VERSION ""

NS_ :

BS_:

BU_: TESTECU BIANSUXIANG SCR EBSECU DisPlay EngineECU

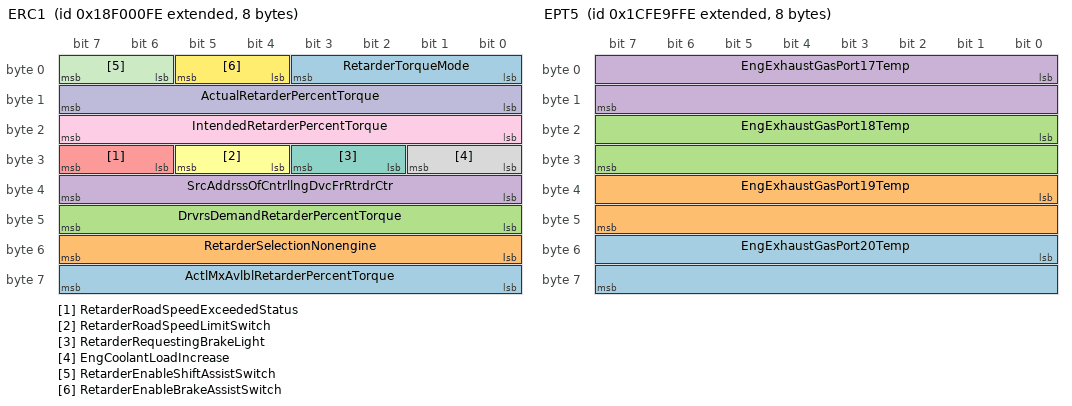
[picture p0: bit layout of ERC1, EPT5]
BO_ 2565865726 ERC1: 8 Vector__XXX
 SG_ ActlMxAvlblRetarderPercentTorque : 56|8@1+ (1,-125) [-125|125] "%" Vector__XXX
 SG_ RetarderSelectionNonengine : 48|8@1+ (0.4,0) [0|100] "%" Vector__XXX
 SG_ DrvrsDemandRetarderPercentTorque : 40|8@1+ (1,-125) [-125|125] "%" Vector__XXX
 SG_ SrcAddrssOfCntrllngDvcFrRtrdrCtr : 32|8@1+ (1,0) [0|255] "" Vector__XXX
 SG_ RetarderRoadSpeedExceededStatus : 30|2@1+ (1,0) [0|3] "" Vector__XXX
 SG_ RetarderRoadSpeedLimitSwitch : 28|2@1+ (1,0) [0|3] "" Vector__XXX
 SG_ RetarderRequestingBrakeLight : 26|2@1+ (1,0) [0|3] "" Vector__XXX
 SG_ EngCoolantLoadIncrease : 24|2@1+ (1,0) [0|3] "" Vector__XXX
 SG_ IntendedRetarderPercentTorque : 16|8@1+ (1,-125) [-125|125] "%" Vector__XXX
 SG_ ActualRetarderPercentTorque : 8|8@1+ (1,-125) [-125|125] "%" Vector__XXX
 SG_ RetarderEnableShiftAssistSwitch : 6|2@1+ (1,0) [0|3] "" Vector__XXX
 SG_ RetarderEnableBrakeAssistSwitch : 4|2@1+ (1,0) [0|3] "" Vector__XXX
 SG_ RetarderTorqueMode : 0|4@1+ (1,0) [0|15] "" Vector__XXX

BO_ 2633932798 EPT5: 8 Vector__XXX
 SG_ EngExhaustGasPort20Temp : 48|16@1+ (0.03125,-273) [-273|1734.96875] "deg C" Vector__XXX
 SG_ EngExhaustGasPort19Temp : 32|16@1+ (0.03125,-273) [-273|1734.96875] "deg C" Vector__XXX
 SG_ EngExhaustGasPort18Temp : 16|16@1+ (0.03125,-273) [-273|1734.96875] "deg C" Vector__XXX
 SG_ EngExhaustGasPort17Temp : 0|16@1+ (0.03125,-273) [-273|1734.96875] "deg C" Vector__XXX

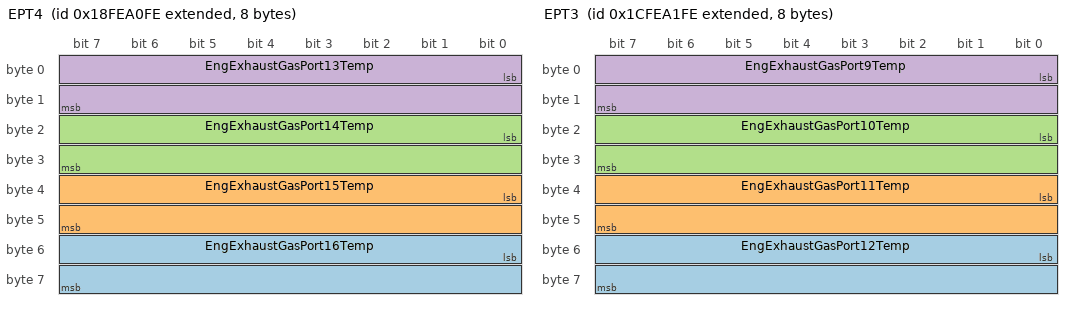
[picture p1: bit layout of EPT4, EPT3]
BO_ 2566824190 EPT4: 8 Vector__XXX
 SG_ EngExhaustGasPort16Temp : 48|16@1+ (0.03125,-273) [-273|1734.96875] "deg C" Vector__XXX
 SG_ EngExhaustGasPort15Temp : 32|16@1+ (0.03125,-273) [-273|1734.96875] "deg C" Vector__XXX
 SG_ EngExhaustGasPort14Temp : 16|16@1+ (0.03125,-273) [-273|1734.96875] "deg C" Vector__XXX
 SG_ EngExhaustGasPort13Temp : 0|16@1+ (0.03125,-273) [-273|1734.96875] "deg C" Vector__XXX

BO_ 2633933310 EPT3: 8 Vector__XXX
 SG_ EngExhaustGasPort12Temp : 48|16@1+ (0.03125,-273) [-273|1734.96875] "deg C" Vector__XXX
 SG_ EngExhaustGasPort11Temp : 32|16@1+ (0.03125,-273) [-273|1734.96875] "deg C" Vector__XXX
 SG_ EngExhaustGasPort10Temp : 16|16@1+ (0.03125,-273) [-273|1734.96875] "deg C" Vector__XXX
 SG_ EngExhaustGasPort9Temp : 0|16@1+ (0.03125,-273) [-273|1734.96875] "deg C" Vector__XXX

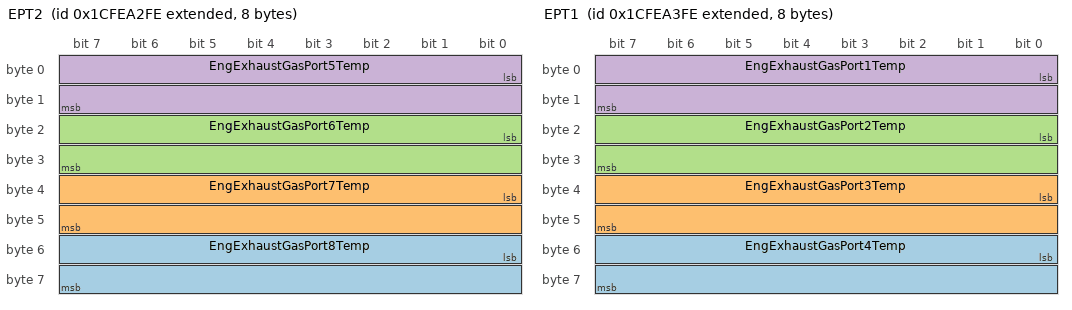
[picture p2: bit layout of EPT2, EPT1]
BO_ 2633933566 EPT2: 8 Vector__XXX
 SG_ EngExhaustGasPort8Temp : 48|16@1+ (0.03125,-273) [-273|1734.96875] "deg C" Vector__XXX
 SG_ EngExhaustGasPort7Temp : 32|16@1+ (0.03125,-273) [-273|1734.96875] "deg C" Vector__XXX
 SG_ EngExhaustGasPort6Temp : 16|16@1+ (0.03125,-273) [-273|1734.96875] "deg C" Vector__XXX
 SG_ EngExhaustGasPort5Temp : 0|16@1+ (0.03125,-273) [-273|1734.96875] "deg C" Vector__XXX

BO_ 2633933822 EPT1: 8 Vector__XXX
 SG_ EngExhaustGasPort4Temp : 48|16@1+ (0.03125,-273) [-273|1734.96875] "deg C" Vector__XXX
 SG_ EngExhaustGasPort3Temp : 32|16@1+ (0.03125,-273) [-273|1734.96875] "deg C" Vector__XXX
 SG_ EngExhaustGasPort2Temp : 16|16@1+ (0.03125,-273) [-273|1734.96875] "deg C" Vector__XXX
 SG_ EngExhaustGasPort1Temp : 0|16@1+ (0.03125,-273) [-273|1734.96875] "deg C" Vector__XXX

BO_ 2566776062 EPD: 8 Vector__XXX
 SG_ PayloadPercentage : 0|8@1+ (1,0) [0|250] "%" Vector__XXX

BO_ 2566771454 EP: 8 Vector__XXX
 SG_ DataMemoryUsage : 16|8@1+ (0.4,0) [0|100] "%" Vector__XXX
 SG_ KeepAliveBatteryConsumption : 0|16@1+ (1,0) [0|64255] "mAhr" Vector__XXX

BO_ 2566775806 EOAC: 8 Vector__XXX
 SG_ TravelVelocityCtrlPos : 0|8@1+ (1,-125) [-125|125] "%" Vector__XXX

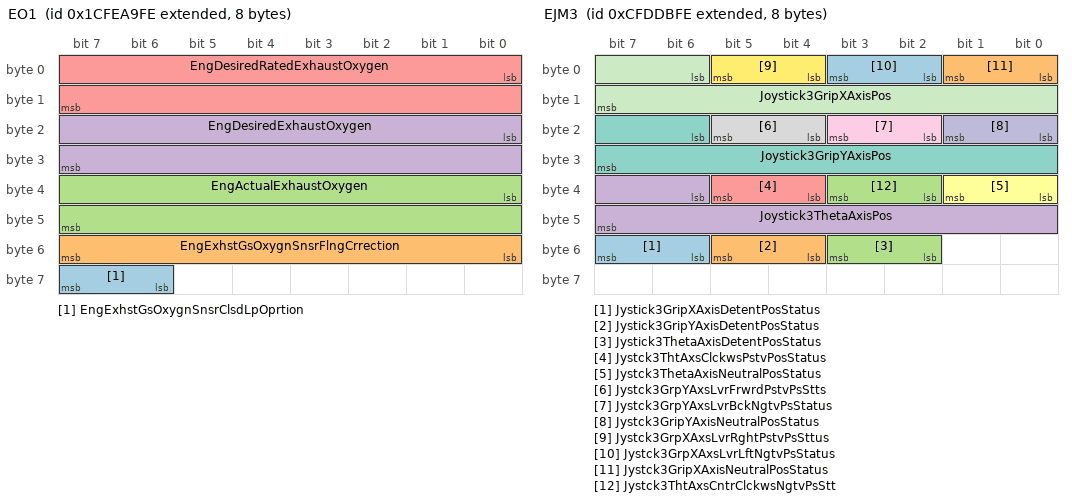
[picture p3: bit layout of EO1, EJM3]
BO_ 2633935358 EO1: 8 Vector__XXX
 SG_ EngExhstGsOxygnSnsrClsdLpOprtion : 62|2@1+ (1,0) [0|3] "" Vector__XXX
 SG_ EngExhstGsOxygnSnsrFlngCrrection : 48|8@1+ (1,-125) [-125|125] "%" Vector__XXX
 SG_ EngActualExhaustOxygen : 32|16@1+ (0.0025,0) [0|160.6375] "%" Vector__XXX
 SG_ EngDesiredExhaustOxygen : 16|16@1+ (0.0025,0) [0|160.6375] "%" Vector__XXX
 SG_ EngDesiredRatedExhaustOxygen : 0|16@1+ (0.0025,0) [0|160.6375] "%" Vector__XXX

BO_ 2365447166 EJM3: 8 Vector__XXX
 SG_ Jystick3GripXAxisDetentPosStatus : 54|2@1+ (1,0) [0|3] "" Vector__XXX
 SG_ Jystick3GripYAxisDetentPosStatus : 52|2@1+ (1,0) [0|3] "" Vector__XXX
 SG_ Jystick3ThetaAxisDetentPosStatus : 50|2@1+ (1,0) [0|3] "" Vector__XXX
 SG_ Joystick3ThetaAxisPos : 38|10@1+ (0.1,0) [0|102] "%" Vector__XXX
 SG_ Jystck3ThtAxsClckwsPstvPosStatus : 36|2@1+ (1,0) [0|3] "" Vector__XXX
 SG_ Jystck3ThetaAxisNeutralPosStatus : 32|2@1+ (1,0) [0|3] "" Vector__XXX
 SG_ Joystick3GripYAxisPos : 22|10@1+ (0.1,0) [0|102] "%" Vector__XXX
 SG_ Jystck3GrpYAxsLvrFrwrdPstvPsStts : 20|2@1+ (1,0) [0|3] "" Vector__XXX
 SG_ Jystck3GrpYAxsLvrBckNgtvPsStatus : 18|2@1+ (1,0) [0|3] "" Vector__XXX
 SG_ Jystck3GripYAxisNeutralPosStatus : 16|2@1+ (1,0) [0|3] "" Vector__XXX
 SG_ Joystick3GripXAxisPos : 6|10@1+ (0.1,0) [0|102] "%" Vector__XXX
 SG_ Jystck3GrpXAxsLvrRghtPstvPsSttus : 4|2@1+ (1,0) [0|3] "" Vector__XXX
 SG_ Jystck3GrpXAxsLvrLftNgtvPsStatus : 2|2@1+ (1,0) [0|3] "" Vector__XXX
 SG_ Jystck3GripXAxisNeutralPosStatus : 0|2@1+ (1,0) [0|3] "" Vector__XXX
 SG_ Jystck3ThtAxsCntrClckwsNgtvPsStt : 34|2@1+ (1,0) [0|3] "" Vector__XXX

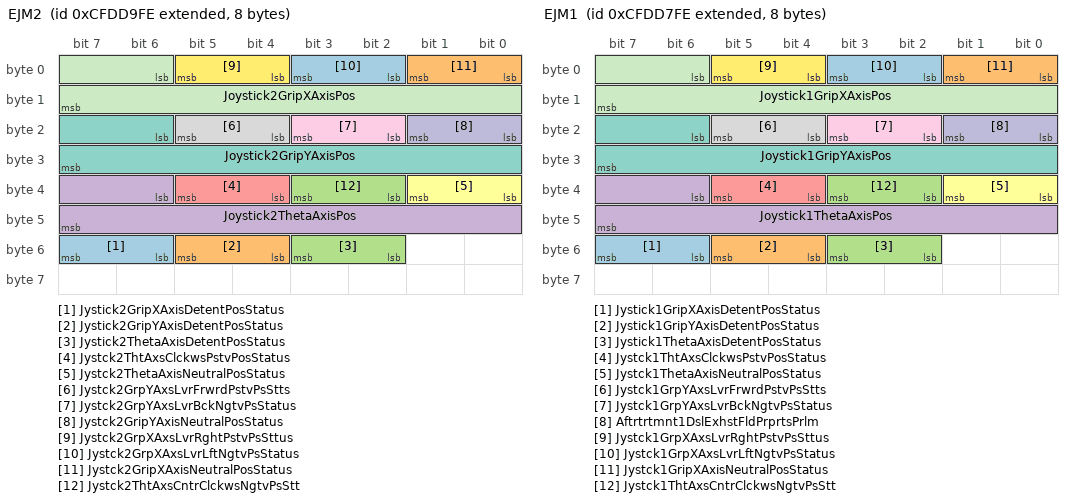
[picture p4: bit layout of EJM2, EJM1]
BO_ 2365446654 EJM2: 8 Vector__XXX
 SG_ Jystick2GripXAxisDetentPosStatus : 54|2@1+ (1,0) [0|3] "" Vector__XXX
 SG_ Jystick2GripYAxisDetentPosStatus : 52|2@1+ (1,0) [0|3] "" Vector__XXX
 SG_ Jystick2ThetaAxisDetentPosStatus : 50|2@1+ (1,0) [0|3] "" Vector__XXX
 SG_ Joystick2ThetaAxisPos : 38|10@1+ (0.1,0) [0|102] "%" Vector__XXX
 SG_ Jystck2ThtAxsClckwsPstvPosStatus : 36|2@1+ (1,0) [0|3] "" Vector__XXX
 SG_ Jystck2ThetaAxisNeutralPosStatus : 32|2@1+ (1,0) [0|3] "" Vector__XXX
 SG_ Joystick2GripYAxisPos : 22|10@1+ (0.1,0) [0|102] "%" Vector__XXX
 SG_ Jystck2GrpYAxsLvrFrwrdPstvPsStts : 20|2@1+ (1,0) [0|3] "" Vector__XXX
 SG_ Jystck2GrpYAxsLvrBckNgtvPsStatus : 18|2@1+ (1,0) [0|3] "" Vector__XXX
 SG_ Jystck2GripYAxisNeutralPosStatus : 16|2@1+ (1,0) [0|3] "" Vector__XXX
 SG_ Joystick2GripXAxisPos : 6|10@1+ (0.1,0) [0|102] "%" Vector__XXX
 SG_ Jystck2GrpXAxsLvrRghtPstvPsSttus : 4|2@1+ (1,0) [0|3] "" Vector__XXX
 SG_ Jystck2GrpXAxsLvrLftNgtvPsStatus : 2|2@1+ (1,0) [0|3] "" Vector__XXX
 SG_ Jystck2GripXAxisNeutralPosStatus : 0|2@1+ (1,0) [0|3] "" Vector__XXX
 SG_ Jystck2ThtAxsCntrClckwsNgtvPsStt : 34|2@1+ (1,0) [0|3] "" Vector__XXX

BO_ 2365446142 EJM1: 8 Vector__XXX
 SG_ Jystick1GripXAxisDetentPosStatus : 54|2@1+ (1,0) [0|3] "" Vector__XXX
 SG_ Jystick1GripYAxisDetentPosStatus : 52|2@1+ (1,0) [0|3] "" Vector__XXX
 SG_ Jystick1ThetaAxisDetentPosStatus : 50|2@1+ (1,0) [0|3] "" Vector__XXX
 SG_ Joystick1ThetaAxisPos : 38|10@1+ (0.1,0) [0|102] "%" Vector__XXX
 SG_ Jystck1ThtAxsClckwsPstvPosStatus : 36|2@1+ (1,0) [0|3] "" Vector__XXX
 SG_ Jystck1ThetaAxisNeutralPosStatus : 32|2@1+ (1,0) [0|3] "" Vector__XXX
 SG_ Joystick1GripYAxisPos : 22|10@1+ (0.1,0) [0|102] "%" Vector__XXX
 SG_ Jystck1GrpYAxsLvrFrwrdPstvPsStts : 20|2@1+ (1,0) [0|3] "" Vector__XXX
 SG_ Jystck1GrpYAxsLvrBckNgtvPsStatus : 18|2@1+ (1,0) [0|3] "" Vector__XXX
 SG_ Aftrtrtmnt1DslExhstFldPrprtsPrlm : 16|2@1+ (1,0) [0|3] "" Vector__XXX
 SG_ Joystick1GripXAxisPos : 6|10@1+ (0.1,0) [0|102] "%" Vector__XXX
 SG_ Jystck1GrpXAxsLvrRghtPstvPsSttus : 4|2@1+ (1,0) [0|3] "" Vector__XXX
 SG_ Jystck1GrpXAxsLvrLftNgtvPsStatus : 2|2@1+ (1,0) [0|3] "" Vector__XXX
 SG_ Jystck1GripXAxisNeutralPosStatus : 0|2@1+ (1,0) [0|3] "" Vector__XXX
 SG_ Jystck1ThtAxsCntrClckwsNgtvPsStt : 34|2@1+ (1,0) [0|3] "" Vector__XXX

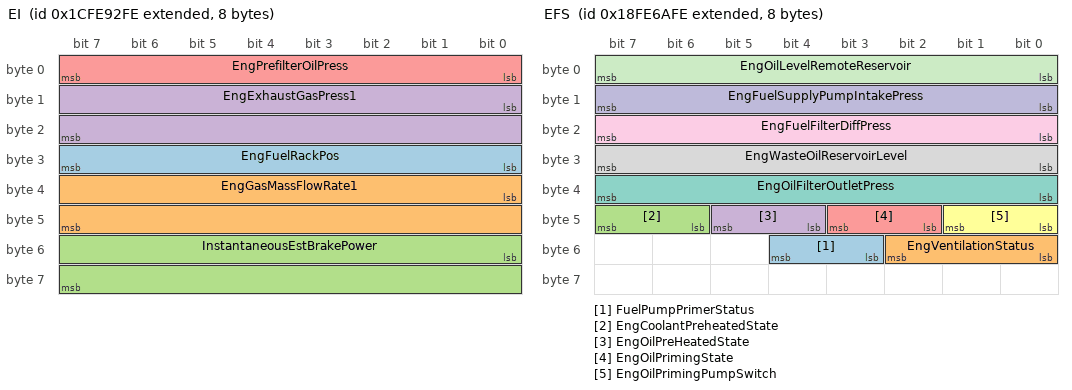
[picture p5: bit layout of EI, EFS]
BO_ 2633929470 EI: 8 Vector__XXX
 SG_ EngFuelRackPos : 24|8@1+ (0.4,0) [0|100] "%" Vector__XXX
 SG_ EngGasMassFlowRate1 : 32|16@1+ (0.05,0) [0|3212.75] "kg/h" Vector__XXX
 SG_ InstantaneousEstBrakePower : 48|16@1+ (0.5,0) [0|32127.5] "kW" Vector__XXX
 SG_ EngExhaustGasPress1 : 8|16@1+ (0.0078125,-250) [-250|251.99] "kPa" Vector__XXX
 SG_ EngPrefilterOilPress : 0|8@1+ (4,0) [0|1000] "kPa" Vector__XXX

BO_ 2633937406 EH: 8 Vector__XXX
 SG_ TotalECURunTime : 32|32@1+ (0.05,0) [0|210554060.75] "hr" Vector__XXX
 SG_ TotalECUDistance : 0|32@1+ (0.125,0) [0|526385151.9] "km" Vector__XXX

BO_ 2364541694 EGF1: 8 Vector__XXX
 SG_ EngExhstGsRcrcltion2MassFlowRate : 32|16@1+ (0.05,0) [0|3212.75] "kg/h" Vector__XXX
 SG_ EngIntakeAirMassFlowRate : 16|16@1+ (0.05,0) [0|3212.75] "kg/h" Vector__XXX
 SG_ EngExhstGsRcrcltion1MassFlowRate : 0|16@1+ (0.05,0) [0|3212.75] "kg/h" Vector__XXX

BO_ 2566810366 EFS: 8 Vector__XXX
 SG_ FuelPumpPrimerStatus : 51|2@1+ (1,0) [0|3] "" Vector__XXX
 SG_ EngVentilationStatus : 48|3@1+ (1,0) [0|7] "" Vector__XXX
 SG_ EngCoolantPreheatedState : 46|2@1+ (1,0) [0|3] "" Vector__XXX
 SG_ EngOilPreHeatedState : 44|2@1+ (1,0) [0|3] "" Vector__XXX
 SG_ EngOilPrimingState : 42|2@1+ (1,0) [0|3] "" Vector__XXX
 SG_ EngOilPrimingPumpSwitch : 40|2@1+ (1,0) [0|3] "" Vector__XXX
 SG_ EngOilFilterOutletPress : 32|8@1+ (4,0) [0|1000] "kPa" Vector__XXX
 SG_ EngWasteOilReservoirLevel : 24|8@1+ (0.4,0) [0|100] "%" Vector__XXX
 SG_ EngFuelFilterDiffPress : 16|8@1+ (2,0) [0|500] "kPa" Vector__XXX
 SG_ EngFuelSupplyPumpIntakePress : 8|8@1+ (2,0) [0|500] "kPa" Vector__XXX
 SG_ EngOilLevelRemoteReservoir : 0|8@1+ (0.4,0) [0|100] "%" Vector__XXX

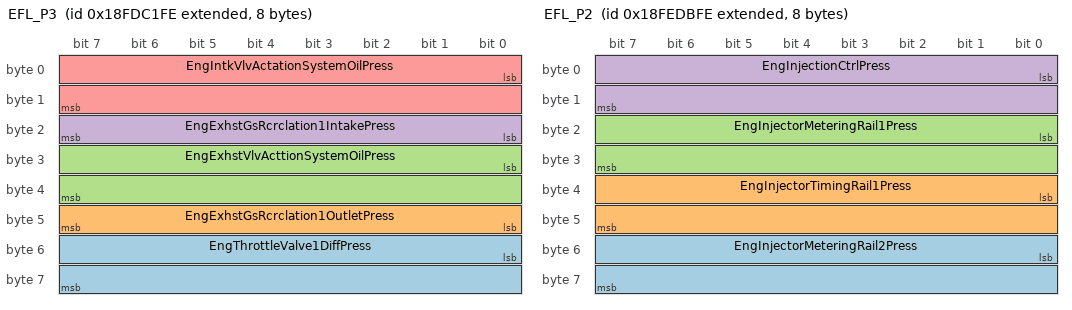
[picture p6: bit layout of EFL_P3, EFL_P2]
BO_ 2566767102 EFL_P3: 8 Vector__XXX
 SG_ EngThrottleValve1DiffPress : 48|16@1+ (0.1,0) [0|6425.5] "kPa" Vector__XXX
 SG_ EngExhstGsRcrclation1OutletPress : 40|8@1+ (2,0) [0|500] "kPa" Vector__XXX
 SG_ EngExhstVlvActtionSystemOilPress : 24|16@1+ (0.00390625,0) [0|250.996] "Mpa" Vector__XXX
 SG_ EngExhstGsRcrclation1IntakePress : 16|8@1+ (2,0) [0|500] "kPa" Vector__XXX
 SG_ EngIntkVlvActationSystemOilPress : 0|16@1+ (0.00390625,0) [0|250.996] "Mpa" Vector__XXX

BO_ 2566839294 EFL_P2: 8 Vector__XXX
 SG_ EngInjectorMeteringRail2Press : 48|16@1+ (0.00390625,0) [0|250.996] "Mpa" Vector__XXX
 SG_ EngInjectorTimingRail1Press : 32|16@1+ (0.00390625,0) [0|250.996] "Mpa" Vector__XXX
 SG_ EngInjectorMeteringRail1Press : 16|16@1+ (0.00390625,0) [0|250.996] "Mpa" Vector__XXX
 SG_ EngInjectionCtrlPress : 0|16@1+ (0.00390625,0) [0|250.996] "Mpa" Vector__XXX

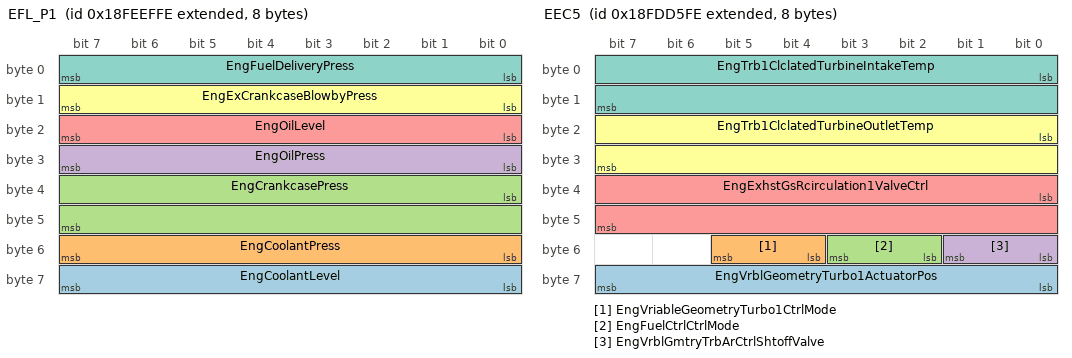
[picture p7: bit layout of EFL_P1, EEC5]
BO_ 2566844414 EFL_P1: 8 Vector__XXX
 SG_ EngCoolantLevel : 56|8@1+ (0.4,0) [0|100] "%" Vector__XXX
 SG_ EngCoolantPress : 48|8@1+ (2,0) [0|500] "kPa" Vector__XXX
 SG_ EngCrankcasePress : 32|16@1+ (0.0078125,-250) [-250|251.99] "kPa" Vector__XXX
 SG_ EngOilPress : 24|8@1+ (4,0) [0|1000] "kPa" Vector__XXX
 SG_ EngOilLevel : 16|8@1+ (0.4,0) [0|100] "%" Vector__XXX
 SG_ EngExCrankcaseBlowbyPress : 8|8@1+ (0.05,0) [0|12.5] "kPa" Vector__XXX
 SG_ EngFuelDeliveryPress : 0|8@1+ (4,0) [0|1000] "kPa" Vector__XXX

BO_ 2633929726 EES: 8 Vector__XXX
 SG_ SafetyWireStatus : 16|2@1+ (1,0) [0|3] "" Vector__XXX
 SG_ ElectricalLoad : 0|16@1+ (0.5,0) [0|32127.5] "kW" Vector__XXX

BO_ 2566772222 EEC5: 8 Vector__XXX
 SG_ EngVrblGeometryTurbo1ActuatorPos : 56|8@1+ (0.4,0) [0|100] "%" Vector__XXX
 SG_ EngVriableGeometryTurbo1CtrlMode : 52|2@1+ (1,0) [0|3] "" Vector__XXX
 SG_ EngFuelCtrlCtrlMode : 50|2@1+ (1,0) [0|3] "" Vector__XXX
 SG_ EngVrblGmtryTrbArCtrlShtoffValve : 48|2@1+ (1,0) [0|3] "" Vector__XXX
 SG_ EngExhstGsRcirculation1ValveCtrl : 32|16@1+ (0.0025,0) [0|160.6375] "%" Vector__XXX
 SG_ EngTrb1ClclatedTurbineOutletTemp : 16|16@1+ (0.03125,-273) [-273|1734.96875] "deg C" Vector__XXX
 SG_ EngTrb1ClclatedTurbineIntakeTemp : 0|16@1+ (0.03125,-273) [-273|1734.96875] "deg C" Vector__XXX

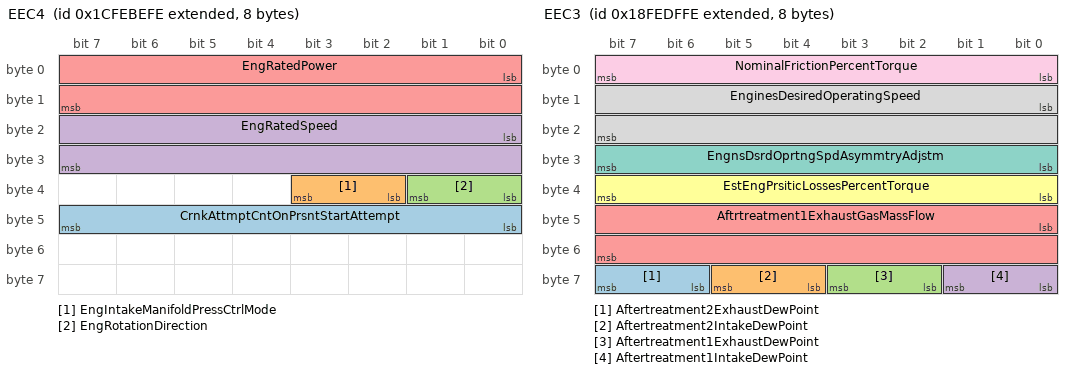
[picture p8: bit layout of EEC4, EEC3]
BO_ 2633940734 EEC4: 8 Vector__XXX
 SG_ CrnkAttmptCntOnPrsntStartAttempt : 40|8@1+ (1,0) [0|250] "" Vector__XXX
 SG_ EngIntakeManifoldPressCtrlMode : 34|2@1+ (1,0) [0|3] "" Vector__XXX
 SG_ EngRotationDirection : 32|2@1+ (1,0) [0|3] "" Vector__XXX
 SG_ EngRatedSpeed : 16|16@1+ (0.125,0) [0|8031.875] "rpm" Vector__XXX
 SG_ EngRatedPower : 0|16@1+ (0.5,0) [0|32127.5] "kW" Vector__XXX

BO_ 2566840318 EEC3: 8 Vector__XXX
 SG_ Aftertreatment2ExhaustDewPoint : 62|2@1+ (1,0) [0|3] "" Vector__XXX
 SG_ Aftertreatment2IntakeDewPoint : 60|2@1+ (1,0) [0|3] "" Vector__XXX
 SG_ Aftertreatment1ExhaustDewPoint : 58|2@1+ (1,0) [0|3] "" Vector__XXX
 SG_ Aftertreatment1IntakeDewPoint : 56|2@1+ (1,0) [0|3] "" Vector__XXX
 SG_ Aftrtreatment1ExhaustGasMassFlow : 40|16@1+ (0.2,0) [0|12851] "kg/h per bit" Vector__XXX
 SG_ EstEngPrsiticLossesPercentTorque : 32|8@1+ (1,-125) [-125|125] "%" Vector__XXX
 SG_ EngnsDsrdOprtngSpdAsymmtryAdjstm : 24|8@1+ (1,0) [0|250] "" Vector__XXX
 SG_ EnginesDesiredOperatingSpeed : 8|16@1+ (0.125,0) [0|8031.875] "rpm" Vector__XXX
 SG_ NominalFrictionPercentTorque : 0|8@1+ (1,-125) [-125|125] "%" Vector__XXX

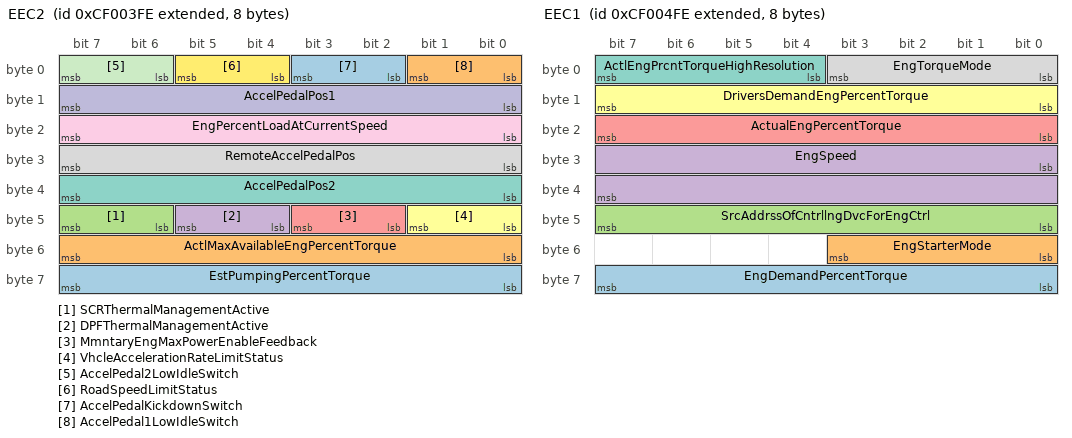
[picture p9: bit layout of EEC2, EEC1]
BO_ 2364539902 EEC2: 8 Vector__XXX
 SG_ EstPumpingPercentTorque : 56|8@1+ (1,-125) [-125|125] "%" Vector__XXX
 SG_ ActlMaxAvailableEngPercentTorque : 48|8@1+ (0.4,0) [0|100] "%" Vector__XXX
 SG_ SCRThermalManagementActive : 46|2@1+ (1,0) [0|3] "" Vector__XXX
 SG_ DPFThermalManagementActive : 44|2@1+ (1,0) [0|3] "" Vector__XXX
 SG_ MmntaryEngMaxPowerEnableFeedback : 42|2@1+ (1,0) [0|3] "" Vector__XXX
 SG_ VhcleAccelerationRateLimitStatus : 40|2@1+ (1,0) [0|3] "" Vector__XXX
 SG_ AccelPedalPos2 : 32|8@1+ (0.4,0) [0|100] "%" Vector__XXX
 SG_ RemoteAccelPedalPos : 24|8@1+ (0.4,0) [0|100] "%" Vector__XXX
 SG_ EngPercentLoadAtCurrentSpeed : 16|8@1+ (1,0) [0|250] "%" Vector__XXX
 SG_ AccelPedalPos1 : 8|8@1+ (0.4,0) [0|100] "%" Vector__XXX
 SG_ AccelPedal2LowIdleSwitch : 6|2@1+ (1,0) [0|3] "" Vector__XXX
 SG_ RoadSpeedLimitStatus : 4|2@1+ (1,0) [0|3] "" Vector__XXX
 SG_ AccelPedalKickdownSwitch : 2|2@1+ (1,0) [0|3] "" Vector__XXX
 SG_ AccelPedal1LowIdleSwitch : 0|2@1+ (1,0) [0|3] "" Vector__XXX

BO_ 2364540158 EEC1: 8 Vector__XXX
 SG_ EngDemandPercentTorque : 56|8@1+ (1,-125) [-125|125] "%" Vector__XXX
 SG_ EngStarterMode : 48|4@1+ (1,0) [0|15] "" Vector__XXX
 SG_ SrcAddrssOfCntrllngDvcForEngCtrl : 40|8@1+ (1,0) [0|255] "" Vector__XXX
 SG_ EngSpeed : 24|16@1+ (0.125,0) [0|8031.875] "rpm" Vector__XXX
 SG_ ActualEngPercentTorque : 16|8@1+ (1,-125) [-125|125] "%" Vector__XXX
 SG_ DriversDemandEngPercentTorque : 8|8@1+ (1,-125) [-125|125] "%" Vector__XXX
 SG_ ActlEngPrcntTorqueHighResolution : 4|4@1+ (0.125,0) [0|0.875] "%" Vector__XXX
 SG_ EngTorqueMode : 0|4@1+ (1,0) [0|15] "" Vector__XXX

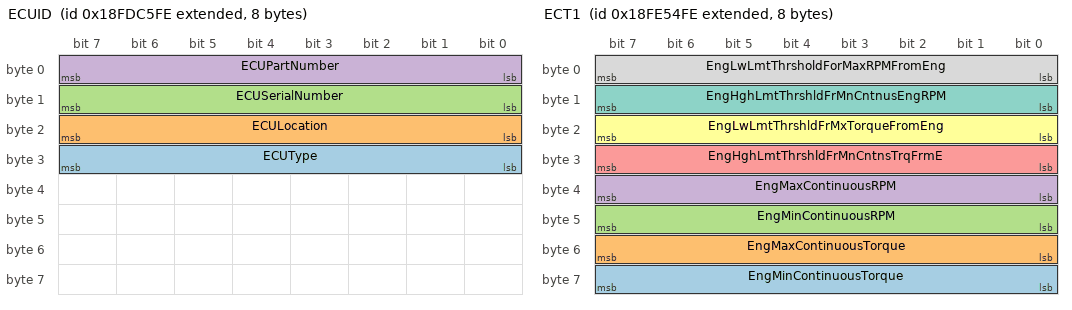
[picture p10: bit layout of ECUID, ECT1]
BO_ 2566768126 ECUID: 8 Vector__XXX
 SG_ ECUType : 24|8@1+ (1,0) [0|255] "per byte" Vector__XXX
 SG_ ECULocation : 16|8@1+ (1,0) [0|255] "per byte" Vector__XXX
 SG_ ECUSerialNumber : 8|8@1+ (1,0) [0|255] "per byte" Vector__XXX
 SG_ ECUPartNumber : 0|8@1+ (1,0) [0|255] "per byte" Vector__XXX

BO_ 2566804734 ECT1: 8 Vector__XXX
 SG_ EngMinContinuousTorque : 56|8@1+ (1,-125) [-125|125] "%" Vector__XXX
 SG_ EngMaxContinuousTorque : 48|8@1+ (1,-125) [-125|125] "%" Vector__XXX
 SG_ EngMinContinuousRPM : 40|8@1+ (32,0) [0|8000] "rpm" Vector__XXX
 SG_ EngMaxContinuousRPM : 32|8@1+ (32,0) [0|8000] "rpm" Vector__XXX
 SG_ EngHghLmtThrshldFrMnCntnsTrqFrmE : 24|8@1+ (1,-125) [-125|125] "%" Vector__XXX
 SG_ EngLwLmtThrshldFrMxTorqueFromEng : 16|8@1+ (1,-125) [-125|125] "%" Vector__XXX
 SG_ EngHghLmtThrshldFrMnCntnusEngRPM : 8|8@1+ (32,0) [0|8000] "rpm" Vector__XXX
 SG_ EngLwLmtThrsholdForMaxRPMFromEng : 0|8@1+ (32,0) [0|8000] "rpm" Vector__XXX

BO_ 2566841342 EC1: 39 Vector__XXX
 SG_ SupportTSC1CtrlPurposeGroup4 : 304|8@1+ (1,0) [0|255] "" Vector__XXX
 SG_ SupportTSC1CtrlPurposeGroup3 : 296|8@1+ (1,0) [0|255] "" Vector__XXX
 SG_ SupportTSC1CtrlPurposeGroup2 : 288|8@1+ (1,0) [0|255] "" Vector__XXX
 SG_ SupportTSC1CtrlPurposeGroup1 : 280|8@1+ (1,0) [0|255] "" Vector__XXX
 SG_ SupportVariableRateTSC1Message : 272|8@1+ (1,0) [0|255] "" Vector__XXX
 SG_ EngDefaultTorqueLimit : 256|16@1+ (1,0) [0|64255] "Nm" Vector__XXX
 SG_ EngMomentOfInertia : 240|16@1+ (0.004,0) [0|257.02] "kg-m^2" Vector__XXX
 SG_ EngExRngRqstdSpdCtrlRngUpprLimit : 224|16@1+ (0.125,0) [0|8031.875] "rpm" Vector__XXX
 SG_ EngRqstdTrqueCtrlRangeUpperLimit : 216|8@1+ (1,-125) [-125|125] "%" Vector__XXX
 SG_ EngRqstdTrqueCtrlRangeLowerLimit : 208|8@1+ (1,-125) [-125|125] "%" Vector__XXX
 SG_ EngRqstdSpeedCtrlRangeUpperLimit : 200|8@1+ (10,0) [0|2500] "rpm" Vector__XXX
 SG_ EngRqstdSpeedCtrlRangeLowerLimit : 192|8@1+ (10,0) [0|2500] "rpm" Vector__XXX
 SG_ EngMaxMomentaryOverrideTimeLimit : 184|8@1+ (0.1,0) [0|25] "s" Vector__XXX
 SG_ EngMxMmentaryOverrideSpeedPoint7 : 168|16@1+ (0.125,0) [0|8031.875] "rpm" Vector__XXX
 SG_ EngReferenceTorque : 152|16@1+ (1,0) [0|64255] "Nm" Vector__XXX
 SG_ EngGain : 136|16@1+ (0.00078125,0) [0|50.2] "%/rpm" Vector__XXX
 SG_ EngSpeedAtHighIdlePoint6 : 120|16@1+ (0.125,0) [0|8031.875] "rpm" Vector__XXX
 SG_ EngPercentTorqueAtPoint5 : 112|8@1+ (1,-125) [-125|125] "%" Vector__XXX
 SG_ EngSpeedAtPoint5 : 96|16@1+ (0.125,0) [0|8031.875] "rpm" Vector__XXX
 SG_ EngPercentTorqueAtPoint4 : 88|8@1+ (1,-125) [-125|125] "%" Vector__XXX
 SG_ EngSpeedAtPoint4 : 72|16@1+ (0.125,0) [0|8031.875] "rpm" Vector__XXX
 SG_ EngPercentTorqueAtPoint3 : 64|8@1+ (1,-125) [-125|125] "%" Vector__XXX
 SG_ EngSpeedAtPoint3 : 48|16@1+ (0.125,0) [0|8031.875] "rpm" Vector__XXX
 SG_ EngPercentTorqueAtPoint2 : 40|8@1+ (1,-125) [-125|125] "%" Vector__XXX
 SG_ EngSpeedAtPoint2 : 24|16@1+ (0.125,0) [0|8031.875] "rpm" Vector__XXX
 SG_ EngPercentTorqueAtIdlePoint1 : 16|8@1+ (1,-125) [-125|125] "%" Vector__XXX
 SG_ EngSpeedAtIdlePoint1 : 0|16@1+ (0.125,0) [0|8031.875] "rpm" Vector__XXX

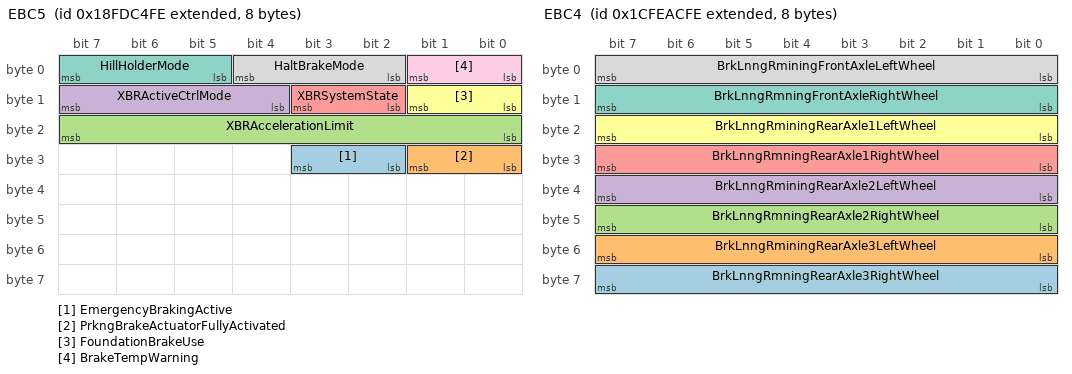
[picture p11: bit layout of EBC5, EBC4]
BO_ 2566767870 EBC5: 8 Vector__XXX
 SG_ EmergencyBrakingActive : 26|2@1+ (1,0) [0|3] "" Vector__XXX
 SG_ PrkngBrakeActuatorFullyActivated : 24|2@1+ (1,0) [0|3] "" Vector__XXX
 SG_ XBRAccelerationLimit : 16|8@1+ (0.1,-12.5) [-12.5|12.5] "m/s²" Vector__XXX
 SG_ XBRActiveCtrlMode : 12|4@1+ (1,0) [0|15] "" Vector__XXX
 SG_ XBRSystemState : 10|2@1+ (1,0) [0|3] "" Vector__XXX
 SG_ FoundationBrakeUse : 8|2@1+ (1,0) [0|3] "" Vector__XXX
 SG_ HillHolderMode : 5|3@1+ (1,0) [0|7] "" Vector__XXX
 SG_ HaltBrakeMode : 2|3@1+ (1,0) [0|7] "" Vector__XXX
 SG_ BrakeTempWarning : 0|2@1+ (1,0) [0|3] "" Vector__XXX

BO_ 2633936126 EBC4: 8 Vector__XXX
 SG_ BrkLnngRmningRearAxle3RightWheel : 56|8@1+ (0.4,0) [0|100] "%" Vector__XXX
 SG_ BrkLnngRminingRearAxle3LeftWheel : 48|8@1+ (0.4,0) [0|100] "%" Vector__XXX
 SG_ BrkLnngRmningRearAxle2RightWheel : 40|8@1+ (0.4,0) [0|100] "%" Vector__XXX
 SG_ BrkLnngRminingRearAxle2LeftWheel : 32|8@1+ (0.4,0) [0|100] "%" Vector__XXX
 SG_ BrkLnngRmningRearAxle1RightWheel : 24|8@1+ (0.4,0) [0|100] "%" Vector__XXX
 SG_ BrkLnngRminingRearAxle1LeftWheel : 16|8@1+ (0.4,0) [0|100] "%" Vector__XXX
 SG_ BrkLnngRmningFrontAxleRightWheel : 8|8@1+ (0.4,0) [0|100] "%" Vector__XXX
 SG_ BrkLnngRminingFrontAxleLeftWheel : 0|8@1+ (0.4,0) [0|100] "%" Vector__XXX

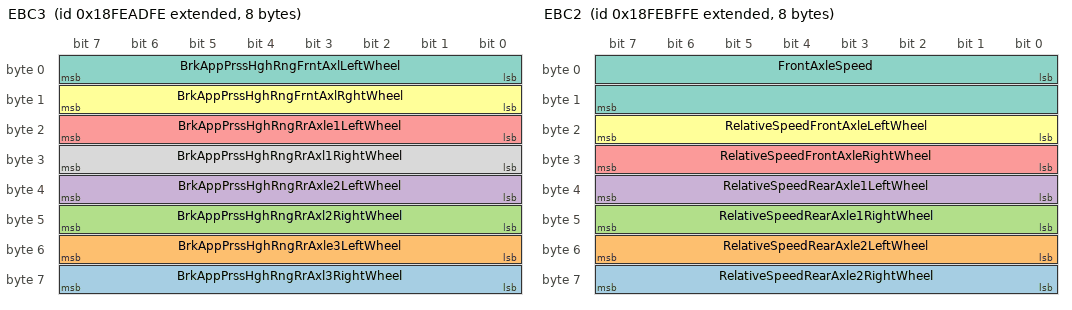
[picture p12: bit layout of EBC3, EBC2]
BO_ 2566827518 EBC3: 8 Vector__XXX
 SG_ BrkAppPrssHghRngRrAxl3RightWheel : 56|8@1+ (5,0) [0|1250] "kPa" Vector__XXX
 SG_ BrkAppPrssHghRngRrAxle3LeftWheel : 48|8@1+ (5,0) [0|1250] "kPa" Vector__XXX
 SG_ BrkAppPrssHghRngRrAxl2RightWheel : 40|8@1+ (5,0) [0|1250] "kPa" Vector__XXX
 SG_ BrkAppPrssHghRngRrAxle2LeftWheel : 32|8@1+ (5,0) [0|1250] "kPa" Vector__XXX
 SG_ BrkAppPrssHghRngRrAxle1LeftWheel : 16|8@1+ (5,0) [0|1250] "kPa" Vector__XXX
 SG_ BrkAppPrssHghRngFrntAxlRghtWheel : 8|8@1+ (5,0) [0|1250] "kPa" Vector__XXX
 SG_ BrkAppPrssHghRngFrntAxlLeftWheel : 0|8@1+ (5,0) [0|1250] "kPa" Vector__XXX
 SG_ BrkAppPrssHghRngRrAxl1RightWheel : 24|8@1+ (5,0) [0|1250] "kPa" Vector__XXX

BO_ 2566832126 EBC2: 8 Vector__XXX
 SG_ RelativeSpeedRearAxle2RightWheel : 56|8@1+ (0.0625,-7.8125) [-7.8125|7.8125] "km/h" Vector__XXX
 SG_ RelativeSpeedRearAxle2LeftWheel : 48|8@1+ (0.0625,-7.8125) [-7.8125|7.8125] "km/h" Vector__XXX
 SG_ RelativeSpeedRearAxle1RightWheel : 40|8@1+ (0.0625,-7.8125) [-7.8125|7.8125] "km/h" Vector__XXX
 SG_ RelativeSpeedRearAxle1LeftWheel : 32|8@1+ (0.0625,-7.8125) [-7.8125|7.8125] "km/h" Vector__XXX
 SG_ RelativeSpeedFrontAxleRightWheel : 24|8@1+ (0.0625,-7.8125) [-7.8125|7.8125] "km/h" Vector__XXX
 SG_ RelativeSpeedFrontAxleLeftWheel : 16|8@1+ (0.0625,-7.8125) [-7.8125|7.8125] "km/h" Vector__XXX
 SG_ FrontAxleSpeed : 0|16@1+ (0.00390625,0) [0|250.996] "km/h" Vector__XXX

BO_ 2565865982 EBC1: 8 Vector__XXX
 SG_ TrctrMntdTrailerABSWarningSignal : 62|2@1+ (1,0) [0|3] "" Vector__XXX
 SG_ TrailerABSStatus : 60|2@1+ (1,0) [0|3] "" Vector__XXX
 SG_ HaltBrakeSwitch : 58|2@1+ (1,0) [0|3] "" Vector__XXX
 SG_ SrcAddrssOfCntrllngDvcFrBrkeCtrl : 48|8@1+ (1,0) [0|255] "" Vector__XXX
 SG_ ATC_ASRInformationSignal : 46|2@1+ (1,0) [0|3] "" Vector__XXX
 SG_ ABS_EBSAmberWarningSignal : 44|2@1+ (1,0) [0|3] "" Vector__XXX
 SG_ EBSRedWarningSignal : 42|2@1+ (1,0) [0|3] "" Vector__XXX
 SG_ ABSFullyOperational : 40|2@1+ (1,0) [0|3] "" Vector__XXX
 SG_ EngRetarderSelection : 32|8@1+ (0.4,0) [0|100] "%" Vector__XXX
 SG_ RemoteAccelEnableSwitch : 30|2@1+ (1,0) [0|3] "" Vector__XXX
 SG_ EngAuxShutdownSwitch : 28|2@1+ (1,0) [0|3] "" Vector__XXX
 SG_ EngDerateSwitch : 26|2@1+ (1,0) [0|3] "" Vector__XXX
 SG_ AccelInterlockSwitch : 24|2@1+ (1,0) [0|3] "" Vector__XXX
 SG_ TractionCtrlOverrideSwitch : 22|2@1+ (1,0) [0|3] "" Vector__XXX
 SG_ ASRHillHolderSwitch : 20|2@1+ (1,0) [0|3] "" Vector__XXX
 SG_ ASROffroadSwitch : 18|2@1+ (1,0) [0|3] "" Vector__XXX
 SG_ ABSOffroadSwitch : 16|2@1+ (1,0) [0|3] "" Vector__XXX
 SG_ BrakePedalPos : 8|8@1+ (0.4,0) [0|100] "%" Vector__XXX
 SG_ EBSBrakeSwitch : 6|2@1+ (1,0) [0|3] "" Vector__XXX
 SG_ AntiLockBrakingActive : 4|2@1+ (1,0) [0|3] "" Vector__XXX
 SG_ ASRBrakeCtrlActive : 2|2@1+ (1,0) [0|3] "" Vector__XXX
 SG_ ASREngCtrlActive : 0|2@1+ (1,0) [0|3] "" Vector__XXX

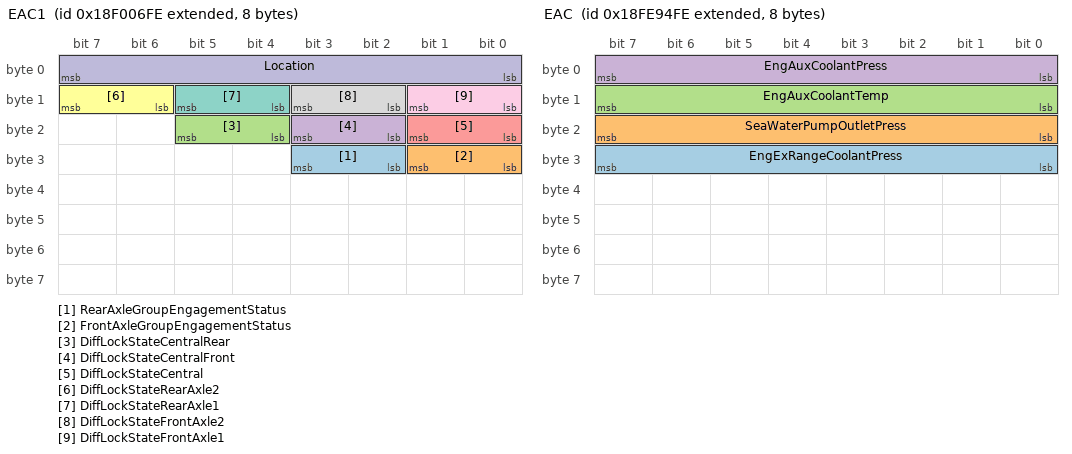
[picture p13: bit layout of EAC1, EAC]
BO_ 2565867262 EAC1: 8 Vector__XXX
 SG_ RearAxleGroupEngagementStatus : 26|2@1+ (1,0) [0|3] "" Vector__XXX
 SG_ FrontAxleGroupEngagementStatus : 24|2@1+ (1,0) [0|3] "" Vector__XXX
 SG_ DiffLockStateCentralRear : 20|2@1+ (1,0) [0|3] "" Vector__XXX
 SG_ DiffLockStateCentralFront : 18|2@1+ (1,0) [0|3] "" Vector__XXX
 SG_ DiffLockStateCentral : 16|2@1+ (1,0) [0|3] "" Vector__XXX
 SG_ DiffLockStateRearAxle2 : 14|2@1+ (1,0) [0|3] "" Vector__XXX
 SG_ DiffLockStateRearAxle1 : 12|2@1+ (1,0) [0|3] "" Vector__XXX
 SG_ DiffLockStateFrontAxle2 : 10|2@1+ (1,0) [0|3] "" Vector__XXX
 SG_ DiffLockStateFrontAxle1 : 8|2@1+ (1,0) [0|3] "" Vector__XXX
 SG_ Location : 0|8@1+ (1,0) [0|255] "" Vector__XXX

BO_ 2566821118 EAC: 8 Vector__XXX
 SG_ EngExRangeCoolantPress : 24|8@1+ (4,0) [0|1000] "kPa" Vector__XXX
 SG_ SeaWaterPumpOutletPress : 16|8@1+ (2,0) [0|500] "kPa" Vector__XXX
 SG_ EngAuxCoolantTemp : 8|8@1+ (1,-40) [-40|210] "deg C" Vector__XXX
 SG_ EngAuxCoolantPress : 0|8@1+ (4,0) [0|1000] "kPa" Vector__XXX

BO_ 2566810622 DI: 8 Vector__XXX
 SG_ Driver2Identification : 8|8@1+ (1,0) [0|255] "per byte" Vector__XXX
 SG_ Driver1Identification : 0|8@1+ (1,0) [0|255] "per byte" Vector__XXX

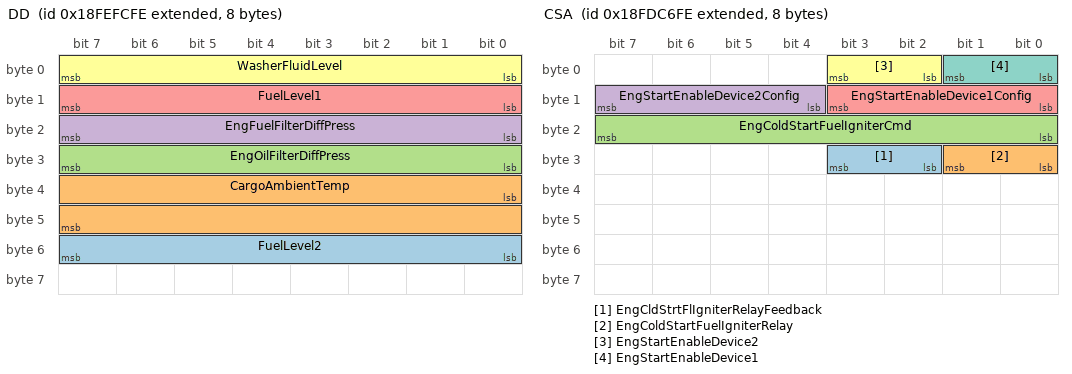
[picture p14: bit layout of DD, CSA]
BO_ 2566847742 DD: 8 Vector__XXX
 SG_ FuelLevel2 : 48|8@1+ (0.4,0) [0|100] "%" Vector__XXX
 SG_ CargoAmbientTemp : 32|16@1+ (0.03125,-273) [-273|1734.96875] "deg C" Vector__XXX
 SG_ EngOilFilterDiffPress : 24|8@1+ (0.5,0) [0|125] "kPa" Vector__XXX
 SG_ EngFuelFilterDiffPress : 16|8@1+ (2,0) [0|500] "kPa" Vector__XXX
 SG_ FuelLevel1 : 8|8@1+ (0.4,0) [0|100] "%" Vector__XXX
 SG_ WasherFluidLevel : 0|8@1+ (0.4,0) [0|100] "%" Vector__XXX

BO_ 2566768382 CSA: 8 Vector__XXX
 SG_ EngCldStrtFlIgniterRelayFeedback : 26|2@1+ (1,0) [0|3] "" Vector__XXX
 SG_ EngColdStartFuelIgniterRelay : 24|2@1+ (1,0) [0|3] "" Vector__XXX
 SG_ EngColdStartFuelIgniterCmd : 16|8@1+ (0.4,0) [0|100] "%" Vector__XXX
 SG_ EngStartEnableDevice2Config : 12|4@1+ (1,0) [0|15] "" Vector__XXX
 SG_ EngStartEnableDevice1Config : 8|4@1+ (1,0) [0|15] "" Vector__XXX
 SG_ EngStartEnableDevice2 : 2|2@1+ (1,0) [0|3] "" Vector__XXX
 SG_ EngStartEnableDevice1 : 0|2@1+ (1,0) [0|3] "" Vector__XXX

BO_ 2566811902 CVW: 8 Vector__XXX
 SG_ PoweredVehicleWeight : 0|16@1+ (10,0) [0|642550] "kg" Vector__XXX
 SG_ GrossCombinationVehicleWeight : 16|16@1+ (10,0) [0|642550] "kg" Vector__XXX

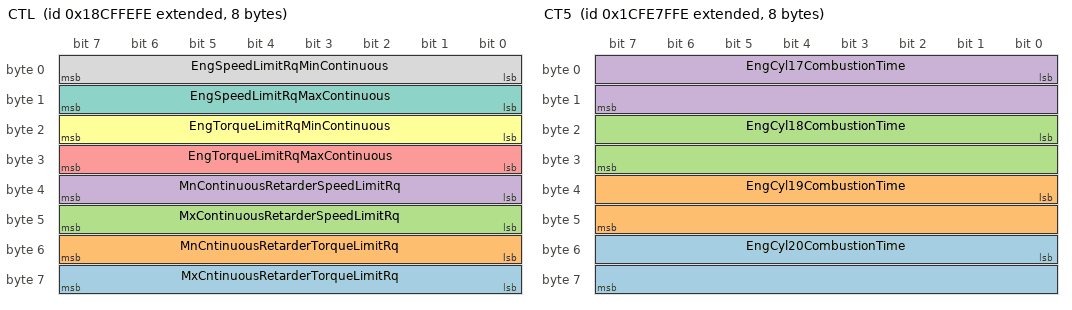
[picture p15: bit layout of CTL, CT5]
BO_ 2563768062 CTL: 8 Vector__XXX
 SG_ MxCntinuousRetarderTorqueLimitRq : 56|8@1+ (1,-125) [-125|125] "%" Vector__XXX
 SG_ MnCntinuousRetarderTorqueLimitRq : 48|8@1+ (1,-125) [-125|125] "%" Vector__XXX
 SG_ MxContinuousRetarderSpeedLimitRq : 40|8@1+ (32,0) [0|8000] "rpm" Vector__XXX
 SG_ MnContinuousRetarderSpeedLimitRq : 32|8@1+ (32,0) [0|8000] "rpm" Vector__XXX
 SG_ EngTorqueLimitRqMaxContinuous : 24|8@1+ (1,-125) [-125|125] "%" Vector__XXX
 SG_ EngTorqueLimitRqMinContinuous : 16|8@1+ (1,-125) [-125|125] "%" Vector__XXX
 SG_ EngSpeedLimitRqMaxContinuous : 8|8@1+ (32,0) [0|8000] "rpm" Vector__XXX
 SG_ EngSpeedLimitRqMinContinuous : 0|8@1+ (32,0) [0|8000] "rpm" Vector__XXX

BO_ 2633924862 CT6: 8 Vector__XXX
 SG_ EngAverageCombustionTime : 16|16@1+ (0.01,0) [0|642.55] "ms" Vector__XXX
 SG_ EngDesiredCombustionTime : 0|16@1+ (0.01,0) [0|642.55] "ms" Vector__XXX

BO_ 2633924606 CT5: 8 Vector__XXX
 SG_ EngCyl20CombustionTime : 48|16@1+ (0.01,0) [0|642.55] "ms" Vector__XXX
 SG_ EngCyl19CombustionTime : 32|16@1+ (0.01,0) [0|642.55] "ms" Vector__XXX
 SG_ EngCyl18CombustionTime : 16|16@1+ (0.01,0) [0|642.55] "ms" Vector__XXX
 SG_ EngCyl17CombustionTime : 0|16@1+ (0.01,0) [0|642.55] "ms" Vector__XXX

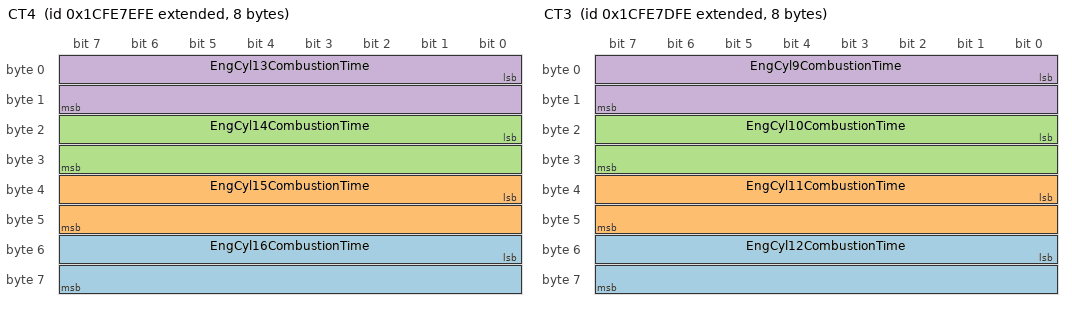
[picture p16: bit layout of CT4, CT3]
BO_ 2633924350 CT4: 8 Vector__XXX
 SG_ EngCyl16CombustionTime : 48|16@1+ (0.01,0) [0|642.55] "ms" Vector__XXX
 SG_ EngCyl15CombustionTime : 32|16@1+ (0.01,0) [0|642.55] "ms" Vector__XXX
 SG_ EngCyl14CombustionTime : 16|16@1+ (0.01,0) [0|642.55] "ms" Vector__XXX
 SG_ EngCyl13CombustionTime : 0|16@1+ (0.01,0) [0|642.55] "ms" Vector__XXX

BO_ 2633924094 CT3: 8 Vector__XXX
 SG_ EngCyl12CombustionTime : 48|16@1+ (0.01,0) [0|642.55] "ms" Vector__XXX
 SG_ EngCyl11CombustionTime : 32|16@1+ (0.01,0) [0|642.55] "ms" Vector__XXX
 SG_ EngCyl10CombustionTime : 16|16@1+ (0.01,0) [0|642.55] "ms" Vector__XXX
 SG_ EngCyl9CombustionTime : 0|16@1+ (0.01,0) [0|642.55] "ms" Vector__XXX

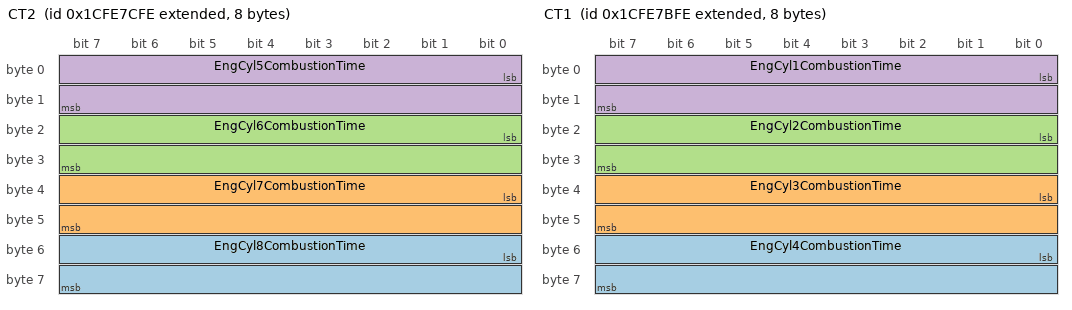
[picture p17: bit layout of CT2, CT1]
BO_ 2633923838 CT2: 8 Vector__XXX
 SG_ EngCyl8CombustionTime : 48|16@1+ (0.01,0) [0|642.55] "ms" Vector__XXX
 SG_ EngCyl7CombustionTime : 32|16@1+ (0.01,0) [0|642.55] "ms" Vector__XXX
 SG_ EngCyl6CombustionTime : 16|16@1+ (0.01,0) [0|642.55] "ms" Vector__XXX
 SG_ EngCyl5CombustionTime : 0|16@1+ (0.01,0) [0|642.55] "ms" Vector__XXX

BO_ 2633923582 CT1: 8 Vector__XXX
 SG_ EngCyl4CombustionTime : 48|16@1+ (0.01,0) [0|642.55] "ms" Vector__XXX
 SG_ EngCyl3CombustionTime : 32|16@1+ (0.01,0) [0|642.55] "ms" Vector__XXX
 SG_ EngCyl2CombustionTime : 16|16@1+ (0.01,0) [0|642.55] "ms" Vector__XXX
 SG_ EngCyl1CombustionTime : 0|16@1+ (0.01,0) [0|642.55] "ms" Vector__XXX

BO_ 2633878014 CMI: 8 Vector__XXX
 SG_ TotalCountOfConfigChangesMade : 0|16@1+ (1,0) [0|64255] "" Vector__XXX

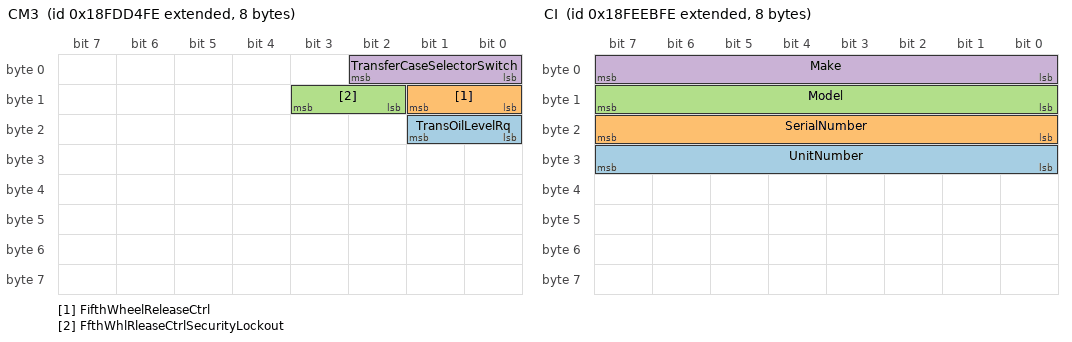
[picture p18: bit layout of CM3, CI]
BO_ 2566771966 CM3: 8 Vector__XXX
 SG_ TransOilLevelRq : 16|2@1+ (1,0) [0|3] "" Vector__XXX
 SG_ FifthWheelReleaseCtrl : 8|2@1+ (1,0) [0|3] "" Vector__XXX
 SG_ FfthWhlRleaseCtrlSecurityLockout : 10|2@1+ (1,0) [0|3] "" Vector__XXX
 SG_ TransferCaseSelectorSwitch : 0|3@1+ (1,0) [0|7] "" Vector__XXX

BO_ 2564882174 CM1: 8 Vector__XXX
 SG_ SelectedMaxVehicleSpeedLimit : 56|8@1+ (1,0) [0|250] "" Vector__XXX
 SG_ RqCabZoneHeating : 54|2@1+ (1,0) [0|3] "" Vector__XXX
 SG_ RqEngZoneHeating : 52|2@1+ (1,0) [0|3] "" Vector__XXX
 SG_ AuxHeaterModeRq : 48|4@1+ (1,0) [0|15] "" Vector__XXX
 SG_ EngAutomaticStartEnableSwitch : 46|2@1+ (1,0) [0|3] "" Vector__XXX
 SG_ AtomaticGearShiftingEnableSwitch : 44|2@1+ (1,0) [0|3] "" Vector__XXX
 SG_ DslPrtcltFltrRgnrtionForceSwitch : 42|2@1+ (1,0) [0|3] "" Vector__XXX
 SG_ DslPrtcltFltrRgnrtnInhibitSwitch : 40|2@1+ (1,0) [0|3] "" Vector__XXX
 SG_ VhclLmtngSpdGovernorEnableSwitch : 38|2@1+ (1,0) [0|3] "" Vector__XXX
 SG_ VhclLmtngSpdGvrnrIncrementSwitch : 36|2@1+ (1,0) [0|3] "" Vector__XXX
 SG_ VhclLmtngSpdGvrnrDecrementSwitch : 34|2@1+ (1,0) [0|3] "" Vector__XXX
 SG_ ParkBrakeCmd : 32|2@1+ (1,0) [0|3] "" Vector__XXX
 SG_ SeatBeltSwitch : 30|2@1+ (1,0) [0|3] "" Vector__XXX
 SG_ OperatorSeatDirectionSwitch : 28|2@1+ (1,0) [0|3] "" Vector__XXX
 SG_ BatteryMainSwitchHoldRq : 26|2@1+ (1,0) [0|3] "" Vector__XXX
 SG_ AuxHeaterCoolantPumpRq : 24|2@1+ (1,0) [0|3] "" Vector__XXX
 SG_ CabInteriorTempCmd : 8|16@1+ (0.03125,-273) [-273|1734.96875] "deg C" Vector__XXX
 SG_ RequestedPercentFanSpeed : 0|8@1+ (0.4,0) [0|100] "%" Vector__XXX

BO_ 2563833598 CL: 8 Vector__XXX
 SG_ SwtchBcklghtIllmntnBrghtnssPrcnt : 8|8@1+ (0.4,0) [0|100] "%" Vector__XXX
 SG_ IlluminationBrightnessPercent : 0|8@1+ (0.4,0) [0|100] "%" Vector__XXX

BO_ 2566843390 CI: 8 Vector__XXX
 SG_ UnitNumber : 24|8@1+ (1,0) [0|255] "per byte" Vector__XXX
 SG_ SerialNumber : 16|8@1+ (1,0) [0|255] "per byte" Vector__XXX
 SG_ Model : 8|8@1+ (1,0) [0|255] "per byte" Vector__XXX
 SG_ Make : 0|8@1+ (1,0) [0|255] "per byte" Vector__XXX

BO_ 2566844926 CCVS1: 8 Vector__XXX
 SG_ EngShutdownOverrideSwitch : 62|2@1+ (1,0) [0|3] "" Vector__XXX
 SG_ EngTestModeSwitch : 60|2@1+ (1,0) [0|3] "" Vector__XXX
 SG_ EngIdleDecrementSwitch : 58|2@1+ (1,0) [0|3] "" Vector__XXX
 SG_ EngIdleIncrementSwitch : 56|2@1+ (1,0) [0|3] "" Vector__XXX
 SG_ CruiseCtrlStates : 53|3@1+ (1,0) [0|7] "" Vector__XXX
 SG_ PTOGovernorState : 48|5@1+ (1,0) [0|31] "" Vector__XXX
 SG_ CruiseCtrlSetSpeed : 40|8@1+ (1,0) [0|250] "km/h" Vector__XXX
 SG_ CruiseCtrlAccelerateSwitch : 38|2@1+ (1,0) [0|3] "" Vector__XXX
 SG_ CruiseCtrlResumeSwitch : 36|2@1+ (1,0) [0|3] "" Vector__XXX
 SG_ CruiseCtrlCoastSwitch : 34|2@1+ (1,0) [0|3] "" Vector__XXX
 SG_ CruiseCtrlSetSwitch : 32|2@1+ (1,0) [0|3] "" Vector__XXX
 SG_ ClutchSwitch : 30|2@1+ (1,0) [0|3] "" Vector__XXX
 SG_ BrakeSwitch : 28|2@1+ (1,0) [0|3] "" Vector__XXX
 SG_ CruiseCtrlEnableSwitch : 26|2@1+ (1,0) [0|3] "" Vector__XXX
 SG_ CruiseCtrlActive : 24|2@1+ (1,0) [0|3] "" Vector__XXX
 SG_ WheelBasedVehicleSpeed : 8|16@1+ (0.00390625,0) [0|250.996] "km/h" Vector__XXX
 SG_ ParkBrakeReleaseInhibitRq : 6|2@1+ (1,0) [0|3] "" Vector__XXX
 SG_ CruiseCtrlPauseSwitch : 4|2@1+ (1,0) [0|3] "" Vector__XXX
 SG_ ParkingBrakeSwitch : 2|2@1+ (1,0) [0|3] "" Vector__XXX
 SG_ TwoSpeedAxleSwitch : 0|2@1+ (1,0) [0|3] "" Vector__XXX

BO_ 2566843902 CCSS: 8 Vector__XXX
 SG_ CruiseCtrlLowSetLimitSpeed : 16|8@1+ (1,0) [0|250] "km/h" Vector__XXX
 SG_ CruiseCtrlHighSetLimitSpeed : 8|8@1+ (1,0) [0|250] "km/h" Vector__XXX
 SG_ MaxVehicleSpeedLimit : 0|8@1+ (1,0) [0|250] "km/h" Vector__XXX

BO_ 2566809598 CCC: 8 Vector__XXX
 SG_ AuxHeaterMaxOutputPower : 0|16@1+ (2,0) [0|128510] "W" Vector__XXX

BO_ 2633940222 CBI: 16 Vector__XXX
 SG_ TripServiceBrakeApplications : 96|32@1+ (1,0) [0|4227858431] "appl" Vector__XXX
 SG_ TripServiceBrakeDistance : 64|32@1+ (0.125,0) [0|526385151.9] "km" Vector__XXX
 SG_ TripCompressionBrakeDistance : 32|32@1+ (0.125,0) [0|526385151.9] "km" Vector__XXX
 SG_ TotalCompressionBrakeDistance : 0|32@1+ (0.125,0) [0|526385151.9] "km" Vector__XXX

BO_ 2566775294 CACI: 8 Vector__XXX
 SG_ CbA_CRfrgrntCmpressorOutletPress : 0|8@1+ (16,0) [0|4000] "kPa" Vector__XXX

BO_ 2566803710 BT1: 8 Vector__XXX
 SG_ Battery2Temp : 8|8@1+ (1,-40) [-40|210] "deg C" Vector__XXX
 SG_ Battery1Temp : 0|8@1+ (1,-40) [-40|210] "deg C" Vector__XXX

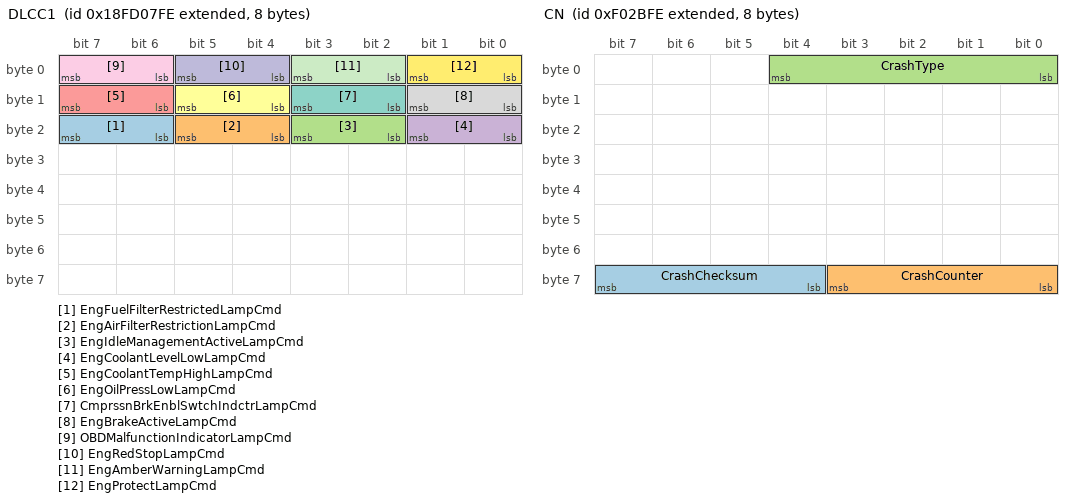
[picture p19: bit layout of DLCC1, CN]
BO_ 2566719486 DLCC1: 8 Vector__XXX
 SG_ EngFuelFilterRestrictedLampCmd : 22|2@1+ (1,0) [0|3] "" Vector__XXX
 SG_ EngAirFilterRestrictionLampCmd : 20|2@1+ (1,0) [0|3] "" Vector__XXX
 SG_ EngIdleManagementActiveLampCmd : 18|2@1+ (1,0) [0|3] "" Vector__XXX
 SG_ EngCoolantLevelLowLampCmd : 16|2@1+ (1,0) [0|3] "" Vector__XXX
 SG_ EngCoolantTempHighLampCmd : 14|2@1+ (1,0) [0|3] "" Vector__XXX
 SG_ EngOilPressLowLampCmd : 12|2@1+ (1,0) [0|3] "" Vector__XXX
 SG_ CmprssnBrkEnblSwtchIndctrLampCmd : 10|2@1+ (1,0) [0|3] "" Vector__XXX
 SG_ EngBrakeActiveLampCmd : 8|2@1+ (1,0) [0|3] "" Vector__XXX
 SG_ OBDMalfunctionIndicatorLampCmd : 6|2@1+ (1,0) [0|3] "" Vector__XXX
 SG_ EngRedStopLampCmd : 4|2@1+ (1,0) [0|3] "" Vector__XXX
 SG_ EngAmberWarningLampCmd : 2|2@1+ (1,0) [0|3] "" Vector__XXX
 SG_ EngProtectLampCmd : 0|2@1+ (1,0) [0|3] "" Vector__XXX

BO_ 2633832702 CSI: 8 Vector__XXX
 SG_ RolloverSensorType : 64|4@1+ (1,0) [0|15] "" Vector__XXX
 SG_ RearCollisionSensor4Type : 60|4@1+ (1,0) [0|15] "" Vector__XXX
 SG_ RearCollisionSensor3Type : 56|4@1+ (1,0) [0|15] "" Vector__XXX
 SG_ RearCollisionSensor2Type : 52|4@1+ (1,0) [0|15] "" Vector__XXX
 SG_ RearCollisionSensor1Type : 48|4@1+ (1,0) [0|15] "" Vector__XXX
 SG_ SideCollisionSensorRearRightType : 44|4@1+ (1,0) [0|15] "" Vector__XXX
 SG_ SdCllisionSensorMidRearRightType : 40|4@1+ (1,0) [0|15] "" Vector__XXX
 SG_ SdCllsionSensorMidFrontRightType : 36|4@1+ (1,0) [0|15] "" Vector__XXX
 SG_ SdeCollisionSensorFrontRightType : 32|4@1+ (1,0) [0|15] "" Vector__XXX
 SG_ SideCollisionSensorRearLeftType : 28|4@1+ (1,0) [0|15] "" Vector__XXX
 SG_ SdCollisionSensorMidRearLeftType : 24|4@1+ (1,0) [0|15] "" Vector__XXX
 SG_ SdCllisionSensorMidFrontLeftType : 20|4@1+ (1,0) [0|15] "" Vector__XXX
 SG_ SideCollisionSensorFrontLeftType : 16|4@1+ (1,0) [0|15] "" Vector__XXX
 SG_ FrontalCollisionSensor4Type : 12|4@1+ (1,0) [0|15] "" Vector__XXX
 SG_ FrontalCollisionSensor3Type : 8|4@1+ (1,0) [0|15] "" Vector__XXX
 SG_ FrontalCollisionSensor2Type : 4|4@1+ (1,0) [0|15] "" Vector__XXX
 SG_ FrontalCollisionSensor1Type : 0|4@1+ (1,0) [0|15] "" Vector__XXX

BO_ 2163223550 CN: 8 Vector__XXX
 SG_ CrashChecksum : 60|4@1+ (1,0) [0|15] "" Vector__XXX
 SG_ CrashCounter : 56|4@1+ (1,0) [0|15] "" Vector__XXX
 SG_ CrashType : 0|5@1+ (5,0) [0|0] "" Vector__XXX

BO_ 2566714878 CAC2P: 8 Vector__XXX
 SG_ EngChrgArClr2PrecoolerEfficiency : 32|8@1+ (0.4,0) [0|100] "%" Vector__XXX
 SG_ EngChrgArClr2PrecoolerOutletTemp : 16|16@1+ (0.03125,-273) [-273|1734.96875] "deg C" Vector__XXX
 SG_ EngChrgArClr2PrecoolerIntakeTemp : 0|16@1+ (0.03125,-273) [-273|1734.96875] "deg C" Vector__XXX

BO_ 2566714622 CAC2: 8 Vector__XXX
 SG_ EngChargeAirCooler2Efficiency : 48|8@1+ (0.4,0) [0|100] "%" Vector__XXX
 SG_ EngChrgeAirCooler2AmbientAirTemp : 32|16@1+ (0.03125,-273) [-273|1734.96875] "deg C" Vector__XXX
 SG_ EngChargeAirCooler2OutletTemp : 16|16@1+ (0.03125,-273) [-273|1734.96875] "deg C" Vector__XXX
 SG_ EngChargeAirCooler2IntakeTemp : 0|16@1+ (0.03125,-273) [-273|1734.96875] "deg C" Vector__XXX

BO_ 2566715390 CAC1P: 8 Vector__XXX
 SG_ EngChrgArClr1PrecoolerEfficiency : 32|8@1+ (0.4,0) [0|100] "%" Vector__XXX
 SG_ EngChrgArClr1PrecoolerOutletTemp : 16|16@1+ (0.03125,-273) [-273|1734.96875] "deg C" Vector__XXX
 SG_ EngChrgArClr1PrecoolerIntakeTemp : 0|16@1+ (0.03125,-273) [-273|1734.96875] "deg C" Vector__XXX

BO_ 2566715134 CAC1: 8 Vector__XXX
 SG_ EngChargeAirCooler1Efficiency : 32|8@1+ (0.4,0) [0|100] "%" Vector__XXX
 SG_ EngChrgeAirCooler1AmbientAirTemp : 16|16@1+ (0.03125,-273) [-273|1734.96875] "deg C" Vector__XXX
 SG_ EngChargeAirCooler1IntakeTemp : 0|16@1+ (0.03125,-273) [-273|1734.96875] "deg C" Vector__XXX

CM_ BO_ 2565865726 "NOTE- This message will be transmitted by several types of retarding devices such as engine compression release ...";
CM_ SG_ 2565865726 ActlMxAvlblRetarderPercentTorque "This is the maximum amount of torque that the retarder can immediately deliver.   It is the same as the maximum torque ...";
CM_ SG_ 2565865726 RetarderSelectionNonengine "The “Retarder Selection, non-engine” is the position of the driver’s selector for retarders that are not part of the engine ...";
CM_ SG_ 2565865726 DrvrsDemandRetarderPercentTorque "The Drivers demand retarder – percent torque is the maximum torque selected by the driver when one or more modes ...";
CM_ SG_ 2565865726 SrcAddrssOfCntrllngDvcFrRtrdrCtr "The source address of the SAE J1939 device currently controlling the retarder.  It is used to expand the torque mode ...";
CM_ SG_ 2565865726 RetarderRoadSpeedExceededStatus "Retarder Road Speed Exceeded Status: 00   Road speed is below threshold ...";
CM_ SG_ 2565865726 RetarderRoadSpeedLimitSwitch "Retarder road speed limit switch states: 00   Road speed limiting by retarder is disabled ...";
CM_ SG_ 2565865726 RetarderRequestingBrakeLight "Indicates that whether the retarder is requesting that the brake lights are illuminated.";
CM_ SG_ 2565865726 EngCoolantLoadIncrease "Status of an event, external to the engine, that may increase the nominal temperature of the engine coolant liquid.";
CM_ SG_ 2565865726 IntendedRetarderPercentTorque "Braking torque of retarder that the retarder is currently trying to achieve.  This value takes into account all static ...";
CM_ SG_ 2565865726 ActualRetarderPercentTorque "Actual braking torque of the retarder as a percent of retarder configuration reference torque SPN 556.";
CM_ SG_ 2565865726 RetarderEnableShiftAssistSwitch "Switch signal which indicates whether the operator wishes the retarder to be enabled for transmission shift assist.  The ...";
CM_ SG_ 2565865726 RetarderEnableBrakeAssistSwitch "Switch signal which indicates whether the operator wishes the retarder to be enabled for vehicle braking assist. The ...";
CM_ SG_ 2565865726 RetarderTorqueMode "State signal which indicates which retarder torque mode is currently generating, limiting, or controlling the torque.  Note ...";
CM_ SG_ 2633932798 EngExhaustGasPort20Temp "Temperature at the cylinder exhaust port of the engine.";
CM_ SG_ 2633932798 EngExhaustGasPort19Temp "Temperature at the cylinder exhaust port of the engine.";
CM_ SG_ 2633932798 EngExhaustGasPort18Temp "Temperature at the cylinder exhaust port of the engine.";
CM_ SG_ 2633932798 EngExhaustGasPort17Temp "Temperature at the cylinder exhaust port of the engine.";
CM_ SG_ 2566824190 EngExhaustGasPort16Temp "Temperature at the cylinder exhaust port of the engine.";
CM_ SG_ 2566824190 EngExhaustGasPort15Temp "Temperature at the cylinder exhaust port of the engine.";
CM_ SG_ 2566824190 EngExhaustGasPort14Temp "Temperature at the cylinder exhaust port of the engine.";
CM_ SG_ 2566824190 EngExhaustGasPort13Temp "Temperature at the cylinder exhaust port of the engine.";
CM_ SG_ 2633933310 EngExhaustGasPort12Temp "Temperature at the cylinder exhaust port of the engine.";
CM_ SG_ 2633933310 EngExhaustGasPort11Temp "Temperature at the cylinder exhaust port of the engine.";
CM_ SG_ 2633933310 EngExhaustGasPort10Temp "Temperature at the cylinder exhaust port of the engine.";
CM_ SG_ 2633933310 EngExhaustGasPort9Temp "Temperature at the cylinder exhaust port of the engine.";
CM_ SG_ 2633933566 EngExhaustGasPort8Temp "Temperature at the cylinder exhaust port of the engine.";
CM_ SG_ 2633933566 EngExhaustGasPort7Temp "Temperature at the cylinder exhaust port of the engine.";
CM_ SG_ 2633933566 EngExhaustGasPort6Temp "Temperature at the cylinder exhaust port of the engine.";
CM_ SG_ 2633933566 EngExhaustGasPort5Temp "Temperature at the cylinder exhaust port of the engine.";
CM_ SG_ 2633933822 EngExhaustGasPort4Temp "Temperature at the cylinder exhaust port of the engine.";
CM_ SG_ 2633933822 EngExhaustGasPort3Temp "Temperature at the cylinder exhaust port of the engine.";
CM_ SG_ 2633933822 EngExhaustGasPort2Temp "Temperature at the cylinder exhaust port of the engine.";
CM_ SG_ 2633933822 EngExhaustGasPort1Temp "Temperature at the cylinder exhaust port of the engine.";
CM_ BO_ 2566776062 "Parameters related to the performance characteristics of equipment ...";
CM_ SG_ 2566776062 PayloadPercentage "The current payload of the equipment, reported as a percentage of the equipment's rated payload limit.";
CM_ BO_ 2566771454 "Message used to transfer ECU performance parameters.";
CM_ SG_ 2566771454 DataMemoryUsage "The used storage capacity of the data buffer memory internal to an ECU, such as a data logger.";
CM_ SG_ 2566771454 KeepAliveBatteryConsumption "The capacity consumed from the direct battery connection since the key was last turned off.  This value is maintained and ...";
CM_ BO_ 2566775806 "Parameters related to the operation and controls for equipment ...";
CM_ SG_ 2566775806 TravelVelocityCtrlPos "The position of the travel velocity control component reported as a percentage of the control's full displacement in each ...";
CM_ SG_ 2633935358 EngExhstGsOxygnSnsrClsdLpOprtion "Indicates whether the engine is using the Exhaust Gas Oxygen sensor to control the air/fuel ratio.";
CM_ SG_ 2633935358 EngExhstGsOxygnSnsrFlngCrrection "The amount of fueling change required by the system based on the measured Exhaust Oxygen value compared to the ...";
CM_ SG_ 2633935358 EngActualExhaustOxygen "The actual amount of oxygen in the exhaust represented as a percentage by volume with respect to the total volume of ...";
CM_ SG_ 2633935358 EngDesiredExhaustOxygen "The desired amount of oxygen in the exhaust represented as a percentage by volume with respect to the total volume of ...";
CM_ SG_ 2633935358 EngDesiredRatedExhaustOxygen "The desired amount of oxygen in the exhaust at rated conditions represented as a percentage by volume with respect to ...";
CM_ BO_ 2365447166 "Used to transfer information about the measured status of three additional axes of a joystick and switches of the joystick ...";
CM_ SG_ 2365447166 Jystick3GripXAxisDetentPosStatus "Reports when the current joystick grip position is in the detent position for that axis of travel.";
CM_ SG_ 2365447166 Jystick3GripYAxisDetentPosStatus "Reports when the current joystick grip position is in the detent position for that axis of travel.";
CM_ SG_ 2365447166 Jystick3ThetaAxisDetentPosStatus "Reports when the current joystick position is in the detent position for that axis of travel.";
CM_ SG_ 2365447166 Joystick3ThetaAxisPos "The position of the joystick in the relative motion of travel from the neutral position.  Position value of 0 is Neutral and ...";
CM_ SG_ 2365447166 Jystck3ThtAxsClckwsPstvPosStatus "Reports when the current joystick position is on the positive travel side (forward, right, clockwise, up) relative to the ...";
CM_ SG_ 2365447166 Jystck3ThetaAxisNeutralPosStatus "Reports when the current joystick position is in the neutral position for that axis of travel.  The neutral position ...";
CM_ SG_ 2365447166 Joystick3GripYAxisPos "The position of the joystick grip in the relative motion of travel from the neutral position.  Position value of 0 is Neutral and ...";
CM_ SG_ 2365447166 Jystck3GrpYAxsLvrFrwrdPstvPsStts "Reports when the current joystick grip position is on the positive travel side (forward, right, clockwise, up) relative to the ...";
CM_ SG_ 2365447166 Jystck3GrpYAxsLvrBckNgtvPsStatus "Reports when the current joystick grip position is on the negative travel side (back, left, counterclockwise, down) relative ...";
CM_ SG_ 2365447166 Jystck3GripYAxisNeutralPosStatus "Reports when the current joystick grip position is in the neutral position for that axis of travel.  The neutral position ...";
CM_ SG_ 2365447166 Joystick3GripXAxisPos "The position of the joystick grip in the relative motion of travel from the neutral position.  Position value of 0 is Neutral and ...";
CM_ SG_ 2365447166 Jystck3GrpXAxsLvrRghtPstvPsSttus "Reports when the current joystick grip position is on the positive travel side (forward, right, clockwise, up) relative to the ...";
CM_ SG_ 2365447166 Jystck3GrpXAxsLvrLftNgtvPsStatus "Reports when the current joystick grip position is on the negative travel side (back, left, counterclockwise, down) relative ...";
CM_ SG_ 2365447166 Jystck3GripXAxisNeutralPosStatus "Reports when the current joystick grip position is in the neutral position for that axis of travel.  The neutral position ...";
CM_ SG_ 2365447166 Jystck3ThtAxsCntrClckwsNgtvPsStt "Reports when the current joystick position is on the negative travel side (back, left, counterclockwise, down) relative to the ...";
CM_ BO_ 2365446654 "Used to transfer information about the measured status of three additional axes of a joystick and switches of the joystick ...";
CM_ SG_ 2365446654 Jystick2GripXAxisDetentPosStatus "Reports when the current joystick grip position is in the detent position for that axis of travel.";
CM_ SG_ 2365446654 Jystick2GripYAxisDetentPosStatus "Reports when the current joystick grip position is in the detent position for that axis of travel.";
CM_ SG_ 2365446654 Jystick2ThetaAxisDetentPosStatus "Reports when the current joystick position is in the detent position for that axis of travel.";
CM_ SG_ 2365446654 Joystick2ThetaAxisPos "The position of the joystick in the relative motion of travel from the neutral position.  Position value of 0 is Neutral and ...";
CM_ SG_ 2365446654 Jystck2ThtAxsClckwsPstvPosStatus "Reports when the current joystick position is on the positive travel side (forward, right, clockwise, up) relative to the ...";
CM_ SG_ 2365446654 Jystck2ThetaAxisNeutralPosStatus "Reports when the current joystick position is in the neutral position for that axis of travel.  The neutral position ...";
CM_ SG_ 2365446654 Joystick2GripYAxisPos "The position of the joystick grip in the relative motion of travel from the neutral position.  Position value of 0 is Neutral and ...";
CM_ SG_ 2365446654 Jystck2GrpYAxsLvrFrwrdPstvPsStts "Reports when the current joystick grip position is on the positive travel side (forward, right, clockwise, up) relative to the ...";
CM_ SG_ 2365446654 Jystck2GrpYAxsLvrBckNgtvPsStatus "Reports when the current joystick grip position is on the negative travel side (back, left, counterclockwise, down) relative ...";
CM_ SG_ 2365446654 Jystck2GripYAxisNeutralPosStatus "Reports when the current joystick grip position is in the neutral position for that axis of travel.  The neutral position ...";
CM_ SG_ 2365446654 Joystick2GripXAxisPos "The position of the joystick grip in the relative motion of travel from the neutral position.  Position value of 0 is Neutral and ...";
CM_ SG_ 2365446654 Jystck2GrpXAxsLvrRghtPstvPsSttus "Reports when the current joystick grip position is on the positive travel side (forward, right, clockwise, up) relative to the ...";
CM_ SG_ 2365446654 Jystck2GrpXAxsLvrLftNgtvPsStatus "Reports when the current joystick grip position is on the negative travel side (back, left, counterclockwise, down) relative ...";
CM_ SG_ 2365446654 Jystck2GripXAxisNeutralPosStatus "Reports when the current joystick grip position is in the neutral position for that axis of travel.  The neutral position ...";
CM_ SG_ 2365446654 Jystck2ThtAxsCntrClckwsNgtvPsStt "Reports when the current joystick position is on the negative travel side (back, left, counterclockwise, down) relative to the ...";
CM_ BO_ 2365446142 "Used to transfer information about the measured status of three additional axes of a joystick and switches of the joystick ...";
CM_ SG_ 2365446142 Jystick1GripXAxisDetentPosStatus "Reports when the current joystick grip position is in the detent position for that axis of travel.";
CM_ SG_ 2365446142 Jystick1GripYAxisDetentPosStatus "Reports when the current joystick grip position is in the detent position for that axis of travel.";
CM_ SG_ 2365446142 Jystick1ThetaAxisDetentPosStatus "Reports when the current joystick position is in the detent position for that axis of travel.";
CM_ SG_ 2365446142 Joystick1ThetaAxisPos "The position of the joystick in the relative motion of travel from the neutral position.  Position value of 0 is Neutral and ...";
CM_ SG_ 2365446142 Jystck1ThtAxsClckwsPstvPosStatus "Reports when the current joystick position is on the positive travel side (forward, right, clockwise, up) relative to the ...";
CM_ SG_ 2365446142 Jystck1ThetaAxisNeutralPosStatus "Reports when the current joystick position is in the neutral position for that axis of travel.  The neutral position ...";
CM_ SG_ 2365446142 Joystick1GripYAxisPos "The position of the joystick grip in the relative motion of travel from the neutral position.  Position value of 0 is Neutral and ...";
CM_ SG_ 2365446142 Jystck1GrpYAxsLvrFrwrdPstvPsStts "Reports when the current joystick grip position is on the positive travel side (forward, right, clockwise, up) relative to the ...";
CM_ SG_ 2365446142 Jystck1GrpYAxsLvrBckNgtvPsStatus "Reports when the current joystick grip position is on the negative travel side (back, left, counterclockwise, down) relative ...";
CM_ SG_ 2365446142 Aftrtrtmnt1DslExhstFldPrprtsPrlm "Reports when the current joystick grip position is in the neutral position for that axis of travel.  The neutral position ...";
CM_ SG_ 2365446142 Joystick1GripXAxisPos "The position of the joystick grip in the relative motion of travel from the neutral position.  Position value of 0 is Neutral and ...";
CM_ SG_ 2365446142 Jystck1GrpXAxsLvrRghtPstvPsSttus "Reports when the current joystick grip position is on the positive travel side (forward, right, clockwise, up) relative to the ...";
CM_ SG_ 2365446142 Jystck1GrpXAxsLvrLftNgtvPsStatus "Reports when the current joystick grip position is on the negative travel side (back, left, counterclockwise, down) relative ...";
CM_ SG_ 2365446142 Jystck1GripXAxisNeutralPosStatus "Reports when the current joystick grip position is in the neutral position for that axis of travel.  The neutral position ...";
CM_ SG_ 2365446142 Jystck1ThtAxsCntrClckwsNgtvPsStt "Reports when the current joystick position is on the negative travel side (back, left, counterclockwise, down) relative to the ...";
CM_ SG_ 2633929470 EngFuelRackPos "Measured position of the engine fuel rack.  A value of 0% rack represents no fueling and a value of 100% rack represents ...";
CM_ SG_ 2633929470 EngGasMassFlowRate1 "Gas mass flow rate delivered to an engine through its first fuel control system.  See SPN 3467 for the second fuel control ...";
CM_ SG_ 2633929470 InstantaneousEstBrakePower "Estimate of the power developed by the engine.";
CM_ SG_ 2633929470 EngExhaustGasPress1 "Gage pressure of the exhaust gases as measured at the turbine intake of the turbocharger. This SPN to be used for inline ...";
CM_ SG_ 2633929470 EngPrefilterOilPress "Gage pressure of the engine oil before the oil reaches the oil filter.";
CM_ SG_ 2633937406 TotalECURunTime "Total time accumulated over the life of the ECU, from ignition switch ON to ignition switch OFF.  When the ECU is ...";
CM_ SG_ 2633937406 TotalECUDistance "Total distance accumulated over the life of the ECU.  When the ECU is replaced this value shall be reset.";
CM_ BO_ 2364541694 "Flow rates of Air and mixed gasses into the engine cylinders.";
CM_ SG_ 2364541694 EngExhstGsRcrcltion2MassFlowRate "Flow rate of gas through the second EGR system. Flow rate of the exhaust gas being recirculated from the 2nd EGR ...";
CM_ SG_ 2364541694 EngIntakeAirMassFlowRate "Mass flow rate of fresh air entering the engine air intake, before any EGR mixer, if used.  Flow rate of fresh air conducted ...";
CM_ SG_ 2364541694 EngExhstGsRcrcltion1MassFlowRate "Flow rate of gas through the EGR system. Flow rate of the exhaust gas being recirculated into the combustion air.";
CM_ SG_ 2566810366 FuelPumpPrimerStatus "Parameter used to transmit the actual status of the fuel priming system.  The fuel priming system is a system that purges ...";
CM_ SG_ 2566810366 EngVentilationStatus "Engine ventilation control states.";
CM_ SG_ 2566810366 EngCoolantPreheatedState "Indicates whether the engine coolant is pre-heated sufficiently for starting purposes.";
CM_ SG_ 2566810366 EngOilPreHeatedState "Indicates whether the engine oil pre-heated sufficiently for starting purposes.";
CM_ SG_ 2566810366 EngOilPrimingState "Determination of whether or not the engine is (or has recently been) sufficiently lubricated for starting purposes.";
CM_ SG_ 2566810366 EngOilPrimingPumpSwitch "Switch input for activating the engine oil priming pump.";
CM_ SG_ 2566810366 EngOilFilterOutletPress "Oil pressure (gauge) measured just downstream of oil filter.Used in conjunction with SPN1208 (pre-filter oil pressure) to ...";
CM_ SG_ 2566810366 EngWasteOilReservoirLevel "Level of crankcase blowby emulsion collected by a container.  Normalized to percent, 0% represents completely empty ...";
CM_ SG_ 2566810366 EngFuelFilterDiffPress "Differential pressure measured across the fuel filter located between the fuel tank and the supply pump.  See Figures ...";
CM_ SG_ 2566810366 EngFuelSupplyPumpIntakePress "Absolute pressure of fuel at the fuel supply pump intake.  See Figures SPN16_A & SPN16_B ...";
CM_ SG_ 2566810366 EngOilLevelRemoteReservoir "Ratio of current volume of engine oil in a remote reservoir to the maximum required volume.  If a single switch (on/off) is ...";
CM_ BO_ 2566767102 "3rd PGN which identifies parameters that are either measuring various pressures within the engine or identifying engine ...";
CM_ SG_ 2566767102 EngThrottleValve1DiffPress "The differential pressure between the intake and outlet of the throttle valve 1 (SPN 53).  The differential pressure is ...";
CM_ SG_ 2566767102 EngExhstGsRcrclation1OutletPress "EGR outlet pressure is measured immediately after the EGR valve.";
CM_ SG_ 2566767102 EngExhstVlvActtionSystemOilPress "The absolute pressure of the oil in the hydraulic system that powers the engine exhaust valve actuation system ...";
CM_ SG_ 2566767102 EngExhstGsRcrclation1IntakePress "EGR intake gage pressure is measured after the EGR cooler and before the EGR valve.";
CM_ SG_ 2566767102 EngIntkVlvActationSystemOilPress "The gage pressure of the oil in the hydraulic system that powers the engine intake valve actuation system ...";
CM_ BO_ 2566839294 "2nd PGN which identifies parameters that are either measuring various pressures within the engine or identifying engine ...";
CM_ SG_ 2566839294 EngInjectorMeteringRail2Press "The gage pressure of fuel in the metering rail #2 as delivered from the supply pump to the injector metering intake.  See ...";
CM_ SG_ 2566839294 EngInjectorTimingRail1Press "The gage pressure of fuel in the timing rail delivered from the supply pump to the injector timing intake.";
CM_ SG_ 2566839294 EngInjectorMeteringRail1Press "The gage pressure of fuel in the primary, or first, metering rail as delivered from the supply pump to the injector metering ...";
CM_ SG_ 2566839294 EngInjectionCtrlPress "The gage pressure of the engine oil in the hydraulic accumulator that powers an intensifier used for fuel injection.";
CM_ BO_ 2566844414 "PGN which identifies parameters that are either measuring various pressures within the engine or identifying engine fluid ...";
CM_ SG_ 2566844414 EngCoolantLevel "Ratio of volume of liquid found in engine cooling system to total cooling system volume.  Typical monitoring location is in ...";
CM_ SG_ 2566844414 EngCoolantPress "Gage pressure of liquid found in engine cooling system.";
CM_ SG_ 2566844414 EngCrankcasePress "Gage pressure inside engine crankcase.";
CM_ SG_ 2566844414 EngOilPress "Gage pressure of oil in engine lubrication system as provided by oil pump.";
CM_ SG_ 2566844414 EngOilLevel "Ratio of current volume of engine sump oil to maximum required volume.";
CM_ SG_ 2566844414 EngExCrankcaseBlowbyPress "Differential crankcase blow-by pressure as measured through a tube with a venturi.";
CM_ SG_ 2566844414 EngFuelDeliveryPress "Gage pressure of fuel in system as delivered from supply pump to the injection pump.  See also SPN 5578 for Fuel ...";
CM_ SG_ 2633929726 SafetyWireStatus "Status signal which indicates that the safety wire has been activated.  When the safety wire is activated, the engine will ...";
CM_ SG_ 2633929726 ElectricalLoad "Electrical power delivered by the engine to the electrical system connected to the generator.";
CM_ BO_ 2566772222 "Engine related parameters ...";
CM_ SG_ 2566772222 EngVrblGeometryTurbo1ActuatorPos "Sensor that measures the position of the variable geometry turbocharger actuator.  A  position of 0% indicates the ...";
CM_ SG_ 2566772222 EngVriableGeometryTurbo1CtrlMode "Indicates if the variable geometry turbocharger control status is either open loop or closed loop.";
CM_ SG_ 2566772222 EngFuelCtrlCtrlMode "Indicates whether the Engine Fuel Control System is in open loop or closed loop.";
CM_ SG_ 2566772222 EngVrblGmtryTrbArCtrlShtoffValve "Isolates vehicle brake air from the Variable Geometry Turbocharger (VGT) system when engine is not running.  This valve ...";
CM_ SG_ 2566772222 EngExhstGsRcirculation1ValveCtrl "Desired percentage of maximum Exhaust Gas Recirculation (EGR) valve opening.  0% means valve is closed. 100% ...";
CM_ SG_ 2566772222 EngTrb1ClclatedTurbineOutletTemp "Calculated value of turbocharger compressor outlet air temperature.  Temperature of air exiting the turbocharger ...";
CM_ SG_ 2566772222 EngTrb1ClclatedTurbineIntakeTemp "Calculated value of turbine intake temperature based on engine operating conditions, such as intake manifold ...";
CM_ SG_ 2633940734 CrnkAttmptCntOnPrsntStartAttempt "Reports the number of cranking cycles undergone during the present start attempt.";
CM_ SG_ 2633940734 EngIntakeManifoldPressCtrlMode "Indicates that the Boost Pressure Closed Loop Control status either open loop or closed loop.";
CM_ SG_ 2633940734 EngRotationDirection "Direction of engine rotation, as reported by the engine.  Direction convention as viewed by an observer standing at the ...";
CM_ SG_ 2633940734 EngRatedSpeed "The maximum governed rotational velocity of the engine crankshaft under full load conditions.  Note that the engine ...";
CM_ SG_ 2633940734 EngRatedPower "Net brake power that the engine will deliver continuously, specified for a given application at a rated speed.";
CM_ SG_ 2566840318 Aftertreatment2ExhaustDewPoint "Indicates that the temperature on the exhaust side of the aftertreatment has exceeded the dew point, as estimated by the ...";
CM_ SG_ 2566840318 Aftertreatment2IntakeDewPoint "Indicates that the temperature on the intake side of the aftertreatment system has exceeded the dew point, as estimated ...";
CM_ SG_ 2566840318 Aftertreatment1ExhaustDewPoint "Indicates that the temperature on the exhaust side of the aftertreatment has exceeded the dew point, as estimated by the ...";
CM_ SG_ 2566840318 Aftertreatment1IntakeDewPoint "Indicates that the temperature on the intake side of the aftertreatment system has exceeded the dew point, as estimated ...";
CM_ SG_ 2566840318 Aftrtreatment1ExhaustGasMassFlow "Measured/calculated exhaust gas mass upstream of the aftertreatment system in exhaust bank 1 and 2.";
CM_ SG_ 2566840318 EstEngPrsiticLossesPercentTorque "The calculated torque that indicates the estimated amount of torque loss due to engine parasitics, such as cooling fan, air ...";
CM_ SG_ 2566840318 EngnsDsrdOprtngSpdAsymmtryAdjstm "This byte is utilized in transmission gear selection routines and indicates the engine's preference of lower versus higher ...";
CM_ SG_ 2566840318 EnginesDesiredOperatingSpeed "An indication by the engine of the optimal operating speed of the engine for the current existing conditions.  These ...";
CM_ SG_ 2566840318 NominalFrictionPercentTorque "The calculated torque that indicates the amount of torque required by the basic engine itself added by the loss torque of ...";
CM_ BO_ 2364539902 "Identifies electronic engine control related parameters.";
CM_ SG_ 2364539902 EstPumpingPercentTorque "The calculated torque that indicates the estimated amount of torque loss due to the engine air handling system. The value ...";
CM_ SG_ 2364539902 ActlMaxAvailableEngPercentTorque "This is the maximum amount of torque that the engine can immediately deliver as a percentage of the reference engine ...";
CM_ SG_ 2364539902 SCRThermalManagementActive "Indicates that the exhaust temperatures have been elevated for regeneration of the SCR aftertreatment system or in ...";
CM_ SG_ 2364539902 DPFThermalManagementActive "Indicates that the exhaust temperatures have been elevated for regeneration of the diesel particulate filter aftertreatment ...";
CM_ SG_ 2364539902 MmntaryEngMaxPowerEnableFeedback "Momentarily requesting Engine Maximum Power Enable - feature support feedback ...";
CM_ SG_ 2364539902 VhcleAccelerationRateLimitStatus "Status (active or not active) of the system used to limit maximum forward  vehicle acceleration.";
CM_ SG_ 2364539902 AccelPedalPos2 "The ratio of actual position of the second analog engine speed/torque request input device (such as an accelerator pedal ...";
CM_ SG_ 2364539902 RemoteAccelPedalPos "The ratio of actual position of the remote analog engine speed/torque request input device (such as an accelerator pedal ...";
CM_ SG_ 2364539902 EngPercentLoadAtCurrentSpeed "The ratio of actual engine percent torque (indicated) to maximum indicated torque available at the current engine speed, ...";
CM_ SG_ 2364539902 AccelPedalPos1 "The ratio of actual position of the analog engine speed/torque request input device (such as an accelerator pedal or ...";
CM_ SG_ 2364539902 AccelPedal2LowIdleSwitch "Switch signal which indicates the state of the accelerator pedal 2 low idle switch.  The low idle switch is defined in SAE ...";
CM_ SG_ 2364539902 RoadSpeedLimitStatus "Status (active or not active) of the system used to limit maximum vehicle velocity.";
CM_ SG_ 2364539902 AccelPedalKickdownSwitch "Switch signal which indicates whether the accelerator pedal kickdown switch is opened or closed.  The kickdown switch is ...";
CM_ SG_ 2364539902 AccelPedal1LowIdleSwitch "Switch signal which indicates the state of the accelerator pedal 1 low idle switch.  The low idle switch is defined in SAE ...";
CM_ BO_ 2364540158 "Engine related parameters ...";
CM_ SG_ 2364540158 EngDemandPercentTorque "The requested torque output of the engine by all dynamic internal inputs, including smoke control, noise control and low ...";
CM_ SG_ 2364540158 EngStarterMode "There are several phases in a starting action and different reasons why a start cannot take place.";
CM_ SG_ 2364540158 SrcAddrssOfCntrllngDvcForEngCtrl "The source address of the SAE J1939 device currently controlling the engine.  It is used to expand the torque mode ...";
CM_ SG_ 2364540158 EngSpeed "Actual engine speed which is calculated over a minimum crankshaft angle of 720 degrees divided by the number of ...";
CM_ SG_ 2364540158 ActualEngPercentTorque "The calculated output torque of the engine.  The data is transmitted in indicated torque as a percent of reference engine ...";
CM_ SG_ 2364540158 DriversDemandEngPercentTorque "The requested torque output of the engine by the driver. It is based on input from the following requestors external to the ...";
CM_ SG_ 2364540158 ActlEngPrcntTorqueHighResolution "This parameter displays an additional torque in percent of the reference engine torque.";
CM_ SG_ 2364540158 EngTorqueMode "State signal which indicates which engine torque mode is currently generating, limiting, or controlling the torque.  Note ...";
CM_ BO_ 2566768126 "Message for reporting identification and information about the physical ECU and its hardware, such as the ECU's part 
number, serial number, build date, etc.  Information about the software within the ECU should be reported using the 
Software Identifi";
CM_ SG_ 2566768126 ECUType "The type of ECU.  One example of a use of the ECU type could be for classifying ECU capabilities, such as I/O.";
CM_ SG_ 2566768126 ECULocation "The location of the ECU within a network.";
CM_ SG_ 2566768126 ECUSerialNumber "The serial number of the physical ECU.";
CM_ SG_ 2566768126 ECUPartNumber "The part number of the physical ECU.";
CM_ SG_ 2566804734 EngMinContinuousTorque "Applied limit for minimum continuous engine torque ...";
CM_ SG_ 2566804734 EngMaxContinuousTorque "Applied limit for maximum continuous engine torque.";
CM_ SG_ 2566804734 EngMinContinuousRPM "Applied limit for minimum continuous engine RPM ...";
CM_ SG_ 2566804734 EngMaxContinuousRPM "Applied limit for maximum continuous engine RPM ...";
CM_ SG_ 2566804734 EngHghLmtThrshldFrMnCntnsTrqFrmE "Maximum allowable value for minimum continuous torque from engine ...";
CM_ SG_ 2566804734 EngLwLmtThrshldFrMxTorqueFromEng "Minimum allowable value for maximum continuous torque from engine ...";
CM_ SG_ 2566804734 EngHghLmtThrshldFrMnCntnusEngRPM "Maximum allowable value for minimum continuous RPM from engine ...";
CM_ SG_ 2566804734 EngLwLmtThrsholdForMaxRPMFromEng "Minimum allowable value for maximum continuous RPM from engine ...";
CM_ BO_ 2566841342 "This map describes the stationary behavior of the engine and the speed dependent available indicated torque.  This map ...";
CM_ SG_ 2566841342 SupportTSC1CtrlPurposeGroup4 "This parameter indicates which TSC1 control purposes are supported in group 4 of 4. One bit is used to convey the ...";
CM_ SG_ 2566841342 SupportTSC1CtrlPurposeGroup3 "This parameter indicates which TSC1 control purposes are supported in group 3 of 4. One bit is used to convey the ...";
CM_ SG_ 2566841342 SupportTSC1CtrlPurposeGroup2 "This parameter indicates which TSC1 control purposes are supported in group 2 of 4. One bit is used to convey the ...";
CM_ SG_ 2566841342 SupportTSC1CtrlPurposeGroup1 "This parameter indicates which TSC1 control purposes are supported in group 1 of 4. One bit is used to convey the ...";
CM_ SG_ 2566841342 SupportVariableRateTSC1Message "This parameter indicates which TSC1 transmission rates are supported by the engine ECU in addition to the required ...";
CM_ SG_ 2566841342 EngDefaultTorqueLimit "Companion parameter to Transmission Torque Limit (SPN 1845).  This “echo” parameter provides confirmation to the ...";
CM_ SG_ 2566841342 EngMomentOfInertia "Moment of inertia for the engine, including items driven full-time by the engine such as fuel, oil and cooling pumps.  The ...";
CM_ SG_ 2566841342 EngExRngRqstdSpdCtrlRngUpprLimit "The maximum engine speed regardless of load that the engine will allow when operating in a speed control/limit mode, ...";
CM_ SG_ 2566841342 EngRqstdTrqueCtrlRangeUpperLimit "The maximum engine torque that the engine will allow when operating in a torque control/limit mode.";
CM_ SG_ 2566841342 EngRqstdTrqueCtrlRangeLowerLimit "The minimum engine torque that the engine will allow when operating in a torque control/limit mode.";
CM_ SG_ 2566841342 EngRqstdSpeedCtrlRangeUpperLimit "The maximum engine speed regardless of load that the engine will allow when operating in a speed control/limit mode, ...";
CM_ SG_ 2566841342 EngRqstdSpeedCtrlRangeLowerLimit "The minimum engine speed that the engine will allow when operating in a speed control/limit mode.";
CM_ SG_ 2566841342 EngMaxMomentaryOverrideTimeLimit "The maximum time limit allowed to override the engine's high idle speed.";
CM_ SG_ 2566841342 EngMxMmentaryOverrideSpeedPoint7 "The maximum engine speed above high idle allowed by the engine control during a momentary high idle override.  This ...";
CM_ SG_ 2566841342 EngReferenceTorque "This parameter is the 100% reference value for all defined indicated engine torque parameters.  It is only defined once ...";
CM_ SG_ 2566841342 EngGain "The endspeed governor is defined as a linear line with the following equations (Capital letters mean physical values, small ...";
CM_ SG_ 2566841342 EngSpeedAtHighIdlePoint6 "Engine speed of high idle (point 6) of the engine torque map (see PGN 65251 and supporting document).  In engine ...";
CM_ SG_ 2566841342 EngPercentTorqueAtPoint5 "The torque limit that indicates the available engine torque which can be provided by the engine at point 3, 4, and 5 of the ...";
CM_ SG_ 2566841342 EngSpeedAtPoint5 "Engine speed of point 3, 4, and 5 of the engine torque map (see PGN 65251 and supporting document).  It is ...";
CM_ SG_ 2566841342 EngPercentTorqueAtPoint4 "The torque limit that indicates the available engine torque which can be provided by the engine at point 3, 4, and 5 of the ...";
CM_ SG_ 2566841342 EngSpeedAtPoint4 "Engine speed of point 3, 4, and 5 of the engine torque map (see PGN 65251 and supporting document).  It is ...";
CM_ SG_ 2566841342 EngPercentTorqueAtPoint3 "The torque limit that indicates the available engine torque which can be provided by the engine at point 3, 4, and 5 of the ...";
CM_ SG_ 2566841342 EngSpeedAtPoint3 "Engine speed of point 3, 4, and 5 of the engine torque map (see PGN 65251 and supporting document).  It is ...";
CM_ SG_ 2566841342 EngPercentTorqueAtPoint2 "The torque limit that indicates the available engine torque which can be provided by the engine at point 2 of the engine ...";
CM_ SG_ 2566841342 EngSpeedAtPoint2 "Engine speed of point 2 of the engine torque map (see PGN 65251 and supporting document).  In engine configuration ...";
CM_ SG_ 2566841342 EngPercentTorqueAtIdlePoint1 "The torque limit that indicates the available engine torque which can be provided by the engine at idle speed.  This ...";
CM_ SG_ 2566841342 EngSpeedAtIdlePoint1 "Stationary low idle speed of engine which includes influences due to engine temperature (after power up) and other ...";
CM_ BO_ 2566767870 "Used for information on brake control.";
CM_ SG_ 2566767870 EmergencyBrakingActive "Signal which indicates an emergency braking situation (ref. ECE Regulation 13 paragraph 5.2.1.31) with high ...";
CM_ SG_ 2566767870 PrkngBrakeActuatorFullyActivated "Signal which indicates when the parking brake actuator is fully activated.  (see also SPN 70 and 619).";
CM_ SG_ 2566767870 XBRAccelerationLimit "The brake system may temporarily or generally limit the maximum brake performance available for external systems. A ...";
CM_ SG_ 2566767870 XBRActiveCtrlMode "This parameter indicates which XBR Control Mode is executed by the brake system.";
CM_ SG_ 2566767870 XBRSystemState "This parameter indicates which external brake control is allowed.";
CM_ SG_ 2566767870 FoundationBrakeUse "This parameter indicates if the brake system presently uses the foundation brakes.";
CM_ SG_ 2566767870 HillHolderMode "Signal which indicates the current mode of the hill holder function.";
CM_ SG_ 2566767870 HaltBrakeMode "Signal which indicates the current mode of the halt brake function.";
CM_ SG_ 2566767870 BrakeTempWarning "This parameter indicates if the temperature in the service brakes exceeds a certain value. It can be used for a warning ...";
CM_ SG_ 2633936126 BrkLnngRmningRearAxle3RightWheel "The percentage of brake lining which can still be measured for the right wheel on the rear axle #3.  100% represents new ...";
CM_ SG_ 2633936126 BrkLnngRminingRearAxle3LeftWheel "The percentage of brake lining which can still be measured for the left wheel on the rear axle #3.  100% represents new ...";
CM_ SG_ 2633936126 BrkLnngRmningRearAxle2RightWheel "The percentage of brake lining which can still be measured for the right wheel on the rear axle #2.  100% represents new ...";
CM_ SG_ 2633936126 BrkLnngRminingRearAxle2LeftWheel "The percentage of brake lining which can still be measured for the left wheel on the rear axle #2.  100% represents new ...";
CM_ SG_ 2633936126 BrkLnngRmningRearAxle1RightWheel "The percentage of brake lining which can still be measured for the right wheel on the rear axle #1.  100% represents new ...";
CM_ SG_ 2633936126 BrkLnngRminingRearAxle1LeftWheel "The percentage of brake lining which can still be measured for the left wheel on the rear axle #1.  100% represents new ...";
CM_ SG_ 2633936126 BrkLnngRmningFrontAxleRightWheel "The percentage of brake lining which can still be measured for the right wheel on the front axle.  100% represents new ...";
CM_ SG_ 2633936126 BrkLnngRminingFrontAxleLeftWheel "The percentage of brake lining which can still be measured for the left wheel on the front axle.  100% represents new ...";
CM_ SG_ 2566827518 BrkAppPrssHghRngRrAxl3RightWheel "The brake application pressure for the right wheel on the rear axle #3.";
CM_ SG_ 2566827518 BrkAppPrssHghRngRrAxle3LeftWheel "The brake application pressure for the left wheel on the rear axle #3.";
CM_ SG_ 2566827518 BrkAppPrssHghRngRrAxl2RightWheel "The brake application pressure for the right wheel on the rear axle #2.";
CM_ SG_ 2566827518 BrkAppPrssHghRngRrAxle2LeftWheel "The brake application pressure for the left wheel on the rear axle #2.";
CM_ SG_ 2566827518 BrkAppPrssHghRngRrAxle1LeftWheel "The brake application pressure for the left wheel on the rear axle #1.";
CM_ SG_ 2566827518 BrkAppPrssHghRngFrntAxlRghtWheel "The brake application pressure for the right wheel on the front axle.";
CM_ SG_ 2566827518 BrkAppPrssHghRngFrntAxlLeftWheel "The brake application pressure for the left wheel on the front axle.";
CM_ SG_ 2566827518 BrkAppPrssHghRngRrAxl1RightWheel "The brake application pressure for the right wheel on the rear axle #1.";
CM_ SG_ 2566832126 RelativeSpeedRearAxle2RightWheel "The speed of the rear axle #2, right wheel relative to the front axle speed, SPN 904.";
CM_ SG_ 2566832126 RelativeSpeedRearAxle2LeftWheel "The speed of the rear axle #2, left wheel relative to the front axle speed, SPN 904.";
CM_ SG_ 2566832126 RelativeSpeedRearAxle1RightWheel "The speed of the rear axle #1, right wheel relative to the front axle speed, SPN 904.";
CM_ SG_ 2566832126 RelativeSpeedRearAxle1LeftWheel "The speed of the rear axle #1, left wheel relative to the front axle speed, SPN 904.";
CM_ SG_ 2566832126 RelativeSpeedFrontAxleRightWheel "The speed of the front axle, right wheel relative to the front axle speed, SPN 904.";
CM_ SG_ 2566832126 RelativeSpeedFrontAxleLeftWheel "The speed of the front axle, left wheel relative to the front axle speed, SPN 904.";
CM_ SG_ 2566832126 FrontAxleSpeed "The average speed of the two front wheels.";
CM_ BO_ 2565865982 "Used for brake control information ...";
CM_ SG_ 2565865982 TrctrMntdTrailerABSWarningSignal "This parameter commands the tractor-mounted trailer ABS optical warning signal.";
CM_ SG_ 2565865982 TrailerABSStatus "State signal which indicates that ABS in the trailer is actively controlling the brakes.  A message is sent to the tractor from ...";
CM_ SG_ 2565865982 HaltBrakeSwitch "Switch signal which indicates the position of the halt brake switch.";
CM_ SG_ 2565865982 SrcAddrssOfCntrllngDvcFrBrkeCtrl "The source address of the SAE J1939 device currently controlling the brake system. Its value may be the source address ...";
CM_ SG_ 2565865982 ATC_ASRInformationSignal "This parameter commands the ATC/ASR driver information signal, for example a dash lamp.";
CM_ SG_ 2565865982 ABS_EBSAmberWarningSignal "This parameter commands the ABS/EBS amber/yellow optical warning signal ...";
CM_ SG_ 2565865982 EBSRedWarningSignal "This parameter commands the EBS red optical warning signal ...";
CM_ SG_ 2565865982 ABSFullyOperational "Signal which indicates whether an ABS system is fully operational or whether its functionality is reduced by a defect or by ...";
CM_ SG_ 2565865982 EngRetarderSelection "The position of the operator controlled selector, expressed as a percentage and determined by the ratio of the current ...";
CM_ SG_ 2565865982 RemoteAccelEnableSwitch "Switch signal which indicates that the remote accelerator has been enabled and controls the engine.";
CM_ SG_ 2565865982 EngAuxShutdownSwitch "Switch signal which requests that all engine fueling stop.";
CM_ SG_ 2565865982 EngDerateSwitch "Switch signal used to activate the torque limiting feature of the engine.  The specific nature of torque limiting should be ...";
CM_ SG_ 2565865982 AccelInterlockSwitch "Switch signal used to disable the accelerator and remote accelerator inputs, causing the engine to return to idle.";
CM_ SG_ 2565865982 TractionCtrlOverrideSwitch "Switch signal which indicates the position of the traction control override switch.  The traction control override signal ...";
CM_ SG_ 2565865982 ASRHillHolderSwitch "Switch signal which indicates the position of the ASR “hill holder” switch.";
CM_ SG_ 2565865982 ASROffroadSwitch "Switch signal which indicates the position of the ASR off-road switch.";
CM_ SG_ 2565865982 ABSOffroadSwitch "Switch signal which indicates the position of the ABS off-road switch.";
CM_ SG_ 2565865982 BrakePedalPos "Ratio of brake pedal position to maximum pedal position.  Used for electric brake applications. 0% means no braking.";
CM_ SG_ 2565865982 EBSBrakeSwitch "Switch signal which indicates that the brake pedal is being pressed.  The EBS brake switch is independent of the brake ...";
CM_ SG_ 2565865982 AntiLockBrakingActive "State signal which indicates that the ABS is active.  The signal is set active when wheel brake pressure actually starts to ...";
CM_ SG_ 2565865982 ASRBrakeCtrlActive "State signal which indicates that ASR brake control is active. Active means that ASR actually controls wheel brake ...";
CM_ SG_ 2565865982 ASREngCtrlActive "State signal which indicates that ASR engine control has been commanded to be active. Active means that ASR actually ...";
CM_ BO_ 2565867262 "NOTE - Request has to be responded to with as many messages as necessary to transmit all available information.";
CM_ SG_ 2565867262 RearAxleGroupEngagementStatus "Rear axle group engagement status ...";
CM_ SG_ 2565867262 FrontAxleGroupEngagementStatus "Front axle group engagement status ...";
CM_ SG_ 2565867262 DiffLockStateCentralRear "State used which indicates the condition of the central rear differential lock.  The differential locks are located as defined ...";
CM_ SG_ 2565867262 DiffLockStateCentralFront "State used which indicates the condition of the central front differential lock.  The differential locks are located as defined ...";
CM_ SG_ 2565867262 DiffLockStateCentral "State used which indicates the condition of the central differential lock.  The differential locks are located as defined in ...";
CM_ SG_ 2565867262 DiffLockStateRearAxle2 "State used which indicates the condition of the rear axle 2 differential lock.  The differential locks are located as defined in ...";
CM_ SG_ 2565867262 DiffLockStateRearAxle1 "State used which indicates the condition of the rear axle 1 differential lock.  The differential locks are located as defined in ...";
CM_ SG_ 2565867262 DiffLockStateFrontAxle2 "State used which indicates the condition of the front axle 2 differential lock. The differential locks are located as defined in ...";
CM_ SG_ 2565867262 DiffLockStateFrontAxle1 "State used which indicates the condition of the front axle 1 differential lock.  The differential locks are located as defined ...";
CM_ SG_ 2565867262 Location "To identify to which of several similar devices (such as tires or fuel tanks) the information applies.";
CM_ SG_ 2566821118 EngExRangeCoolantPress "Gage pressure of liquid found in engine cooling system.";
CM_ SG_ 2566821118 SeaWaterPumpOutletPress "Gauge pressure of liquid found at outlet of sea water pump in sea water cooling system.";
CM_ SG_ 2566821118 EngAuxCoolantTemp "Temperature of coolant found in the intercooler which is located after the turbocharger.";
CM_ SG_ 2566821118 EngAuxCoolantPress "Gage pressure of coolant found in the intercooler which is located after the turbocharger.";
CM_ BO_ 2566810622 "Field: a Driver 1 Identification Delimiter (ASCII “*”) 
       b Driver 2 Identification Delimiter (ASCII “*”) 
 
NOTE - If only driver card 1 is present, only the parameter driver 1 identification and two delimiters shall be transmitted.";
CM_ SG_ 2566810622 Driver2Identification "Used to obtain the driver identity.";
CM_ SG_ 2566810622 Driver1Identification "Used to obtain the driver identity.";
CM_ SG_ 2566847742 FuelLevel2 "Ratio of volume of fuel to the total volume of fuel in the second or right-side storage container.  When Fuel Level 2 is not ...";
CM_ SG_ 2566847742 CargoAmbientTemp "Temperature of air inside vehicle container used to accommodate cargo.";
CM_ SG_ 2566847742 EngOilFilterDiffPress "Change in engine oil pressure, measured across the filter, due to the filter and any accumulation of solid or semisolid ...";
CM_ SG_ 2566847742 EngFuelFilterDiffPress "Change in fuel delivery pressure, measured across the filter, due to accumulation of solid or semisolid matter on the filter ...";
CM_ SG_ 2566847742 FuelLevel1 "Ratio of volume of fuel to the total volume of fuel storage container.";
CM_ SG_ 2566847742 WasherFluidLevel "Ratio of volume of liquid to total container volume of fluid reservoir in windshield wash system.";
CM_ BO_ 2566768382 "Cold start aid information and settings.";
CM_ SG_ 2566768382 EngCldStrtFlIgniterRelayFeedback "Feedback state of the engine cold start fuel igniter relay which indicates the status of the relay output.";
CM_ SG_ 2566768382 EngColdStartFuelIgniterRelay "The engine cold start fuel igniter relay control command.  This command controls the relay, not the igniter.";
CM_ SG_ 2566768382 EngColdStartFuelIgniterCmd "The engine cold start fuel igniter control command, normalized to %, where 0% represents fully off and 100% represents ...";
CM_ SG_ 2566768382 EngStartEnableDevice2Config "The start enable device installed for start enable device 2.";
CM_ SG_ 2566768382 EngStartEnableDevice1Config "The start enable device installed for start enable device 1.";
CM_ SG_ 2566768382 EngStartEnableDevice2 "Devices that assist an engine in starting, e.g. intake heaters, ether, or an alternate/secondary starting aid.  May be of the ...";
CM_ SG_ 2566768382 EngStartEnableDevice1 "Devices that assist an Engine in starting, e.g. intake heaters and ether.  Primary starting aid.";
CM_ SG_ 2566811902 PoweredVehicleWeight "Total mass imposed by the tires of the powered vehicle on the road surface.  Does not include the trailer.";
CM_ SG_ 2566811902 GrossCombinationVehicleWeight "The total weight of the truck and all attached trailers.";
CM_ SG_ 2563768062 MxCntinuousRetarderTorqueLimitRq "Requested maximum continuous retarder torque (operating range: -125 to 0%) ...";
CM_ SG_ 2563768062 MnCntinuousRetarderTorqueLimitRq "Requested minimum continuous retarder torque (operating range: -125 to 0%) ...";
CM_ SG_ 2563768062 MxContinuousRetarderSpeedLimitRq "Requested maximum continuous retarder speed ...";
CM_ SG_ 2563768062 MnContinuousRetarderSpeedLimitRq "Requested minimum continuous retarder speed ...";
CM_ SG_ 2563768062 EngTorqueLimitRqMaxContinuous "Requested maximum continuous engine torque (operating range: 0 to 125%) ...";
CM_ SG_ 2563768062 EngTorqueLimitRqMinContinuous "Requested minimum continuous engine torque (operating range: 0 to 125%) ...";
CM_ SG_ 2563768062 EngSpeedLimitRqMaxContinuous "Requested maximum continuous engine speed ...";
CM_ SG_ 2563768062 EngSpeedLimitRqMinContinuous "Requested minimum continuous engine speed ...";
CM_ SG_ 2633924862 EngAverageCombustionTime "The average combustion time of all cylinders of an engine.";
CM_ SG_ 2633924862 EngDesiredCombustionTime "The desired combustion time based upon engine load and speed lookup maps.";
CM_ SG_ 2633924606 EngCyl20CombustionTime "The amount of time from when the ignition of the fuel is initiated to when the fuel is completely ignited (i.e., the flame front ...";
CM_ SG_ 2633924606 EngCyl19CombustionTime "The amount of time from when the ignition of the fuel is initiated to when the fuel is completely ignited (i.e., the flame front ...";
CM_ SG_ 2633924606 EngCyl18CombustionTime "The amount of time from when the ignition of the fuel is initiated to when the fuel is completely ignited (i.e., the flame front ...";
CM_ SG_ 2633924606 EngCyl17CombustionTime "The amount of time from when the ignition of the fuel is initiated to when the fuel is completely ignited (i.e., the flame front ...";
CM_ SG_ 2633924350 EngCyl16CombustionTime "The amount of time from when the ignition of the fuel is initiated to when the fuel is completely ignited (i.e., the flame front ...";
CM_ SG_ 2633924350 EngCyl15CombustionTime "The amount of time from when the ignition of the fuel is initiated to when the fuel is completely ignited (i.e., the flame front ...";
CM_ SG_ 2633924350 EngCyl14CombustionTime "The amount of time from when the ignition of the fuel is initiated to when the fuel is completely ignited (i.e., the flame front ...";
CM_ SG_ 2633924350 EngCyl13CombustionTime "The amount of time from when the ignition of the fuel is initiated to when the fuel is completely ignited (i.e., the flame front ...";
CM_ SG_ 2633924094 EngCyl12CombustionTime "The amount of time from when the ignition of the fuel is initiated to when the fuel is completely ignited (i.e., the flame front ...";
CM_ SG_ 2633924094 EngCyl11CombustionTime "The amount of time from when the ignition of the fuel is initiated to when the fuel is completely ignited (i.e., the flame front ...";
CM_ SG_ 2633924094 EngCyl10CombustionTime "The amount of time from when the ignition of the fuel is initiated to when the fuel is completely ignited (i.e., the flame front ...";
CM_ SG_ 2633924094 EngCyl9CombustionTime "The amount of time from when the ignition of the fuel is initiated to when the fuel is completely ignited (i.e., the flame front ...";
CM_ SG_ 2633923838 EngCyl8CombustionTime "The amount of time from when the ignition of the fuel is initiated to when the fuel is completely ignited (i.e., the flame front ...";
CM_ SG_ 2633923838 EngCyl7CombustionTime "The amount of time from when the ignition of the fuel is initiated to when the fuel is completely ignited (i.e., the flame front ...";
CM_ SG_ 2633923838 EngCyl6CombustionTime "The amount of time from when the ignition of the fuel is initiated to when the fuel is completely ignited (i.e., the flame front ...";
CM_ SG_ 2633923838 EngCyl5CombustionTime "The amount of time from when the ignition of the fuel is initiated to when the fuel is completely ignited (i.e., the flame front ...";
CM_ SG_ 2633923582 EngCyl4CombustionTime "The amount of time from when the ignition of the fuel is initiated to when the fuel is completely ignited (i.e., the flame front ...";
CM_ SG_ 2633923582 EngCyl3CombustionTime "The amount of time from when the ignition of the fuel is initiated to when the fuel is completely ignited (i.e., the flame front ...";
CM_ SG_ 2633923582 EngCyl2CombustionTime "The amount of time from when the ignition of the fuel is initiated to when the fuel is completely ignited (i.e., the flame front ...";
CM_ SG_ 2633923582 EngCyl1CombustionTime "The amount of time from when the ignition of the fuel is initiated to when the fuel is completely ignited (i.e., the flame front ...";
CM_ BO_ 2633878014 "Information relating to electronic control modules ...";
CM_ SG_ 2633878014 TotalCountOfConfigChangesMade "Total number of times changes have been made to any of the configurable parameters.";
CM_ BO_ 2566771966 "Provides information from Cab mounted operator inputs.";
CM_ SG_ 2566771966 TransOilLevelRq "Conveys operator or vehicle system desire for a transmission oil level reading to be taken.";
CM_ SG_ 2566771966 FifthWheelReleaseCtrl "Operator input used to release the fifth wheel. Fifth Wheel Release Control Security Lockout and other conditions must be ...";
CM_ SG_ 2566771966 FfthWhlRleaseCtrlSecurityLockout "Operator's fifth wheel release control interlock. This operator input must be enabled prior to activating the fifth wheel ...";
CM_ SG_ 2566771966 TransferCaseSelectorSwitch "000:    2 wheel high (Normal or ‘On Highway’ Range) ...";
CM_ BO_ 2564882174 "Message containing parameters originating from the vehicle cab.";
CM_ SG_ 2564882174 SelectedMaxVehicleSpeedLimit "User selected maximum vehicle speed.  If one is selected, then this SPN must equal one of the maximum vehicle speeds ...";
CM_ SG_ 2564882174 RqCabZoneHeating "Request to activate cab zone heating.";
CM_ SG_ 2564882174 RqEngZoneHeating "Request to activate engine zone heating.";
CM_ SG_ 2564882174 AuxHeaterModeRq "Request to activate the auxiliary heater.";
CM_ SG_ 2564882174 EngAutomaticStartEnableSwitch "Switch signal which enables the idle management system to be enabled. When this system is enabled with the engine in ...";
CM_ SG_ 2564882174 AtomaticGearShiftingEnableSwitch "Indicates that automated gear shifting is enabled via a switch ...";
CM_ SG_ 2564882174 DslPrtcltFltrRgnrtionForceSwitch "Indicates the state of a switch available to the operator that forces diesel particulate filter regeneration.";
CM_ SG_ 2564882174 DslPrtcltFltrRgnrtnInhibitSwitch "Indicates the state of a switch available to the operator that inhibits diesel particulate filter regeneration.";
CM_ SG_ 2564882174 VhclLmtngSpdGovernorEnableSwitch "Switch signal which enables the Vehicle Limiting Speed Governor (VLSG) such that the vehicle speed may be either ...";
CM_ SG_ 2564882174 VhclLmtngSpdGvrnrIncrementSwitch "Switch signal which increases the Vehicle Limiting Speed Governor (VLSG).";
CM_ SG_ 2564882174 VhclLmtngSpdGvrnrDecrementSwitch "Switch signal which decreases the Vehicle Limiting Speed Governor (VLSG).";
CM_ SG_ 2564882174 ParkBrakeCmd "Request by a secondary device to command the Park Brake.  The Park Brake controller should treat this as a request and ...";
CM_ SG_ 2564882174 SeatBeltSwitch "State of switch used to determine if Seat Belt is buckled ...";
CM_ SG_ 2564882174 OperatorSeatDirectionSwitch "Senses whether the operator seat is in the forward driving position ...";
CM_ SG_ 2564882174 BatteryMainSwitchHoldRq "Request to hold the battery main switch.";
CM_ SG_ 2564882174 AuxHeaterCoolantPumpRq "Indicates whether to activate the auxiliary heater coolant water pump.";
CM_ SG_ 2564882174 CabInteriorTempCmd "Parameter used to command a certain cab interior temperature.";
CM_ SG_ 2564882174 RequestedPercentFanSpeed "Fan speed as a ratio of the actual fan drive (current speed) to the fully engaged fan drive (maximum fan speed).  A two ...";
CM_ BO_ 2563833598 "This message contains information that controls illumination devices inside the vehicle's cab.";
CM_ SG_ 2563833598 SwtchBcklghtIllmntnBrghtnssPrcnt "Commanded switch backlight brightness level for all operator control switches.  This is separate from the cab display ...";
CM_ SG_ 2563833598 IlluminationBrightnessPercent "Commanded backlight brightness level for all cab displays.";
CM_ BO_ 2566843390 "NOTE - The make, model, serial number and unit number fields in this message are optional and separated by an ASCII 
“*”.  It is not necessary to include all fields; however, the delimiter (“*”) is always required.";
CM_ SG_ 2566843390 UnitNumber "Owner assigned unit number for the power unit of the vehicle.";
CM_ SG_ 2566843390 SerialNumber "Serial number of the component.";
CM_ SG_ 2566843390 Model "Model of the component.";
CM_ SG_ 2566843390 Make "Make of the component corresponding to the codes defined in the American Trucking Association Vehicle Maintenance ...";
CM_ BO_ 2566844926 "Cruise Control/Vehicle Speed 1 ...";
CM_ SG_ 2566844926 EngShutdownOverrideSwitch "Switch signal which indicates the position of the engine shutdown override switch.  This switch function allows the ...";
CM_ SG_ 2566844926 EngTestModeSwitch "Switch signal which indicates the position of the engine test mode switch.";
CM_ SG_ 2566844926 EngIdleDecrementSwitch "Switch signal which indicates the position of the idle decrement switch.";
CM_ SG_ 2566844926 EngIdleIncrementSwitch "Switch signal which indicates the position of the idle increment switch.";
CM_ SG_ 2566844926 CruiseCtrlStates "This parameter is used to indicate the current state, or mode, of operation by the cruise control device.  This is a status ...";
CM_ SG_ 2566844926 PTOGovernorState "This parameter is used to indicate the current state or mode of operation by the power takeoff (PTO) governor.  In lieu of ...";
CM_ SG_ 2566844926 CruiseCtrlSetSpeed "Value of set (chosen) velocity of velocity control system.";
CM_ SG_ 2566844926 CruiseCtrlAccelerateSwitch "Switch signal of the cruise control activator which indicates that the activator is in the position “accelerate.” ...";
CM_ SG_ 2566844926 CruiseCtrlResumeSwitch "Switch signal of the cruise control activator which indicates that the activator is in the position “resume.” ...";
CM_ SG_ 2566844926 CruiseCtrlCoastSwitch "Switch signal of the cruise control activator which indicates that the activator is in the position “coast (decelerate).” ...";
CM_ SG_ 2566844926 CruiseCtrlSetSwitch "Switch signal of the cruise control activator which indicates that the activator is in the position “set.” ...";
CM_ SG_ 2566844926 ClutchSwitch "Switch signal which indicates that the clutch pedal is being pressed. It is necessary for a safe drivetrain behavior that the ...";
CM_ SG_ 2566844926 BrakeSwitch "Switch signal which indicates that the driver operated brake foot pedal is being pressed.  This brake foot pedal is ...";
CM_ SG_ 2566844926 CruiseCtrlEnableSwitch "Switch signal which indicates that it is possible to manage the cruise control function.";
CM_ SG_ 2566844926 CruiseCtrlActive "Cruise control is switched on.  It is not ensured that the engine is controlled by cruise control, as in the case of a large ...";
CM_ SG_ 2566844926 WheelBasedVehicleSpeed "Speed of the vehicle as calculated from wheel or tailshaft speed.";
CM_ SG_ 2566844926 ParkBrakeReleaseInhibitRq "Park Brake Release Inhibit Request signals the desire that an applied park brake remain applied and limit the ability of the ...";
CM_ SG_ 2566844926 CruiseCtrlPauseSwitch "Switch signal which indicates the position of the Cruise Control Pause Switch used on Remote Cruise Control ...";
CM_ SG_ 2566844926 ParkingBrakeSwitch "Switch signal which indicates when the parking brake is set. In general the switch actuated by the operator's park brake ...";
CM_ SG_ 2566844926 TwoSpeedAxleSwitch "Switch signal which indicates the current axle range.";
CM_ SG_ 2566843902 CruiseCtrlLowSetLimitSpeed "Minimum vehicle velocity at which cruise can be set or minimum vehicle velocity for cruise operation before it will exit ...";
CM_ SG_ 2566843902 CruiseCtrlHighSetLimitSpeed "Maximum vehicle velocity at which cruise can be set.";
CM_ SG_ 2566843902 MaxVehicleSpeedLimit "Maximum vehicle velocity allowed.";
CM_ SG_ 2566809598 AuxHeaterMaxOutputPower "The maximum output power of the auxiliary heater.";
CM_ SG_ 2633940222 TripServiceBrakeApplications "Total number of times the service brakes have been activated since the last trip reset.  Brake applications of less than 0.5 ...";
CM_ SG_ 2633940222 TripServiceBrakeDistance "Total distance over which the service brakes have been active since the last trip reset.";
CM_ SG_ 2633940222 TripCompressionBrakeDistance "Total distance over which the compression brakes have been active since the last trip reset.";
CM_ SG_ 2633940222 TotalCompressionBrakeDistance "Total distance over which the compression brakes have been active for the life of the engine.";
CM_ BO_ 2566775294 "This message contains measurement and condition information from cab air conditioning components.";
CM_ SG_ 2566775294 CbA_CRfrgrntCmpressorOutletPress "This is the gage pressure at the compressor outlet in the cab air conditioning system.";
CM_ BO_ 2566803710 "Contains battery temperature information.";
CM_ SG_ 2566803710 Battery2Temp "Temperature of the battery 2. The relation to physical location is determined by the equipment manufacturer.";
CM_ SG_ 2566803710 Battery1Temp "Temperature of the battery 1.  The relation to physical location is determined by the equipment manufacturer.";
CM_ BO_ 2566719486 "Message that directly controls the driver indicator lamps.  See also PGN 64774 for additional lamps and PGN 64773 for ...";
CM_ SG_ 2566719486 EngFuelFilterRestrictedLampCmd "Command signal directly controlling the Engine Fuel Filter Restricted Lamp.";
CM_ SG_ 2566719486 EngAirFilterRestrictionLampCmd "Command signal directly controlling the Engine Air Filter Restriction Lamp.";
CM_ SG_ 2566719486 EngIdleManagementActiveLampCmd "Command signal directly controlling the Engine Idle Management Active Lamp ...";
CM_ SG_ 2566719486 EngCoolantLevelLowLampCmd "Command signal directly controlling the Engine Coolant Level Low Lamp ...";
CM_ SG_ 2566719486 EngCoolantTempHighLampCmd "Command signal directly controlling the Engine Coolant Temperature High Lamp ...";
CM_ SG_ 2566719486 EngOilPressLowLampCmd "Command signal directly controlling the Engine Oil Pressure Low Lamp ...";
CM_ SG_ 2566719486 CmprssnBrkEnblSwtchIndctrLampCmd "Command signal directly controlling Compression Brake Enable Switch Indicator Lamp.  The compression brake switch ...";
CM_ SG_ 2566719486 EngBrakeActiveLampCmd "Command signal directly controlling the Engine Brake Active Lamp ...";
CM_ SG_ 2566719486 OBDMalfunctionIndicatorLampCmd "Command signal directly controlling the OBD Malfunction Indicator Lamp ...";
CM_ SG_ 2566719486 EngRedStopLampCmd "Command signal directly controlling the Engine Red Stop Lamp ...";
CM_ SG_ 2566719486 EngAmberWarningLampCmd "Command signal directly controlling the Engine Amber Warning Lamp ...";
CM_ SG_ 2566719486 EngProtectLampCmd "Command signal directly controlling the Engine Protect Lamp ...";
CM_ BO_ 2633832702 "Message containing type and serial number for every sensor of the restraint-system. The Collision Sensor Type is ...";
CM_ SG_ 2633832702 RolloverSensorType "Type of Rollover Sensor.";
CM_ SG_ 2633832702 RearCollisionSensor4Type "Type of Rear Collision Sensor 4.";
CM_ SG_ 2633832702 RearCollisionSensor3Type "Type of Rear Collision Sensor 3.";
CM_ SG_ 2633832702 RearCollisionSensor2Type "Type of Rear Collision Sensor 2.";
CM_ SG_ 2633832702 RearCollisionSensor1Type "Type of Rear Collision Sensor 1.";
CM_ SG_ 2633832702 SideCollisionSensorRearRightType "Type of Side Collision Sensor Rear - Right.";
CM_ SG_ 2633832702 SdCllisionSensorMidRearRightType "Type of Side Collision Sensor Mid Rear - Right.";
CM_ SG_ 2633832702 SdCllsionSensorMidFrontRightType "Type of Side Collision Sensor Mid Front - Right.";
CM_ SG_ 2633832702 SdeCollisionSensorFrontRightType "Type of Side Collision Sensor Front - Right.";
CM_ SG_ 2633832702 SideCollisionSensorRearLeftType "Type of Side Collision Sensor Rear - Left.";
CM_ SG_ 2633832702 SdCollisionSensorMidRearLeftType "Type of Side Collision Sensor Mid Rear - Left.";
CM_ SG_ 2633832702 SdCllisionSensorMidFrontLeftType "Type of Side Collision Sensor Mid Front - Left.";
CM_ SG_ 2633832702 SideCollisionSensorFrontLeftType "Type of Side Collision Sensor Front - Left.";
CM_ SG_ 2633832702 FrontalCollisionSensor4Type "Type of Frontal Collision Sensor 4.";
CM_ SG_ 2633832702 FrontalCollisionSensor3Type "Type of Frontal Collision Sensor 3.";
CM_ SG_ 2633832702 FrontalCollisionSensor2Type "Type of Frontal Collision Sensor 2.";
CM_ SG_ 2633832702 FrontalCollisionSensor1Type "Type of Frontal Collision Sensor 1.";
CM_ BO_ 2163223550 "This message is transmitted in case of a crash event.";
CM_ SG_ 2163223550 CrashChecksum "The Crash Checksum is used to verify the signal path from the airbag ECU to other devices in case of a crash.";
CM_ SG_ 2163223550 CrashCounter "The Crash Counter prevents other ECUs from reacting to a faulty transmission of the Crash Notification PGN and serves ...";
CM_ SG_ 2163223550 CrashType "Type of crash event.";
CM_ BO_ 2566714878 "Engine bank 2 CAC precooler parameters ...";
CM_ SG_ 2566714878 EngChrgArClr2PrecoolerEfficiency "Engine charge air cooler 2 (CAC2) precooler efficiency is an indication of the precooler’s ability to reduce the temperature ...";
CM_ SG_ 2566714878 EngChrgArClr2PrecoolerOutletTemp "Temperature of the combustion air measured at the charge air cooler 2 precooler outlet.";
CM_ SG_ 2566714878 EngChrgArClr2PrecoolerIntakeTemp "Temperature of the combustion air measured at the charge air cooler 2 precooler Intake.";
CM_ BO_ 2566714622 "Engine bank 2 Charge Air Cooler parameters ...";
CM_ SG_ 2566714622 EngChargeAirCooler2Efficiency "Engine charge air cooler 2 (CAC2) is an indication of the CAC’s ability to reduce the temperature of the combustion air ...";
CM_ SG_ 2566714622 EngChrgeAirCooler2AmbientAirTemp "Temperature of the air surrounding charge air cooler 2.";
CM_ SG_ 2566714622 EngChargeAirCooler2OutletTemp "Temperature of combustion air after it exits from the Charge Air Cooler 2 but before any mixing of recirculated exhaust ...";
CM_ SG_ 2566714622 EngChargeAirCooler2IntakeTemp "Temperature of the combustion air measured at the charge air cooler 2 Intake.";
CM_ BO_ 2566715390 "Engine bank 1 CAC precooler parameters ...";
CM_ SG_ 2566715390 EngChrgArClr1PrecoolerEfficiency "Engine charge air cooler 1 (CAC1) precooler efficiency is an indication of the precooler’s ability to reduce the temperature ...";
CM_ SG_ 2566715390 EngChrgArClr1PrecoolerOutletTemp "Temperature of the combustion air measured at the charge air cooler 1 precooler outlet.";
CM_ SG_ 2566715390 EngChrgArClr1PrecoolerIntakeTemp "Temperature of the combustion air measured at the charge air cooler 1 precooler intake.";
CM_ BO_ 2566715134 "Engine bank 1 Charge Air Cooler parameters ...";
CM_ SG_ 2566715134 EngChargeAirCooler1Efficiency "Engine charge air cooler 1(CAC1) efficiency is an indication of the CAC’s ability to reduce the temperature of the ...";
CM_ SG_ 2566715134 EngChrgeAirCooler1AmbientAirTemp "Temperature of the air surrounding charge air cooler 1.";
CM_ SG_ 2566715134 EngChargeAirCooler1IntakeTemp "Temperature of the combustion air measured at the CAC 1 Intake.";
BA_DEF_ SG_  "SigType" ENUM  "Default","Range","RangeSigned","ASCII","Discrete","Control","ReferencePGN","DTC","StringDelimiter","StringLength","StringLengthControl";
BA_DEF_ SG_  "GenSigStartValue" INT 0 10000;
BA_DEF_ SG_  "GenSigSendType" ENUM  "Cyclic","OnWrite","OnWriteWithRepetition","OnChange","OnChangeWithRepetition","IfActive","IfActiveWithRepetition","NoSigSendType";
BA_DEF_ SG_  "GenSigILSupport" ENUM  "No","Yes";
BA_DEF_ SG_  "GenSigEVName" STRING ;
BA_DEF_ SG_  "SPN" INT 0 524287;
BA_DEF_ BO_  "GenMsgStartDelayTime" INT 0 100000;
BA_DEF_ BO_  "GenMsgILSupport" ENUM  "No","Yes";
BA_DEF_ BO_  "GenMsgRequestable" INT 0 1;
BA_DEF_ BO_  "GenMsgSendType" ENUM  "cyclic","NotUsed","NotUsed","NotUsed","NotUsed","NotUsed","NotUsed","IfActive","noMsgSendType";
BA_DEF_ BO_  "VFrameFormat" ENUM  "StandardCAN","ExtendedCAN","reserved","J1939PG";
BA_DEF_ BO_  "GenMsgCycleTime" INT 0 3600000;
BA_DEF_ SG_  "SystemSignalLongSymbol" STRING ;
BA_DEF_DEF_  "SigType" "Default";
BA_DEF_DEF_  "GenSigStartValue" 0;
BA_DEF_DEF_  "GenSigSendType" "NoSigSendType";
BA_DEF_DEF_  "GenSigILSupport" "Yes";
BA_DEF_DEF_  "GenSigEVName" "Env@Nodename_@Signame";
BA_DEF_DEF_  "SPN" 0;
BA_DEF_DEF_  "GenMsgStartDelayTime" 0;
BA_DEF_DEF_  "GenMsgILSupport" "Yes";
BA_DEF_DEF_  "GenMsgRequestable" 1;
BA_DEF_DEF_  "GenMsgSendType" "noMsgSendType";
BA_DEF_DEF_  "VFrameFormat" "J1939PG";
BA_DEF_DEF_  "GenMsgCycleTime" 0;
BA_DEF_DEF_  "SystemSignalLongSymbol" "";
BA_ "GenMsgSendType" BO_ 2565865726 0;
BA_ "GenMsgCycleTime" BO_ 2565865726 100;
BA_ "GenMsgSendType" BO_ 2633932798 0;
BA_ "GenMsgCycleTime" BO_ 2633932798 1000;
BA_ "GenMsgSendType" BO_ 2566824190 0;
BA_ "GenMsgCycleTime" BO_ 2566824190 1000;
BA_ "GenMsgSendType" BO_ 2633933310 0;
BA_ "GenMsgCycleTime" BO_ 2633933310 1000;
BA_ "GenMsgSendType" BO_ 2633933566 0;
BA_ "GenMsgCycleTime" BO_ 2633933566 1000;
BA_ "GenMsgSendType" BO_ 2633933822 0;
BA_ "GenMsgCycleTime" BO_ 2633933822 1000;
BA_ "GenMsgSendType" BO_ 2365447166 0;
BA_ "GenMsgCycleTime" BO_ 2365447166 100;
BA_ "GenMsgSendType" BO_ 2365446654 0;
BA_ "GenMsgCycleTime" BO_ 2365446654 100;
BA_ "GenMsgSendType" BO_ 2365446142 0;
BA_ "GenMsgCycleTime" BO_ 2365446142 100;
BA_ "GenMsgSendType" BO_ 2633929470 0;
BA_ "GenMsgCycleTime" BO_ 2633929470 100;
BA_ "GenMsgSendType" BO_ 2364541694 0;
BA_ "GenMsgCycleTime" BO_ 2364541694 50;
BA_ "GenMsgSendType" BO_ 2566810366 0;
BA_ "GenMsgCycleTime" BO_ 2566810366 5000;
BA_ "GenMsgSendType" BO_ 2566767102 0;
BA_ "GenMsgCycleTime" BO_ 2566767102 500;
BA_ "GenMsgSendType" BO_ 2566839294 0;
BA_ "GenMsgCycleTime" BO_ 2566839294 5000;
BA_ "GenMsgSendType" BO_ 2566844414 0;
BA_ "GenMsgCycleTime" BO_ 2566844414 5000;
BA_ "GenMsgSendType" BO_ 2633929726 0;
BA_ "GenMsgCycleTime" BO_ 2633929726 100;
BA_ "GenMsgSendType" BO_ 2566840318 0;
BA_ "GenMsgCycleTime" BO_ 2566840318 250;
BA_ "GenMsgSendType" BO_ 2364539902 0;
BA_ "GenMsgCycleTime" BO_ 2364539902 50;
BA_ "GenMsgSendType" BO_ 2364540158 0;
BA_ "GenMsgCycleTime" BO_ 2364540158 100;
BA_ "GenMsgSendType" BO_ 2566804734 0;
BA_ "GenMsgCycleTime" BO_ 2566804734 5000;
BA_ "GenMsgSendType" BO_ 2566841342 0;
BA_ "GenMsgCycleTime" BO_ 2566841342 5000;
BA_ "GenMsgSendType" BO_ 2566767870 0;
BA_ "GenMsgCycleTime" BO_ 2566767870 100;
BA_ "GenMsgSendType" BO_ 2566827518 0;
BA_ "GenMsgCycleTime" BO_ 2566827518 100;
BA_ "GenMsgSendType" BO_ 2566832126 0;
BA_ "GenMsgCycleTime" BO_ 2566832126 100;
BA_ "GenMsgSendType" BO_ 2565865982 0;
BA_ "GenMsgCycleTime" BO_ 2565865982 100;
BA_ "GenMsgSendType" BO_ 2565867262 0;
BA_ "GenMsgCycleTime" BO_ 2565867262 500;
BA_ "GenMsgSendType" BO_ 2566821118 0;
BA_ "GenMsgCycleTime" BO_ 2566821118 5000;
BA_ "GenMsgSendType" BO_ 2563768062 0;
BA_ "GenMsgCycleTime" BO_ 2563768062 5000;
BA_ "GenMsgSendType" BO_ 2566771966 0;
BA_ "GenMsgCycleTime" BO_ 2566771966 10000;
BA_ "GenMsgSendType" BO_ 2564882174 0;
BA_ "GenMsgCycleTime" BO_ 2564882174 1000;
BA_ "GenMsgSendType" BO_ 2563833598 0;
BA_ "GenMsgCycleTime" BO_ 2563833598 5000;
BA_ "GenMsgSendType" BO_ 2566844926 0;
BA_ "GenMsgCycleTime" BO_ 2566844926 100;
BA_ "GenMsgSendType" BO_ 2566775294 0;
BA_ "GenMsgCycleTime" BO_ 2566775294 1000;
BA_ "GenMsgSendType" BO_ 2566803710 0;
BA_ "GenMsgCycleTime" BO_ 2566803710 1000;
BA_ "GenMsgSendType" BO_ 2566719486 0;
BA_ "GenMsgCycleTime" BO_ 2566719486 1000;
BA_ "GenMsgSendType" BO_ 2163223550 0;
BA_ "GenMsgCycleTime" BO_ 2163223550 20;
BA_ "GenMsgSendType" BO_ 2566714878 0;
BA_ "GenMsgCycleTime" BO_ 2566714878 1000;
BA_ "GenMsgSendType" BO_ 2566714622 0;
BA_ "GenMsgCycleTime" BO_ 2566714622 1000;
BA_ "GenMsgSendType" BO_ 2566715390 0;
BA_ "GenMsgCycleTime" BO_ 2566715390 1000;
BA_ "GenMsgSendType" BO_ 2566715134 0;
BA_ "GenMsgCycleTime" BO_ 2566715134 1000;
BA_ "SigType" SG_ 2565865726 ActlMxAvlblRetarderPercentTorque 1;
BA_ "SPN" SG_ 2565865726 ActlMxAvlblRetarderPercentTorque 1717;
BA_ "SigType" SG_ 2565865726 RetarderSelectionNonengine 1;
BA_ "SPN" SG_ 2565865726 RetarderSelectionNonengine 1716;
BA_ "SPN" SG_ 2565865726 DrvrsDemandRetarderPercentTorque 1715;
BA_ "SPN" SG_ 2565865726 SrcAddrssOfCntrllngDvcFrRtrdrCtr 1480;
BA_ "SigType" SG_ 2565865726 RetarderRoadSpeedExceededStatus 5;
BA_ "SPN" SG_ 2565865726 RetarderRoadSpeedExceededStatus 4234;
BA_ "SigType" SG_ 2565865726 RetarderRoadSpeedLimitSwitch 4;
BA_ "SPN" SG_ 2565865726 RetarderRoadSpeedLimitSwitch 4233;
BA_ "SigType" SG_ 2565865726 RetarderRequestingBrakeLight 5;
BA_ "SPN" SG_ 2565865726 RetarderRequestingBrakeLight 1667;
BA_ "SigType" SG_ 2565865726 EngCoolantLoadIncrease 5;
BA_ "SPN" SG_ 2565865726 EngCoolantLoadIncrease 1082;
BA_ "SPN" SG_ 2565865726 IntendedRetarderPercentTorque 1085;
BA_ "SigType" SG_ 2565865726 ActualRetarderPercentTorque 1;
BA_ "SPN" SG_ 2565865726 ActualRetarderPercentTorque 520;
BA_ "SigType" SG_ 2565865726 RetarderEnableShiftAssistSwitch 4;
BA_ "SPN" SG_ 2565865726 RetarderEnableShiftAssistSwitch 572;
BA_ "SigType" SG_ 2565865726 RetarderEnableBrakeAssistSwitch 4;
BA_ "SPN" SG_ 2565865726 RetarderEnableBrakeAssistSwitch 571;
BA_ "SPN" SG_ 2565865726 RetarderTorqueMode 900;
BA_ "SigType" SG_ 2633932798 EngExhaustGasPort20Temp 1;
BA_ "SPN" SG_ 2633932798 EngExhaustGasPort20Temp 1156;
BA_ "SigType" SG_ 2633932798 EngExhaustGasPort19Temp 1;
BA_ "SPN" SG_ 2633932798 EngExhaustGasPort19Temp 1155;
BA_ "SigType" SG_ 2633932798 EngExhaustGasPort18Temp 1;
BA_ "SPN" SG_ 2633932798 EngExhaustGasPort18Temp 1154;
BA_ "SigType" SG_ 2633932798 EngExhaustGasPort17Temp 1;
BA_ "SPN" SG_ 2633932798 EngExhaustGasPort17Temp 1153;
BA_ "SigType" SG_ 2566824190 EngExhaustGasPort16Temp 1;
BA_ "SPN" SG_ 2566824190 EngExhaustGasPort16Temp 1152;
BA_ "SigType" SG_ 2566824190 EngExhaustGasPort15Temp 1;
BA_ "SPN" SG_ 2566824190 EngExhaustGasPort15Temp 1151;
BA_ "SigType" SG_ 2566824190 EngExhaustGasPort14Temp 1;
BA_ "SPN" SG_ 2566824190 EngExhaustGasPort14Temp 1150;
BA_ "SigType" SG_ 2566824190 EngExhaustGasPort13Temp 1;
BA_ "SPN" SG_ 2566824190 EngExhaustGasPort13Temp 1149;
BA_ "SigType" SG_ 2633933310 EngExhaustGasPort12Temp 1;
BA_ "SPN" SG_ 2633933310 EngExhaustGasPort12Temp 1148;
BA_ "SigType" SG_ 2633933310 EngExhaustGasPort11Temp 1;
BA_ "SPN" SG_ 2633933310 EngExhaustGasPort11Temp 1147;
BA_ "SigType" SG_ 2633933310 EngExhaustGasPort10Temp 1;
BA_ "SPN" SG_ 2633933310 EngExhaustGasPort10Temp 1146;
BA_ "SigType" SG_ 2633933310 EngExhaustGasPort9Temp 1;
BA_ "SPN" SG_ 2633933310 EngExhaustGasPort9Temp 1145;
BA_ "SigType" SG_ 2633933566 EngExhaustGasPort8Temp 1;
BA_ "SPN" SG_ 2633933566 EngExhaustGasPort8Temp 1144;
BA_ "SigType" SG_ 2633933566 EngExhaustGasPort7Temp 1;
BA_ "SPN" SG_ 2633933566 EngExhaustGasPort7Temp 1143;
BA_ "SigType" SG_ 2633933566 EngExhaustGasPort6Temp 1;
BA_ "SPN" SG_ 2633933566 EngExhaustGasPort6Temp 1142;
BA_ "SigType" SG_ 2633933566 EngExhaustGasPort5Temp 1;
BA_ "SPN" SG_ 2633933566 EngExhaustGasPort5Temp 1141;
BA_ "SigType" SG_ 2633933822 EngExhaustGasPort4Temp 1;
BA_ "SPN" SG_ 2633933822 EngExhaustGasPort4Temp 1140;
BA_ "SigType" SG_ 2633933822 EngExhaustGasPort3Temp 1;
BA_ "SPN" SG_ 2633933822 EngExhaustGasPort3Temp 1139;
BA_ "SigType" SG_ 2633933822 EngExhaustGasPort2Temp 1;
BA_ "SPN" SG_ 2633933822 EngExhaustGasPort2Temp 1138;
BA_ "SigType" SG_ 2633933822 EngExhaustGasPort1Temp 1;
BA_ "SPN" SG_ 2633933822 EngExhaustGasPort1Temp 1137;
BA_ "SigType" SG_ 2566776062 PayloadPercentage 1;
BA_ "SPN" SG_ 2566776062 PayloadPercentage 2600;
BA_ "SigType" SG_ 2566771454 DataMemoryUsage 1;
BA_ "SPN" SG_ 2566771454 DataMemoryUsage 2802;
BA_ "SigType" SG_ 2566771454 KeepAliveBatteryConsumption 1;
BA_ "SPN" SG_ 2566771454 KeepAliveBatteryConsumption 2803;
BA_ "SigType" SG_ 2566775806 TravelVelocityCtrlPos 1;
BA_ "SPN" SG_ 2566775806 TravelVelocityCtrlPos 2601;
BA_ "SigType" SG_ 2633935358 EngExhstGsOxygnSnsrClsdLpOprtion 5;
BA_ "SPN" SG_ 2633935358 EngExhstGsOxygnSnsrClsdLpOprtion 1696;
BA_ "SPN" SG_ 2633935358 EngExhstGsOxygnSnsrFlngCrrection 1695;
BA_ "SigType" SG_ 2633935358 EngActualExhaustOxygen 1;
BA_ "SPN" SG_ 2633935358 EngActualExhaustOxygen 1119;
BA_ "SigType" SG_ 2633935358 EngDesiredExhaustOxygen 1;
BA_ "SPN" SG_ 2633935358 EngDesiredExhaustOxygen 1118;
BA_ "SigType" SG_ 2633935358 EngDesiredRatedExhaustOxygen 1;
BA_ "SPN" SG_ 2633935358 EngDesiredRatedExhaustOxygen 1117;
BA_ "SigType" SG_ 2365447166 Jystick3GripXAxisDetentPosStatus 4;
BA_ "SPN" SG_ 2365447166 Jystick3GripXAxisDetentPosStatus 2756;
BA_ "SigType" SG_ 2365447166 Jystick3GripYAxisDetentPosStatus 4;
BA_ "SPN" SG_ 2365447166 Jystick3GripYAxisDetentPosStatus 2757;
BA_ "SigType" SG_ 2365447166 Jystick3ThetaAxisDetentPosStatus 4;
BA_ "SPN" SG_ 2365447166 Jystick3ThetaAxisDetentPosStatus 2758;
BA_ "SPN" SG_ 2365447166 Joystick3ThetaAxisPos 2738;
BA_ "SigType" SG_ 2365447166 Jystck3ThtAxsClckwsPstvPosStatus 4;
BA_ "SPN" SG_ 2365447166 Jystck3ThtAxsClckwsPstvPosStatus 2743;
BA_ "SigType" SG_ 2365447166 Jystck3ThetaAxisNeutralPosStatus 4;
BA_ "SPN" SG_ 2365447166 Jystck3ThetaAxisNeutralPosStatus 2753;
BA_ "SPN" SG_ 2365447166 Joystick3GripYAxisPos 2737;
BA_ "SigType" SG_ 2365447166 Jystck3GrpYAxsLvrFrwrdPstvPsStts 4;
BA_ "SPN" SG_ 2365447166 Jystck3GrpYAxsLvrFrwrdPstvPsStts 2742;
BA_ "SigType" SG_ 2365447166 Jystck3GrpYAxsLvrBckNgtvPsStatus 4;
BA_ "SPN" SG_ 2365447166 Jystck3GrpYAxsLvrBckNgtvPsStatus 2747;
BA_ "SigType" SG_ 2365447166 Jystck3GripYAxisNeutralPosStatus 4;
BA_ "SPN" SG_ 2365447166 Jystck3GripYAxisNeutralPosStatus 2752;
BA_ "SPN" SG_ 2365447166 Joystick3GripXAxisPos 2736;
BA_ "SigType" SG_ 2365447166 Jystck3GrpXAxsLvrRghtPstvPsSttus 4;
BA_ "SPN" SG_ 2365447166 Jystck3GrpXAxsLvrRghtPstvPsSttus 2741;
BA_ "SigType" SG_ 2365447166 Jystck3GrpXAxsLvrLftNgtvPsStatus 4;
BA_ "SPN" SG_ 2365447166 Jystck3GrpXAxsLvrLftNgtvPsStatus 2746;
BA_ "SigType" SG_ 2365447166 Jystck3GripXAxisNeutralPosStatus 4;
BA_ "SPN" SG_ 2365447166 Jystck3GripXAxisNeutralPosStatus 2751;
BA_ "SigType" SG_ 2365447166 Jystck3ThtAxsCntrClckwsNgtvPsStt 4;
BA_ "SPN" SG_ 2365447166 Jystck3ThtAxsCntrClckwsNgtvPsStt 2748;
BA_ "SigType" SG_ 2365446654 Jystick2GripXAxisDetentPosStatus 4;
BA_ "SPN" SG_ 2365446654 Jystick2GripXAxisDetentPosStatus 2719;
BA_ "SigType" SG_ 2365446654 Jystick2GripYAxisDetentPosStatus 4;
BA_ "SPN" SG_ 2365446654 Jystick2GripYAxisDetentPosStatus 2720;
BA_ "SigType" SG_ 2365446654 Jystick2ThetaAxisDetentPosStatus 4;
BA_ "SPN" SG_ 2365446654 Jystick2ThetaAxisDetentPosStatus 2721;
BA_ "SPN" SG_ 2365446654 Joystick2ThetaAxisPos 2701;
BA_ "SigType" SG_ 2365446654 Jystck2ThtAxsClckwsPstvPosStatus 4;
BA_ "SPN" SG_ 2365446654 Jystck2ThtAxsClckwsPstvPosStatus 2706;
BA_ "SigType" SG_ 2365446654 Jystck2ThetaAxisNeutralPosStatus 4;
BA_ "SPN" SG_ 2365446654 Jystck2ThetaAxisNeutralPosStatus 2716;
BA_ "SPN" SG_ 2365446654 Joystick2GripYAxisPos 2700;
BA_ "SigType" SG_ 2365446654 Jystck2GrpYAxsLvrFrwrdPstvPsStts 4;
BA_ "SPN" SG_ 2365446654 Jystck2GrpYAxsLvrFrwrdPstvPsStts 2705;
BA_ "SigType" SG_ 2365446654 Jystck2GrpYAxsLvrBckNgtvPsStatus 4;
BA_ "SPN" SG_ 2365446654 Jystck2GrpYAxsLvrBckNgtvPsStatus 2710;
BA_ "SigType" SG_ 2365446654 Jystck2GripYAxisNeutralPosStatus 4;
BA_ "SPN" SG_ 2365446654 Jystck2GripYAxisNeutralPosStatus 2715;
BA_ "SPN" SG_ 2365446654 Joystick2GripXAxisPos 2699;
BA_ "SigType" SG_ 2365446654 Jystck2GrpXAxsLvrRghtPstvPsSttus 4;
BA_ "SPN" SG_ 2365446654 Jystck2GrpXAxsLvrRghtPstvPsSttus 2704;
BA_ "SigType" SG_ 2365446654 Jystck2GrpXAxsLvrLftNgtvPsStatus 4;
BA_ "SPN" SG_ 2365446654 Jystck2GrpXAxsLvrLftNgtvPsStatus 2709;
BA_ "SigType" SG_ 2365446654 Jystck2GripXAxisNeutralPosStatus 4;
BA_ "SPN" SG_ 2365446654 Jystck2GripXAxisNeutralPosStatus 2714;
BA_ "SigType" SG_ 2365446654 Jystck2ThtAxsCntrClckwsNgtvPsStt 4;
BA_ "SPN" SG_ 2365446654 Jystck2ThtAxsCntrClckwsNgtvPsStt 2711;
BA_ "SigType" SG_ 2365446142 Jystick1GripXAxisDetentPosStatus 4;
BA_ "SPN" SG_ 2365446142 Jystick1GripXAxisDetentPosStatus 2682;
BA_ "SigType" SG_ 2365446142 Jystick1GripYAxisDetentPosStatus 4;
BA_ "SPN" SG_ 2365446142 Jystick1GripYAxisDetentPosStatus 2683;
BA_ "SigType" SG_ 2365446142 Jystick1ThetaAxisDetentPosStatus 4;
BA_ "SPN" SG_ 2365446142 Jystick1ThetaAxisDetentPosStatus 2684;
BA_ "SPN" SG_ 2365446142 Joystick1ThetaAxisPos 2664;
BA_ "SigType" SG_ 2365446142 Jystck1ThtAxsClckwsPstvPosStatus 4;
BA_ "SPN" SG_ 2365446142 Jystck1ThtAxsClckwsPstvPosStatus 2669;
BA_ "SigType" SG_ 2365446142 Jystck1ThetaAxisNeutralPosStatus 4;
BA_ "SPN" SG_ 2365446142 Jystck1ThetaAxisNeutralPosStatus 2679;
BA_ "SPN" SG_ 2365446142 Joystick1GripYAxisPos 2663;
BA_ "SigType" SG_ 2365446142 Jystck1GrpYAxsLvrFrwrdPstvPsStts 4;
BA_ "SPN" SG_ 2365446142 Jystck1GrpYAxsLvrFrwrdPstvPsStts 2668;
BA_ "SigType" SG_ 2365446142 Jystck1GrpYAxsLvrBckNgtvPsStatus 4;
BA_ "SPN" SG_ 2365446142 Jystck1GrpYAxsLvrBckNgtvPsStatus 2673;
BA_ "SigType" SG_ 2365446142 Aftrtrtmnt1DslExhstFldPrprtsPrlm 4;
BA_ "SPN" SG_ 2365446142 Aftrtrtmnt1DslExhstFldPrprtsPrlm 2678;
BA_ "SPN" SG_ 2365446142 Joystick1GripXAxisPos 2662;
BA_ "SigType" SG_ 2365446142 Jystck1GrpXAxsLvrRghtPstvPsSttus 4;
BA_ "SPN" SG_ 2365446142 Jystck1GrpXAxsLvrRghtPstvPsSttus 2667;
BA_ "SigType" SG_ 2365446142 Jystck1GrpXAxsLvrLftNgtvPsStatus 4;
BA_ "SPN" SG_ 2365446142 Jystck1GrpXAxsLvrLftNgtvPsStatus 2672;
BA_ "SigType" SG_ 2365446142 Jystck1GripXAxisNeutralPosStatus 4;
BA_ "SPN" SG_ 2365446142 Jystck1GripXAxisNeutralPosStatus 2677;
BA_ "SigType" SG_ 2365446142 Jystck1ThtAxsCntrClckwsNgtvPsStt 4;
BA_ "SPN" SG_ 2365446142 Jystck1ThtAxsCntrClckwsNgtvPsStt 2674;
BA_ "SigType" SG_ 2633929470 EngFuelRackPos 1;
BA_ "SPN" SG_ 2633929470 EngFuelRackPos 1210;
BA_ "SigType" SG_ 2633929470 EngGasMassFlowRate1 1;
BA_ "SPN" SG_ 2633929470 EngGasMassFlowRate1 1241;
BA_ "SigType" SG_ 2633929470 InstantaneousEstBrakePower 1;
BA_ "SPN" SG_ 2633929470 InstantaneousEstBrakePower 1242;
BA_ "SigType" SG_ 2633929470 EngExhaustGasPress1 1;
BA_ "SPN" SG_ 2633929470 EngExhaustGasPress1 1209;
BA_ "SigType" SG_ 2633929470 EngPrefilterOilPress 1;
BA_ "SPN" SG_ 2633929470 EngPrefilterOilPress 1208;
BA_ "SigType" SG_ 2633937406 TotalECURunTime 1;
BA_ "SPN" SG_ 2633937406 TotalECURunTime 1033;
BA_ "SigType" SG_ 2633937406 TotalECUDistance 1;
BA_ "SPN" SG_ 2633937406 TotalECUDistance 1032;
BA_ "SigType" SG_ 2364541694 EngExhstGsRcrcltion2MassFlowRate 1;
BA_ "SPN" SG_ 2364541694 EngExhstGsRcrcltion2MassFlowRate 5257;
BA_ "SigType" SG_ 2364541694 EngIntakeAirMassFlowRate 1;
BA_ "SPN" SG_ 2364541694 EngIntakeAirMassFlowRate 132;
BA_ "SigType" SG_ 2364541694 EngExhstGsRcrcltion1MassFlowRate 1;
BA_ "SPN" SG_ 2364541694 EngExhstGsRcrcltion1MassFlowRate 2659;
BA_ "SigType" SG_ 2566810366 FuelPumpPrimerStatus 5;
BA_ "SPN" SG_ 2566810366 FuelPumpPrimerStatus 4083;
BA_ "SPN" SG_ 2566810366 EngVentilationStatus 3554;
BA_ "SigType" SG_ 2566810366 EngCoolantPreheatedState 5;
BA_ "SPN" SG_ 2566810366 EngCoolantPreheatedState 3553;
BA_ "SigType" SG_ 2566810366 EngOilPreHeatedState 5;
BA_ "SPN" SG_ 2566810366 EngOilPreHeatedState 3552;
BA_ "SigType" SG_ 2566810366 EngOilPrimingState 5;
BA_ "SPN" SG_ 2566810366 EngOilPrimingState 3551;
BA_ "SigType" SG_ 2566810366 EngOilPrimingPumpSwitch 4;
BA_ "SPN" SG_ 2566810366 EngOilPrimingPumpSwitch 3550;
BA_ "SigType" SG_ 2566810366 EngOilFilterOutletPress 1;
BA_ "SPN" SG_ 2566810366 EngOilFilterOutletPress 3549;
BA_ "SigType" SG_ 2566810366 EngWasteOilReservoirLevel 1;
BA_ "SPN" SG_ 2566810366 EngWasteOilReservoirLevel 3548;
BA_ "SigType" SG_ 2566810366 EngFuelFilterDiffPress 1;
BA_ "SPN" SG_ 2566810366 EngFuelFilterDiffPress 1382;
BA_ "SigType" SG_ 2566810366 EngFuelSupplyPumpIntakePress 1;
BA_ "SPN" SG_ 2566810366 EngFuelSupplyPumpIntakePress 1381;
BA_ "SigType" SG_ 2566810366 EngOilLevelRemoteReservoir 1;
BA_ "SPN" SG_ 2566810366 EngOilLevelRemoteReservoir 1380;
BA_ "SigType" SG_ 2566767102 EngThrottleValve1DiffPress 1;
BA_ "SPN" SG_ 2566767102 EngThrottleValve1DiffPress 5631;
BA_ "SigType" SG_ 2566767102 EngExhstGsRcrclation1OutletPress 1;
BA_ "SPN" SG_ 2566767102 EngExhstGsRcrclation1OutletPress 5019;
BA_ "SigType" SG_ 2566767102 EngExhstVlvActtionSystemOilPress 1;
BA_ "SPN" SG_ 2566767102 EngExhstVlvActtionSystemOilPress 4287;
BA_ "SigType" SG_ 2566767102 EngExhstGsRcrclation1IntakePress 1;
BA_ "SPN" SG_ 2566767102 EngExhstGsRcrclation1IntakePress 3358;
BA_ "SigType" SG_ 2566767102 EngIntkVlvActationSystemOilPress 1;
BA_ "SPN" SG_ 2566767102 EngIntkVlvActationSystemOilPress 2948;
BA_ "SigType" SG_ 2566839294 EngInjectorMeteringRail2Press 1;
BA_ "SPN" SG_ 2566839294 EngInjectorMeteringRail2Press 1349;
BA_ "SigType" SG_ 2566839294 EngInjectorTimingRail1Press 1;
BA_ "SPN" SG_ 2566839294 EngInjectorTimingRail1Press 156;
BA_ "SigType" SG_ 2566839294 EngInjectorMeteringRail1Press 1;
BA_ "SPN" SG_ 2566839294 EngInjectorMeteringRail1Press 157;
BA_ "SigType" SG_ 2566839294 EngInjectionCtrlPress 1;
BA_ "SPN" SG_ 2566839294 EngInjectionCtrlPress 164;
BA_ "SigType" SG_ 2566844414 EngCoolantLevel 1;
BA_ "SPN" SG_ 2566844414 EngCoolantLevel 111;
BA_ "SigType" SG_ 2566844414 EngCoolantPress 1;
BA_ "SPN" SG_ 2566844414 EngCoolantPress 109;
BA_ "SigType" SG_ 2566844414 EngCrankcasePress 1;
BA_ "SPN" SG_ 2566844414 EngCrankcasePress 101;
BA_ "SigType" SG_ 2566844414 EngOilPress 1;
BA_ "SPN" SG_ 2566844414 EngOilPress 100;
BA_ "SigType" SG_ 2566844414 EngOilLevel 1;
BA_ "SPN" SG_ 2566844414 EngOilLevel 98;
BA_ "SigType" SG_ 2566844414 EngExCrankcaseBlowbyPress 1;
BA_ "SPN" SG_ 2566844414 EngExCrankcaseBlowbyPress 22;
BA_ "SigType" SG_ 2566844414 EngFuelDeliveryPress 1;
BA_ "SPN" SG_ 2566844414 EngFuelDeliveryPress 94;
BA_ "SigType" SG_ 2633929726 SafetyWireStatus 5;
BA_ "SPN" SG_ 2633929726 SafetyWireStatus 1205;
BA_ "SigType" SG_ 2633929726 ElectricalLoad 1;
BA_ "SPN" SG_ 2633929726 ElectricalLoad 1204;
BA_ "SigType" SG_ 2566772222 EngVrblGeometryTurbo1ActuatorPos 1;
BA_ "SPN" SG_ 2566772222 EngVrblGeometryTurbo1ActuatorPos 2795;
BA_ "SigType" SG_ 2566772222 EngVriableGeometryTurbo1CtrlMode 5;
BA_ "SPN" SG_ 2566772222 EngVriableGeometryTurbo1CtrlMode 5457;
BA_ "SigType" SG_ 2566772222 EngFuelCtrlCtrlMode 5;
BA_ "SPN" SG_ 2566772222 EngFuelCtrlCtrlMode 5323;
BA_ "SigType" SG_ 2566772222 EngVrblGmtryTrbArCtrlShtoffValve 5;
BA_ "SPN" SG_ 2566772222 EngVrblGmtryTrbArCtrlShtoffValve 2792;
BA_ "SPN" SG_ 2566772222 EngExhstGsRcirculation1ValveCtrl 2791;
BA_ "SPN" SG_ 2566772222 EngTrb1ClclatedTurbineOutletTemp 2790;
BA_ "SPN" SG_ 2566772222 EngTrb1ClclatedTurbineIntakeTemp 2789;
BA_ "SPN" SG_ 2633940734 CrnkAttmptCntOnPrsntStartAttempt 3671;
BA_ "SigType" SG_ 2633940734 EngIntakeManifoldPressCtrlMode 5;
BA_ "SPN" SG_ 2633940734 EngIntakeManifoldPressCtrlMode 5465;
BA_ "SigType" SG_ 2633940734 EngRotationDirection 4;
BA_ "SPN" SG_ 2633940734 EngRotationDirection 3669;
BA_ "SigType" SG_ 2633940734 EngRatedSpeed 1;
BA_ "SPN" SG_ 2633940734 EngRatedSpeed 189;
BA_ "SigType" SG_ 2633940734 EngRatedPower 1;
BA_ "SPN" SG_ 2633940734 EngRatedPower 166;
BA_ "SigType" SG_ 2566840318 Aftertreatment2ExhaustDewPoint 5;
BA_ "SPN" SG_ 2566840318 Aftertreatment2ExhaustDewPoint 3240;
BA_ "SigType" SG_ 2566840318 Aftertreatment2IntakeDewPoint 5;
BA_ "SPN" SG_ 2566840318 Aftertreatment2IntakeDewPoint 3239;
BA_ "SigType" SG_ 2566840318 Aftertreatment1ExhaustDewPoint 5;
BA_ "SPN" SG_ 2566840318 Aftertreatment1ExhaustDewPoint 3238;
BA_ "SigType" SG_ 2566840318 Aftertreatment1IntakeDewPoint 5;
BA_ "SPN" SG_ 2566840318 Aftertreatment1IntakeDewPoint 3237;
BA_ "SigType" SG_ 2566840318 Aftrtreatment1ExhaustGasMassFlow 1;
BA_ "SPN" SG_ 2566840318 Aftrtreatment1ExhaustGasMassFlow 3236;
BA_ "SPN" SG_ 2566840318 EstEngPrsiticLossesPercentTorque 2978;
BA_ "SPN" SG_ 2566840318 EngnsDsrdOprtngSpdAsymmtryAdjstm 519;
BA_ "SPN" SG_ 2566840318 EnginesDesiredOperatingSpeed 515;
BA_ "SPN" SG_ 2566840318 NominalFrictionPercentTorque 514;
BA_ "SigType" SG_ 2364539902 EstPumpingPercentTorque 1;
BA_ "SPN" SG_ 2364539902 EstPumpingPercentTorque 5398;
BA_ "SigType" SG_ 2364539902 ActlMaxAvailableEngPercentTorque 1;
BA_ "SPN" SG_ 2364539902 ActlMaxAvailableEngPercentTorque 3357;
BA_ "SigType" SG_ 2364539902 SCRThermalManagementActive 5;
BA_ "SPN" SG_ 2364539902 SCRThermalManagementActive 5400;
BA_ "SigType" SG_ 2364539902 DPFThermalManagementActive 5;
BA_ "SPN" SG_ 2364539902 DPFThermalManagementActive 5399;
BA_ "SigType" SG_ 2364539902 MmntaryEngMaxPowerEnableFeedback 5;
BA_ "SPN" SG_ 2364539902 MmntaryEngMaxPowerEnableFeedback 5021;
BA_ "SigType" SG_ 2364539902 VhcleAccelerationRateLimitStatus 5;
BA_ "SPN" SG_ 2364539902 VhcleAccelerationRateLimitStatus 2979;
BA_ "SigType" SG_ 2364539902 AccelPedalPos2 1;
BA_ "SPN" SG_ 2364539902 AccelPedalPos2 29;
BA_ "SigType" SG_ 2364539902 RemoteAccelPedalPos 1;
BA_ "SPN" SG_ 2364539902 RemoteAccelPedalPos 974;
BA_ "SPN" SG_ 2364539902 EngPercentLoadAtCurrentSpeed 92;
BA_ "SigType" SG_ 2364539902 AccelPedalPos1 1;
BA_ "SPN" SG_ 2364539902 AccelPedalPos1 91;
BA_ "SigType" SG_ 2364539902 AccelPedal2LowIdleSwitch 4;
BA_ "SPN" SG_ 2364539902 AccelPedal2LowIdleSwitch 2970;
BA_ "SigType" SG_ 2364539902 RoadSpeedLimitStatus 5;
BA_ "SPN" SG_ 2364539902 RoadSpeedLimitStatus 1437;
BA_ "SigType" SG_ 2364539902 AccelPedalKickdownSwitch 4;
BA_ "SPN" SG_ 2364539902 AccelPedalKickdownSwitch 559;
BA_ "SigType" SG_ 2364539902 AccelPedal1LowIdleSwitch 4;
BA_ "SPN" SG_ 2364539902 AccelPedal1LowIdleSwitch 558;
BA_ "SigType" SG_ 2364540158 EngDemandPercentTorque 1;
BA_ "SPN" SG_ 2364540158 EngDemandPercentTorque 2432;
BA_ "SPN" SG_ 2364540158 EngStarterMode 1675;
BA_ "SPN" SG_ 2364540158 SrcAddrssOfCntrllngDvcForEngCtrl 1483;
BA_ "SigType" SG_ 2364540158 EngSpeed 1;
BA_ "SPN" SG_ 2364540158 EngSpeed 190;
BA_ "SigType" SG_ 2364540158 ActualEngPercentTorque 1;
BA_ "SPN" SG_ 2364540158 ActualEngPercentTorque 513;
BA_ "SigType" SG_ 2364540158 DriversDemandEngPercentTorque 1;
BA_ "SPN" SG_ 2364540158 DriversDemandEngPercentTorque 512;
BA_ "SPN" SG_ 2364540158 ActlEngPrcntTorqueHighResolution 4154;
BA_ "SPN" SG_ 2364540158 EngTorqueMode 899;
BA_ "SigType" SG_ 2566768126 ECUType 8;
BA_ "SPN" SG_ 2566768126 ECUType 2904;
BA_ "SigType" SG_ 2566768126 ECULocation 8;
BA_ "SPN" SG_ 2566768126 ECULocation 2903;
BA_ "SigType" SG_ 2566768126 ECUSerialNumber 8;
BA_ "SPN" SG_ 2566768126 ECUSerialNumber 2902;
BA_ "SigType" SG_ 2566768126 ECUPartNumber 8;
BA_ "SPN" SG_ 2566768126 ECUPartNumber 2901;
BA_ "SPN" SG_ 2566804734 EngMinContinuousTorque 1775;
BA_ "SPN" SG_ 2566804734 EngMaxContinuousTorque 1774;
BA_ "SPN" SG_ 2566804734 EngMinContinuousRPM 1773;
BA_ "SPN" SG_ 2566804734 EngMaxContinuousRPM 1772;
BA_ "SPN" SG_ 2566804734 EngHghLmtThrshldFrMnCntnsTrqFrmE 1771;
BA_ "SPN" SG_ 2566804734 EngLwLmtThrshldFrMxTorqueFromEng 1770;
BA_ "SPN" SG_ 2566804734 EngHghLmtThrshldFrMnCntnusEngRPM 1769;
BA_ "SPN" SG_ 2566804734 EngLwLmtThrsholdForMaxRPMFromEng 1768;
BA_ "SPN" SG_ 2566841342 SupportTSC1CtrlPurposeGroup4 3348;
BA_ "SPN" SG_ 2566841342 SupportTSC1CtrlPurposeGroup3 3347;
BA_ "SPN" SG_ 2566841342 SupportTSC1CtrlPurposeGroup2 3346;
BA_ "SPN" SG_ 2566841342 SupportTSC1CtrlPurposeGroup1 3345;
BA_ "SPN" SG_ 2566841342 SupportVariableRateTSC1Message 3344;
BA_ "SigType" SG_ 2566841342 EngDefaultTorqueLimit 1;
BA_ "SPN" SG_ 2566841342 EngDefaultTorqueLimit 1846;
BA_ "SPN" SG_ 2566841342 EngMomentOfInertia 1794;
BA_ "SigType" SG_ 2566841342 EngExRngRqstdSpdCtrlRngUpprLimit 1;
BA_ "SPN" SG_ 2566841342 EngExRngRqstdSpdCtrlRngUpprLimit 1712;
BA_ "SigType" SG_ 2566841342 EngRqstdTrqueCtrlRangeUpperLimit 1;
BA_ "SPN" SG_ 2566841342 EngRqstdTrqueCtrlRangeUpperLimit 538;
BA_ "SigType" SG_ 2566841342 EngRqstdTrqueCtrlRangeLowerLimit 1;
BA_ "SPN" SG_ 2566841342 EngRqstdTrqueCtrlRangeLowerLimit 537;
BA_ "SigType" SG_ 2566841342 EngRqstdSpeedCtrlRangeUpperLimit 1;
BA_ "SPN" SG_ 2566841342 EngRqstdSpeedCtrlRangeUpperLimit 536;
BA_ "SigType" SG_ 2566841342 EngRqstdSpeedCtrlRangeLowerLimit 1;
BA_ "SPN" SG_ 2566841342 EngRqstdSpeedCtrlRangeLowerLimit 535;
BA_ "SigType" SG_ 2566841342 EngMaxMomentaryOverrideTimeLimit 1;
BA_ "SPN" SG_ 2566841342 EngMaxMomentaryOverrideTimeLimit 534;
BA_ "SigType" SG_ 2566841342 EngMxMmentaryOverrideSpeedPoint7 1;
BA_ "SPN" SG_ 2566841342 EngMxMmentaryOverrideSpeedPoint7 533;
BA_ "SigType" SG_ 2566841342 EngReferenceTorque 1;
BA_ "SPN" SG_ 2566841342 EngReferenceTorque 544;
BA_ "SigType" SG_ 2566841342 EngGain 1;
BA_ "SPN" SG_ 2566841342 EngGain 545;
BA_ "SigType" SG_ 2566841342 EngSpeedAtHighIdlePoint6 1;
BA_ "SPN" SG_ 2566841342 EngSpeedAtHighIdlePoint6 532;
BA_ "SigType" SG_ 2566841342 EngPercentTorqueAtPoint5 1;
BA_ "SPN" SG_ 2566841342 EngPercentTorqueAtPoint5 543;
BA_ "SigType" SG_ 2566841342 EngSpeedAtPoint5 1;
BA_ "SPN" SG_ 2566841342 EngSpeedAtPoint5 531;
BA_ "SigType" SG_ 2566841342 EngPercentTorqueAtPoint4 1;
BA_ "SPN" SG_ 2566841342 EngPercentTorqueAtPoint4 542;
BA_ "SigType" SG_ 2566841342 EngSpeedAtPoint4 1;
BA_ "SPN" SG_ 2566841342 EngSpeedAtPoint4 530;
BA_ "SigType" SG_ 2566841342 EngPercentTorqueAtPoint3 1;
BA_ "SPN" SG_ 2566841342 EngPercentTorqueAtPoint3 541;
BA_ "SigType" SG_ 2566841342 EngSpeedAtPoint3 1;
BA_ "SPN" SG_ 2566841342 EngSpeedAtPoint3 529;
BA_ "SigType" SG_ 2566841342 EngPercentTorqueAtPoint2 1;
BA_ "SPN" SG_ 2566841342 EngPercentTorqueAtPoint2 540;
BA_ "SigType" SG_ 2566841342 EngSpeedAtPoint2 1;
BA_ "SPN" SG_ 2566841342 EngSpeedAtPoint2 528;
BA_ "SigType" SG_ 2566841342 EngPercentTorqueAtIdlePoint1 1;
BA_ "SPN" SG_ 2566841342 EngPercentTorqueAtIdlePoint1 539;
BA_ "SigType" SG_ 2566841342 EngSpeedAtIdlePoint1 1;
BA_ "SPN" SG_ 2566841342 EngSpeedAtIdlePoint1 188;
BA_ "SigType" SG_ 2566767870 EmergencyBrakingActive 5;
BA_ "SPN" SG_ 2566767870 EmergencyBrakingActive 5847;
BA_ "SigType" SG_ 2566767870 PrkngBrakeActuatorFullyActivated 4;
BA_ "SPN" SG_ 2566767870 PrkngBrakeActuatorFullyActivated 5275;
BA_ "SPN" SG_ 2566767870 XBRAccelerationLimit 2921;
BA_ "SPN" SG_ 2566767870 XBRActiveCtrlMode 2918;
BA_ "SigType" SG_ 2566767870 XBRSystemState 5;
BA_ "SPN" SG_ 2566767870 XBRSystemState 2917;
BA_ "SigType" SG_ 2566767870 FoundationBrakeUse 5;
BA_ "SPN" SG_ 2566767870 FoundationBrakeUse 2919;
BA_ "SPN" SG_ 2566767870 HillHolderMode 2912;
BA_ "SPN" SG_ 2566767870 HaltBrakeMode 2913;
BA_ "SigType" SG_ 2566767870 BrakeTempWarning 5;
BA_ "SPN" SG_ 2566767870 BrakeTempWarning 3839;
BA_ "SigType" SG_ 2633936126 BrkLnngRmningRearAxle3RightWheel 1;
BA_ "SPN" SG_ 2633936126 BrkLnngRmningRearAxle3RightWheel 1106;
BA_ "SigType" SG_ 2633936126 BrkLnngRminingRearAxle3LeftWheel 1;
BA_ "SPN" SG_ 2633936126 BrkLnngRminingRearAxle3LeftWheel 1105;
BA_ "SigType" SG_ 2633936126 BrkLnngRmningRearAxle2RightWheel 1;
BA_ "SPN" SG_ 2633936126 BrkLnngRmningRearAxle2RightWheel 1104;
BA_ "SigType" SG_ 2633936126 BrkLnngRminingRearAxle2LeftWheel 1;
BA_ "SPN" SG_ 2633936126 BrkLnngRminingRearAxle2LeftWheel 1103;
BA_ "SigType" SG_ 2633936126 BrkLnngRmningRearAxle1RightWheel 1;
BA_ "SPN" SG_ 2633936126 BrkLnngRmningRearAxle1RightWheel 1102;
BA_ "SigType" SG_ 2633936126 BrkLnngRminingRearAxle1LeftWheel 1;
BA_ "SPN" SG_ 2633936126 BrkLnngRminingRearAxle1LeftWheel 1101;
BA_ "SigType" SG_ 2633936126 BrkLnngRmningFrontAxleRightWheel 1;
BA_ "SPN" SG_ 2633936126 BrkLnngRmningFrontAxleRightWheel 1100;
BA_ "SigType" SG_ 2633936126 BrkLnngRminingFrontAxleLeftWheel 1;
BA_ "SPN" SG_ 2633936126 BrkLnngRminingFrontAxleLeftWheel 1099;
BA_ "SigType" SG_ 2566827518 BrkAppPrssHghRngRrAxl3RightWheel 1;
BA_ "SPN" SG_ 2566827518 BrkAppPrssHghRngRrAxl3RightWheel 1098;
BA_ "SigType" SG_ 2566827518 BrkAppPrssHghRngRrAxle3LeftWheel 1;
BA_ "SPN" SG_ 2566827518 BrkAppPrssHghRngRrAxle3LeftWheel 1097;
BA_ "SigType" SG_ 2566827518 BrkAppPrssHghRngRrAxl2RightWheel 1;
BA_ "SPN" SG_ 2566827518 BrkAppPrssHghRngRrAxl2RightWheel 1096;
BA_ "SigType" SG_ 2566827518 BrkAppPrssHghRngRrAxle2LeftWheel 1;
BA_ "SPN" SG_ 2566827518 BrkAppPrssHghRngRrAxle2LeftWheel 1095;
BA_ "SigType" SG_ 2566827518 BrkAppPrssHghRngRrAxle1LeftWheel 1;
BA_ "SPN" SG_ 2566827518 BrkAppPrssHghRngRrAxle1LeftWheel 1093;
BA_ "SigType" SG_ 2566827518 BrkAppPrssHghRngFrntAxlRghtWheel 1;
BA_ "SPN" SG_ 2566827518 BrkAppPrssHghRngFrntAxlRghtWheel 1092;
BA_ "SigType" SG_ 2566827518 BrkAppPrssHghRngFrntAxlLeftWheel 1;
BA_ "SPN" SG_ 2566827518 BrkAppPrssHghRngFrntAxlLeftWheel 1091;
BA_ "SigType" SG_ 2566827518 BrkAppPrssHghRngRrAxl1RightWheel 1;
BA_ "SPN" SG_ 2566827518 BrkAppPrssHghRngRrAxl1RightWheel 1094;
BA_ "SigType" SG_ 2566832126 RelativeSpeedRearAxle2RightWheel 1;
BA_ "SPN" SG_ 2566832126 RelativeSpeedRearAxle2RightWheel 910;
BA_ "SigType" SG_ 2566832126 RelativeSpeedRearAxle2LeftWheel 1;
BA_ "SPN" SG_ 2566832126 RelativeSpeedRearAxle2LeftWheel 909;
BA_ "SigType" SG_ 2566832126 RelativeSpeedRearAxle1RightWheel 1;
BA_ "SPN" SG_ 2566832126 RelativeSpeedRearAxle1RightWheel 908;
BA_ "SigType" SG_ 2566832126 RelativeSpeedRearAxle1LeftWheel 1;
BA_ "SPN" SG_ 2566832126 RelativeSpeedRearAxle1LeftWheel 907;
BA_ "SigType" SG_ 2566832126 RelativeSpeedFrontAxleRightWheel 1;
BA_ "SPN" SG_ 2566832126 RelativeSpeedFrontAxleRightWheel 906;
BA_ "SigType" SG_ 2566832126 RelativeSpeedFrontAxleLeftWheel 1;
BA_ "SPN" SG_ 2566832126 RelativeSpeedFrontAxleLeftWheel 905;
BA_ "SigType" SG_ 2566832126 FrontAxleSpeed 1;
BA_ "SPN" SG_ 2566832126 FrontAxleSpeed 904;
BA_ "SigType" SG_ 2565865982 TrctrMntdTrailerABSWarningSignal 5;
BA_ "SPN" SG_ 2565865982 TrctrMntdTrailerABSWarningSignal 1792;
BA_ "SigType" SG_ 2565865982 TrailerABSStatus 5;
BA_ "SPN" SG_ 2565865982 TrailerABSStatus 1836;
BA_ "SigType" SG_ 2565865982 HaltBrakeSwitch 4;
BA_ "SPN" SG_ 2565865982 HaltBrakeSwitch 2911;
BA_ "SPN" SG_ 2565865982 SrcAddrssOfCntrllngDvcFrBrkeCtrl 1481;
BA_ "SigType" SG_ 2565865982 ATC_ASRInformationSignal 5;
BA_ "SPN" SG_ 2565865982 ATC_ASRInformationSignal 1793;
BA_ "SigType" SG_ 2565865982 ABS_EBSAmberWarningSignal 5;
BA_ "SPN" SG_ 2565865982 ABS_EBSAmberWarningSignal 1438;
BA_ "SigType" SG_ 2565865982 EBSRedWarningSignal 5;
BA_ "SPN" SG_ 2565865982 EBSRedWarningSignal 1439;
BA_ "SigType" SG_ 2565865982 ABSFullyOperational 5;
BA_ "SPN" SG_ 2565865982 ABSFullyOperational 1243;
BA_ "SigType" SG_ 2565865982 EngRetarderSelection 1;
BA_ "SPN" SG_ 2565865982 EngRetarderSelection 973;
BA_ "SigType" SG_ 2565865982 RemoteAccelEnableSwitch 4;
BA_ "SPN" SG_ 2565865982 RemoteAccelEnableSwitch 969;
BA_ "SigType" SG_ 2565865982 EngAuxShutdownSwitch 4;
BA_ "SPN" SG_ 2565865982 EngAuxShutdownSwitch 970;
BA_ "SigType" SG_ 2565865982 EngDerateSwitch 4;
BA_ "SPN" SG_ 2565865982 EngDerateSwitch 971;
BA_ "SigType" SG_ 2565865982 AccelInterlockSwitch 4;
BA_ "SPN" SG_ 2565865982 AccelInterlockSwitch 972;
BA_ "SigType" SG_ 2565865982 TractionCtrlOverrideSwitch 4;
BA_ "SPN" SG_ 2565865982 TractionCtrlOverrideSwitch 1238;
BA_ "SigType" SG_ 2565865982 ASRHillHolderSwitch 4;
BA_ "SPN" SG_ 2565865982 ASRHillHolderSwitch 577;
BA_ "SigType" SG_ 2565865982 ASROffroadSwitch 4;
BA_ "SPN" SG_ 2565865982 ASROffroadSwitch 576;
BA_ "SigType" SG_ 2565865982 ABSOffroadSwitch 4;
BA_ "SPN" SG_ 2565865982 ABSOffroadSwitch 575;
BA_ "SigType" SG_ 2565865982 BrakePedalPos 1;
BA_ "SPN" SG_ 2565865982 BrakePedalPos 521;
BA_ "SigType" SG_ 2565865982 EBSBrakeSwitch 4;
BA_ "SPN" SG_ 2565865982 EBSBrakeSwitch 1121;
BA_ "SigType" SG_ 2565865982 AntiLockBrakingActive 5;
BA_ "SPN" SG_ 2565865982 AntiLockBrakingActive 563;
BA_ "SigType" SG_ 2565865982 ASRBrakeCtrlActive 5;
BA_ "SPN" SG_ 2565865982 ASRBrakeCtrlActive 562;
BA_ "SigType" SG_ 2565865982 ASREngCtrlActive 5;
BA_ "SPN" SG_ 2565865982 ASREngCtrlActive 561;
BA_ "SigType" SG_ 2565867262 RearAxleGroupEngagementStatus 5;
BA_ "SPN" SG_ 2565867262 RearAxleGroupEngagementStatus 3820;
BA_ "SigType" SG_ 2565867262 FrontAxleGroupEngagementStatus 5;
BA_ "SPN" SG_ 2565867262 FrontAxleGroupEngagementStatus 3819;
BA_ "SigType" SG_ 2565867262 DiffLockStateCentralRear 5;
BA_ "SPN" SG_ 2565867262 DiffLockStateCentralRear 566;
BA_ "SigType" SG_ 2565867262 DiffLockStateCentralFront 5;
BA_ "SPN" SG_ 2565867262 DiffLockStateCentralFront 565;
BA_ "SigType" SG_ 2565867262 DiffLockStateCentral 5;
BA_ "SPN" SG_ 2565867262 DiffLockStateCentral 564;
BA_ "SigType" SG_ 2565867262 DiffLockStateRearAxle2 5;
BA_ "SPN" SG_ 2565867262 DiffLockStateRearAxle2 570;
BA_ "SigType" SG_ 2565867262 DiffLockStateRearAxle1 5;
BA_ "SPN" SG_ 2565867262 DiffLockStateRearAxle1 569;
BA_ "SigType" SG_ 2565867262 DiffLockStateFrontAxle2 5;
BA_ "SPN" SG_ 2565867262 DiffLockStateFrontAxle2 568;
BA_ "SigType" SG_ 2565867262 DiffLockStateFrontAxle1 5;
BA_ "SPN" SG_ 2565867262 DiffLockStateFrontAxle1 567;
BA_ "SPN" SG_ 2565867262 Location 927;
BA_ "SigType" SG_ 2566821118 EngExRangeCoolantPress 1;
BA_ "SPN" SG_ 2566821118 EngExRangeCoolantPress 20;
BA_ "SigType" SG_ 2566821118 SeaWaterPumpOutletPress 1;
BA_ "SPN" SG_ 2566821118 SeaWaterPumpOutletPress 2435;
BA_ "SigType" SG_ 2566821118 EngAuxCoolantTemp 1;
BA_ "SPN" SG_ 2566821118 EngAuxCoolantTemp 1212;
BA_ "SigType" SG_ 2566821118 EngAuxCoolantPress 1;
BA_ "SPN" SG_ 2566821118 EngAuxCoolantPress 1203;
BA_ "SigType" SG_ 2566810622 Driver2Identification 8;
BA_ "SPN" SG_ 2566810622 Driver2Identification 1626;
BA_ "SigType" SG_ 2566810622 Driver1Identification 8;
BA_ "SPN" SG_ 2566810622 Driver1Identification 1625;
BA_ "SigType" SG_ 2566847742 FuelLevel2 1;
BA_ "SPN" SG_ 2566847742 FuelLevel2 38;
BA_ "SigType" SG_ 2566847742 CargoAmbientTemp 1;
BA_ "SPN" SG_ 2566847742 CargoAmbientTemp 169;
BA_ "SigType" SG_ 2566847742 EngOilFilterDiffPress 1;
BA_ "SPN" SG_ 2566847742 EngOilFilterDiffPress 99;
BA_ "SigType" SG_ 2566847742 EngFuelFilterDiffPress 1;
BA_ "SPN" SG_ 2566847742 EngFuelFilterDiffPress 95;
BA_ "SigType" SG_ 2566847742 FuelLevel1 1;
BA_ "SPN" SG_ 2566847742 FuelLevel1 96;
BA_ "SigType" SG_ 2566847742 WasherFluidLevel 1;
BA_ "SPN" SG_ 2566847742 WasherFluidLevel 80;
BA_ "SigType" SG_ 2566768382 EngCldStrtFlIgniterRelayFeedback 4;
BA_ "SPN" SG_ 2566768382 EngCldStrtFlIgniterRelayFeedback 5550;
BA_ "SigType" SG_ 2566768382 EngColdStartFuelIgniterRelay 5;
BA_ "SPN" SG_ 2566768382 EngColdStartFuelIgniterRelay 5549;
BA_ "SPN" SG_ 2566768382 EngColdStartFuelIgniterCmd 5548;
BA_ "SPN" SG_ 2566768382 EngStartEnableDevice2Config 2898;
BA_ "SPN" SG_ 2566768382 EngStartEnableDevice1Config 2899;
BA_ "SigType" SG_ 2566768382 EngStartEnableDevice2 5;
BA_ "SPN" SG_ 2566768382 EngStartEnableDevice2 1804;
BA_ "SigType" SG_ 2566768382 EngStartEnableDevice1 5;
BA_ "SPN" SG_ 2566768382 EngStartEnableDevice1 626;
BA_ "SigType" SG_ 2566811902 PoweredVehicleWeight 1;
BA_ "SPN" SG_ 2566811902 PoweredVehicleWeight 1585;
BA_ "SigType" SG_ 2566811902 GrossCombinationVehicleWeight 1;
BA_ "SPN" SG_ 2566811902 GrossCombinationVehicleWeight 1760;
BA_ "SPN" SG_ 2563768062 MxCntinuousRetarderTorqueLimitRq 1791;
BA_ "SPN" SG_ 2563768062 MnCntinuousRetarderTorqueLimitRq 1790;
BA_ "SPN" SG_ 2563768062 MxContinuousRetarderSpeedLimitRq 1789;
BA_ "SPN" SG_ 2563768062 MnContinuousRetarderSpeedLimitRq 1788;
BA_ "SPN" SG_ 2563768062 EngTorqueLimitRqMaxContinuous 1787;
BA_ "SPN" SG_ 2563768062 EngTorqueLimitRqMinContinuous 1786;
BA_ "SPN" SG_ 2563768062 EngSpeedLimitRqMaxContinuous 1785;
BA_ "SPN" SG_ 2563768062 EngSpeedLimitRqMinContinuous 1784;
BA_ "SigType" SG_ 2633924862 EngAverageCombustionTime 1;
BA_ "SPN" SG_ 2633924862 EngAverageCombustionTime 1465;
BA_ "SigType" SG_ 2633924862 EngDesiredCombustionTime 1;
BA_ "SPN" SG_ 2633924862 EngDesiredCombustionTime 1464;
BA_ "SigType" SG_ 2633924606 EngCyl20CombustionTime 1;
BA_ "SPN" SG_ 2633924606 EngCyl20CombustionTime 1463;
BA_ "SigType" SG_ 2633924606 EngCyl19CombustionTime 1;
BA_ "SPN" SG_ 2633924606 EngCyl19CombustionTime 1462;
BA_ "SigType" SG_ 2633924606 EngCyl18CombustionTime 1;
BA_ "SPN" SG_ 2633924606 EngCyl18CombustionTime 1461;
BA_ "SigType" SG_ 2633924606 EngCyl17CombustionTime 1;
BA_ "SPN" SG_ 2633924606 EngCyl17CombustionTime 1460;
BA_ "SigType" SG_ 2633924350 EngCyl16CombustionTime 1;
BA_ "SPN" SG_ 2633924350 EngCyl16CombustionTime 1459;
BA_ "SigType" SG_ 2633924350 EngCyl15CombustionTime 1;
BA_ "SPN" SG_ 2633924350 EngCyl15CombustionTime 1458;
BA_ "SigType" SG_ 2633924350 EngCyl14CombustionTime 1;
BA_ "SPN" SG_ 2633924350 EngCyl14CombustionTime 1457;
BA_ "SigType" SG_ 2633924350 EngCyl13CombustionTime 1;
BA_ "SPN" SG_ 2633924350 EngCyl13CombustionTime 1456;
BA_ "SigType" SG_ 2633924094 EngCyl12CombustionTime 1;
BA_ "SPN" SG_ 2633924094 EngCyl12CombustionTime 1455;
BA_ "SigType" SG_ 2633924094 EngCyl11CombustionTime 1;
BA_ "SPN" SG_ 2633924094 EngCyl11CombustionTime 1454;
BA_ "SigType" SG_ 2633924094 EngCyl10CombustionTime 1;
BA_ "SPN" SG_ 2633924094 EngCyl10CombustionTime 1453;
BA_ "SigType" SG_ 2633924094 EngCyl9CombustionTime 1;
BA_ "SPN" SG_ 2633924094 EngCyl9CombustionTime 1452;
BA_ "SigType" SG_ 2633923838 EngCyl8CombustionTime 1;
BA_ "SPN" SG_ 2633923838 EngCyl8CombustionTime 1451;
BA_ "SigType" SG_ 2633923838 EngCyl7CombustionTime 1;
BA_ "SPN" SG_ 2633923838 EngCyl7CombustionTime 1450;
BA_ "SigType" SG_ 2633923838 EngCyl6CombustionTime 1;
BA_ "SPN" SG_ 2633923838 EngCyl6CombustionTime 1449;
BA_ "SigType" SG_ 2633923838 EngCyl5CombustionTime 1;
BA_ "SPN" SG_ 2633923838 EngCyl5CombustionTime 1448;
BA_ "SigType" SG_ 2633923582 EngCyl4CombustionTime 1;
BA_ "SPN" SG_ 2633923582 EngCyl4CombustionTime 1447;
BA_ "SigType" SG_ 2633923582 EngCyl3CombustionTime 1;
BA_ "SPN" SG_ 2633923582 EngCyl3CombustionTime 1446;
BA_ "SigType" SG_ 2633923582 EngCyl2CombustionTime 1;
BA_ "SPN" SG_ 2633923582 EngCyl2CombustionTime 1445;
BA_ "SigType" SG_ 2633923582 EngCyl1CombustionTime 1;
BA_ "SPN" SG_ 2633923582 EngCyl1CombustionTime 1444;
BA_ "SigType" SG_ 2633878014 TotalCountOfConfigChangesMade 1;
BA_ "SPN" SG_ 2633878014 TotalCountOfConfigChangesMade 2887;
BA_ "SigType" SG_ 2566771966 TransOilLevelRq 5;
BA_ "SPN" SG_ 2566771966 TransOilLevelRq 3809;
BA_ "SigType" SG_ 2566771966 FifthWheelReleaseCtrl 4;
BA_ "SPN" SG_ 2566771966 FifthWheelReleaseCtrl 3314;
BA_ "SigType" SG_ 2566771966 FfthWhlRleaseCtrlSecurityLockout 4;
BA_ "SPN" SG_ 2566771966 FfthWhlRleaseCtrlSecurityLockout 3315;
BA_ "SPN" SG_ 2566771966 TransferCaseSelectorSwitch 2796;
BA_ "SPN" SG_ 2564882174 SelectedMaxVehicleSpeedLimit 2596;
BA_ "SigType" SG_ 2564882174 RqCabZoneHeating 5;
BA_ "SPN" SG_ 2564882174 RqCabZoneHeating 1686;
BA_ "SigType" SG_ 2564882174 RqEngZoneHeating 5;
BA_ "SPN" SG_ 2564882174 RqEngZoneHeating 1685;
BA_ "SPN" SG_ 2564882174 AuxHeaterModeRq 1683;
BA_ "SigType" SG_ 2564882174 EngAutomaticStartEnableSwitch 4;
BA_ "SPN" SG_ 2564882174 EngAutomaticStartEnableSwitch 1656;
BA_ "SigType" SG_ 2564882174 AtomaticGearShiftingEnableSwitch 4;
BA_ "SPN" SG_ 2564882174 AtomaticGearShiftingEnableSwitch 1666;
BA_ "SigType" SG_ 2564882174 DslPrtcltFltrRgnrtionForceSwitch 4;
BA_ "SPN" SG_ 2564882174 DslPrtcltFltrRgnrtionForceSwitch 3696;
BA_ "SigType" SG_ 2564882174 DslPrtcltFltrRgnrtnInhibitSwitch 4;
BA_ "SPN" SG_ 2564882174 DslPrtcltFltrRgnrtnInhibitSwitch 3695;
BA_ "SigType" SG_ 2564882174 VhclLmtngSpdGovernorEnableSwitch 4;
BA_ "SPN" SG_ 2564882174 VhclLmtngSpdGovernorEnableSwitch 1653;
BA_ "SigType" SG_ 2564882174 VhclLmtngSpdGvrnrIncrementSwitch 4;
BA_ "SPN" SG_ 2564882174 VhclLmtngSpdGvrnrIncrementSwitch 1654;
BA_ "SigType" SG_ 2564882174 VhclLmtngSpdGvrnrDecrementSwitch 4;
BA_ "SPN" SG_ 2564882174 VhclLmtngSpdGvrnrDecrementSwitch 1655;
BA_ "SigType" SG_ 2564882174 ParkBrakeCmd 5;
BA_ "SPN" SG_ 2564882174 ParkBrakeCmd 5630;
BA_ "SigType" SG_ 2564882174 SeatBeltSwitch 4;
BA_ "SPN" SG_ 2564882174 SeatBeltSwitch 1856;
BA_ "SigType" SG_ 2564882174 OperatorSeatDirectionSwitch 4;
BA_ "SPN" SG_ 2564882174 OperatorSeatDirectionSwitch 1714;
BA_ "SigType" SG_ 2564882174 BatteryMainSwitchHoldRq 5;
BA_ "SPN" SG_ 2564882174 BatteryMainSwitchHoldRq 1682;
BA_ "SigType" SG_ 2564882174 AuxHeaterCoolantPumpRq 5;
BA_ "SPN" SG_ 2564882174 AuxHeaterCoolantPumpRq 1684;
BA_ "SPN" SG_ 2564882174 CabInteriorTempCmd 1691;
BA_ "SPN" SG_ 2564882174 RequestedPercentFanSpeed 986;
BA_ "SPN" SG_ 2563833598 SwtchBcklghtIllmntnBrghtnssPrcnt 5532;
BA_ "SPN" SG_ 2563833598 IlluminationBrightnessPercent 1487;
BA_ "SigType" SG_ 2566843390 UnitNumber 8;
BA_ "SPN" SG_ 2566843390 UnitNumber 233;
BA_ "SigType" SG_ 2566843390 SerialNumber 8;
BA_ "SPN" SG_ 2566843390 SerialNumber 588;
BA_ "SigType" SG_ 2566843390 Model 8;
BA_ "SPN" SG_ 2566843390 Model 587;
BA_ "SigType" SG_ 2566843390 Make 8;
BA_ "SPN" SG_ 2566843390 Make 586;
BA_ "SigType" SG_ 2566844926 EngShutdownOverrideSwitch 4;
BA_ "SPN" SG_ 2566844926 EngShutdownOverrideSwitch 1237;
BA_ "SigType" SG_ 2566844926 EngTestModeSwitch 4;
BA_ "SPN" SG_ 2566844926 EngTestModeSwitch 966;
BA_ "SigType" SG_ 2566844926 EngIdleDecrementSwitch 4;
BA_ "SPN" SG_ 2566844926 EngIdleDecrementSwitch 967;
BA_ "SigType" SG_ 2566844926 EngIdleIncrementSwitch 4;
BA_ "SPN" SG_ 2566844926 EngIdleIncrementSwitch 968;
BA_ "SPN" SG_ 2566844926 CruiseCtrlStates 527;
BA_ "SPN" SG_ 2566844926 PTOGovernorState 976;
BA_ "SigType" SG_ 2566844926 CruiseCtrlSetSpeed 1;
BA_ "SPN" SG_ 2566844926 CruiseCtrlSetSpeed 86;
BA_ "SigType" SG_ 2566844926 CruiseCtrlAccelerateSwitch 4;
BA_ "SPN" SG_ 2566844926 CruiseCtrlAccelerateSwitch 602;
BA_ "SigType" SG_ 2566844926 CruiseCtrlResumeSwitch 4;
BA_ "SPN" SG_ 2566844926 CruiseCtrlResumeSwitch 601;
BA_ "SigType" SG_ 2566844926 CruiseCtrlCoastSwitch 4;
BA_ "SPN" SG_ 2566844926 CruiseCtrlCoastSwitch 600;
BA_ "SigType" SG_ 2566844926 CruiseCtrlSetSwitch 4;
BA_ "SPN" SG_ 2566844926 CruiseCtrlSetSwitch 599;
BA_ "SigType" SG_ 2566844926 ClutchSwitch 4;
BA_ "SPN" SG_ 2566844926 ClutchSwitch 598;
BA_ "SigType" SG_ 2566844926 BrakeSwitch 4;
BA_ "SPN" SG_ 2566844926 BrakeSwitch 597;
BA_ "SigType" SG_ 2566844926 CruiseCtrlEnableSwitch 4;
BA_ "SPN" SG_ 2566844926 CruiseCtrlEnableSwitch 596;
BA_ "SigType" SG_ 2566844926 CruiseCtrlActive 4;
BA_ "SPN" SG_ 2566844926 CruiseCtrlActive 595;
BA_ "SigType" SG_ 2566844926 WheelBasedVehicleSpeed 1;
BA_ "SPN" SG_ 2566844926 WheelBasedVehicleSpeed 84;
BA_ "SigType" SG_ 2566844926 ParkBrakeReleaseInhibitRq 5;
BA_ "SPN" SG_ 2566844926 ParkBrakeReleaseInhibitRq 3807;
BA_ "SigType" SG_ 2566844926 CruiseCtrlPauseSwitch 4;
BA_ "SPN" SG_ 2566844926 CruiseCtrlPauseSwitch 1633;
BA_ "SigType" SG_ 2566844926 ParkingBrakeSwitch 4;
BA_ "SPN" SG_ 2566844926 ParkingBrakeSwitch 70;
BA_ "SigType" SG_ 2566844926 TwoSpeedAxleSwitch 4;
BA_ "SPN" SG_ 2566844926 TwoSpeedAxleSwitch 69;
BA_ "SigType" SG_ 2566843902 CruiseCtrlLowSetLimitSpeed 1;
BA_ "SPN" SG_ 2566843902 CruiseCtrlLowSetLimitSpeed 88;
BA_ "SigType" SG_ 2566843902 CruiseCtrlHighSetLimitSpeed 1;
BA_ "SPN" SG_ 2566843902 CruiseCtrlHighSetLimitSpeed 87;
BA_ "SigType" SG_ 2566843902 MaxVehicleSpeedLimit 1;
BA_ "SPN" SG_ 2566843902 MaxVehicleSpeedLimit 74;
BA_ "SigType" SG_ 2566809598 AuxHeaterMaxOutputPower 1;
BA_ "SPN" SG_ 2566809598 AuxHeaterMaxOutputPower 1690;
BA_ "SigType" SG_ 2633940222 TripServiceBrakeApplications 1;
BA_ "SPN" SG_ 2633940222 TripServiceBrakeApplications 993;
BA_ "SigType" SG_ 2633940222 TripServiceBrakeDistance 1;
BA_ "SPN" SG_ 2633940222 TripServiceBrakeDistance 992;
BA_ "SigType" SG_ 2633940222 TripCompressionBrakeDistance 1;
BA_ "SPN" SG_ 2633940222 TripCompressionBrakeDistance 991;
BA_ "SigType" SG_ 2633940222 TotalCompressionBrakeDistance 1;
BA_ "SPN" SG_ 2633940222 TotalCompressionBrakeDistance 990;
BA_ "SigType" SG_ 2566775294 CbA_CRfrgrntCmpressorOutletPress 1;
BA_ "SPN" SG_ 2566775294 CbA_CRfrgrntCmpressorOutletPress 2609;
BA_ "SigType" SG_ 2566803710 Battery2Temp 1;
BA_ "SPN" SG_ 2566803710 Battery2Temp 1801;
BA_ "SigType" SG_ 2566803710 Battery1Temp 1;
BA_ "SPN" SG_ 2566803710 Battery1Temp 1800;
BA_ "SigType" SG_ 2566719486 EngFuelFilterRestrictedLampCmd 5;
BA_ "SPN" SG_ 2566719486 EngFuelFilterRestrictedLampCmd 5469;
BA_ "SigType" SG_ 2566719486 EngAirFilterRestrictionLampCmd 5;
BA_ "SPN" SG_ 2566719486 EngAirFilterRestrictionLampCmd 5086;
BA_ "SigType" SG_ 2566719486 EngIdleManagementActiveLampCmd 5;
BA_ "SPN" SG_ 2566719486 EngIdleManagementActiveLampCmd 5085;
BA_ "SigType" SG_ 2566719486 EngCoolantLevelLowLampCmd 5;
BA_ "SPN" SG_ 2566719486 EngCoolantLevelLowLampCmd 5084;
BA_ "SigType" SG_ 2566719486 EngCoolantTempHighLampCmd 5;
BA_ "SPN" SG_ 2566719486 EngCoolantTempHighLampCmd 5083;
BA_ "SigType" SG_ 2566719486 EngOilPressLowLampCmd 5;
BA_ "SPN" SG_ 2566719486 EngOilPressLowLampCmd 5082;
BA_ "SigType" SG_ 2566719486 CmprssnBrkEnblSwtchIndctrLampCmd 5;
BA_ "SPN" SG_ 2566719486 CmprssnBrkEnblSwtchIndctrLampCmd 3987;
BA_ "SigType" SG_ 2566719486 EngBrakeActiveLampCmd 5;
BA_ "SPN" SG_ 2566719486 EngBrakeActiveLampCmd 5081;
BA_ "SigType" SG_ 2566719486 OBDMalfunctionIndicatorLampCmd 5;
BA_ "SPN" SG_ 2566719486 OBDMalfunctionIndicatorLampCmd 5080;
BA_ "SigType" SG_ 2566719486 EngRedStopLampCmd 5;
BA_ "SPN" SG_ 2566719486 EngRedStopLampCmd 5079;
BA_ "SigType" SG_ 2566719486 EngAmberWarningLampCmd 5;
BA_ "SPN" SG_ 2566719486 EngAmberWarningLampCmd 5078;
BA_ "SigType" SG_ 2566719486 EngProtectLampCmd 5;
BA_ "SPN" SG_ 2566719486 EngProtectLampCmd 5077;
BA_ "SPN" SG_ 2633832702 RolloverSensorType 4934;
BA_ "SPN" SG_ 2633832702 RearCollisionSensor4Type 4933;
BA_ "SPN" SG_ 2633832702 RearCollisionSensor3Type 4932;
BA_ "SPN" SG_ 2633832702 RearCollisionSensor2Type 4931;
BA_ "SPN" SG_ 2633832702 RearCollisionSensor1Type 4930;
BA_ "SPN" SG_ 2633832702 SideCollisionSensorRearRightType 4929;
BA_ "SPN" SG_ 2633832702 SdCllisionSensorMidRearRightType 4928;
BA_ "SPN" SG_ 2633832702 SdCllsionSensorMidFrontRightType 4927;
BA_ "SPN" SG_ 2633832702 SdeCollisionSensorFrontRightType 4926;
BA_ "SPN" SG_ 2633832702 SideCollisionSensorRearLeftType 4925;
BA_ "SPN" SG_ 2633832702 SdCollisionSensorMidRearLeftType 4924;
BA_ "SPN" SG_ 2633832702 SdCllisionSensorMidFrontLeftType 4923;
BA_ "SPN" SG_ 2633832702 SideCollisionSensorFrontLeftType 4922;
BA_ "SPN" SG_ 2633832702 FrontalCollisionSensor4Type 4921;
BA_ "SPN" SG_ 2633832702 FrontalCollisionSensor3Type 4920;
BA_ "SPN" SG_ 2633832702 FrontalCollisionSensor2Type 4919;
BA_ "SPN" SG_ 2633832702 FrontalCollisionSensor1Type 4918;
BA_ "SPN" SG_ 2163223550 CrashChecksum 4975;
BA_ "SPN" SG_ 2163223550 CrashCounter 4974;
BA_ "SPN" SG_ 2163223550 CrashType 4973;
BA_ "SigType" SG_ 2566714878 EngChrgArClr2PrecoolerEfficiency 1;
BA_ "SPN" SG_ 2566714878 EngChrgArClr2PrecoolerEfficiency 5288;
BA_ "SigType" SG_ 2566714878 EngChrgArClr2PrecoolerOutletTemp 1;
BA_ "SPN" SG_ 2566714878 EngChrgArClr2PrecoolerOutletTemp 5287;
BA_ "SigType" SG_ 2566714878 EngChrgArClr2PrecoolerIntakeTemp 1;
BA_ "SPN" SG_ 2566714878 EngChrgArClr2PrecoolerIntakeTemp 5286;
BA_ "SigType" SG_ 2566714622 EngChargeAirCooler2Efficiency 1;
BA_ "SPN" SG_ 2566714622 EngChargeAirCooler2Efficiency 5292;
BA_ "SigType" SG_ 2566714622 EngChrgeAirCooler2AmbientAirTemp 1;
BA_ "SPN" SG_ 2566714622 EngChrgeAirCooler2AmbientAirTemp 5291;
BA_ "SigType" SG_ 2566714622 EngChargeAirCooler2OutletTemp 1;
BA_ "SPN" SG_ 2566714622 EngChargeAirCooler2OutletTemp 5290;
BA_ "SigType" SG_ 2566714622 EngChargeAirCooler2IntakeTemp 1;
BA_ "SPN" SG_ 2566714622 EngChargeAirCooler2IntakeTemp 5289;
BA_ "SigType" SG_ 2566715390 EngChrgArClr1PrecoolerEfficiency 1;
BA_ "SPN" SG_ 2566715390 EngChrgArClr1PrecoolerEfficiency 5282;
BA_ "SigType" SG_ 2566715390 EngChrgArClr1PrecoolerOutletTemp 1;
BA_ "SPN" SG_ 2566715390 EngChrgArClr1PrecoolerOutletTemp 5281;
BA_ "SigType" SG_ 2566715390 EngChrgArClr1PrecoolerIntakeTemp 1;
BA_ "SPN" SG_ 2566715390 EngChrgArClr1PrecoolerIntakeTemp 5280;
BA_ "SigType" SG_ 2566715134 EngChargeAirCooler1Efficiency 1;
BA_ "SPN" SG_ 2566715134 EngChargeAirCooler1Efficiency 5285;
BA_ "SigType" SG_ 2566715134 EngChrgeAirCooler1AmbientAirTemp 1;
BA_ "SPN" SG_ 2566715134 EngChrgeAirCooler1AmbientAirTemp 5284;
BA_ "SigType" SG_ 2566715134 EngChargeAirCooler1IntakeTemp 1;
BA_ "SPN" SG_ 2566715134 EngChargeAirCooler1IntakeTemp 5283;
VAL_ 2565865726 RetarderRoadSpeedExceededStatus 3 "Dont care/Take no action" 2 "Reserved" 1 "Road speed is above threshold and retarder is allowed to be activated" 0 "Road speed is below threshold" ;
VAL_ 2565865726 RetarderRoadSpeedLimitSwitch 3 "Not Available" 2 "Error Indicator" 1 "Road speed limiting by retarder is enabled The road speed that the retarder will limit will be determined when the" 0 "Road speed limiting by retarder is disabled" ;
VAL_ 2565865726 RetarderRequestingBrakeLight 3 "11  Not available/Take no action" 2 "10  Reserved" 1 "01  Retarder is requesting that the brake lights are illuminated" 0 "00  Retarder is not requesting that the brake lights are illuminated" ;
VAL_ 2565865726 EngCoolantLoadIncrease 3 "Not available" 2 "Error" 1 "Coolant load increase possible" 0 "No coolant load increase" ;
VAL_ 2565865726 RetarderEnableShiftAssistSwitch 3 "Not available" 2 "Error" 1 "Retarder  shift assist enabled" 0 "Retarder  shift assist disabled" ;
VAL_ 2565865726 RetarderEnableBrakeAssistSwitch 3 "Not available" 2 "Error" 1 "Retarder  brake assist enabled" 0 "Retarder  brake assist disabled" ;
VAL_ 2633935358 EngExhstGsOxygnSnsrClsdLpOprtion 3 "Dont Care/take no action" 2 "Reserved" 1 "Engine using the Exhaust Gas Oxygen sensor for a closed loop operation" 0 "Engine not using the Exhaust Gas Oxygen sensor open loop" ;
VAL_ 2365447166 Jystick3GripXAxisDetentPosStatus 3 "Not Available" 2 "Error Indicator" 1 "In the Detent Position" 0 "Not in the Detent Position" ;
VAL_ 2365447166 Jystick3GripYAxisDetentPosStatus 3 "Not Available" 2 "Error Indicator" 1 "In the Detent Position" 0 "Not in the Detent Position" ;
VAL_ 2365447166 Jystick3ThetaAxisDetentPosStatus 3 "Not Available" 2 "Error Indicator" 1 "In the Detent Position" 0 "Not in the Detent Position" ;
VAL_ 2365447166 Jystck3ThtAxsClckwsPstvPosStatus 3 "Not Available" 2 "Error Indicator" 1 "On positive side of Neutral" 0 "Not on Positive side of Neutral" ;
VAL_ 2365447166 Jystck3ThetaAxisNeutralPosStatus 3 "Not Available" 2 "Error Indicator" 1 "In Neutral Position" 0 "Not in Neutral Position" ;
VAL_ 2365447166 Jystck3GrpYAxsLvrFrwrdPstvPsStts 3 "Not Available" 2 "Error Indicator" 1 "On positive side of Neutral" 0 "Not on Positive side of Neutral" ;
VAL_ 2365447166 Jystck3GrpYAxsLvrBckNgtvPsStatus 3 "Not Available" 2 "Error Indicator" 1 "On negative side of Neutral" 0 "Not on negative side of Neutral" ;
VAL_ 2365447166 Jystck3GripYAxisNeutralPosStatus 3 "Not Available" 2 "Error Indicator" 1 "In Neutral Position" 0 "Not in Neutral Position" ;
VAL_ 2365447166 Jystck3GrpXAxsLvrRghtPstvPsSttus 3 "Not Available" 2 "Error Indicator" 1 "On positive side of Neutral" 0 "Not on Positive side of Neutral" ;
VAL_ 2365447166 Jystck3GrpXAxsLvrLftNgtvPsStatus 3 "Not Available" 2 "Error Indicator" 1 "On negative side of Neutral" 0 "Not on negative side of Neutral" ;
VAL_ 2365447166 Jystck3GripXAxisNeutralPosStatus 3 "Not Available" 2 "Error Indicator" 1 "On negative side of Neutral" 0 "Not on negative side of Neutral" ;
VAL_ 2365447166 Jystck3ThtAxsCntrClckwsNgtvPsStt 3 "Not Available" 2 "Error Indicator" 1 "On negative side of Neutral" 0 "Not on negative side of Neutral" ;
VAL_ 2365446654 Jystick2GripXAxisDetentPosStatus 3 "Not Available" 2 "Error Indicator" 1 "In the Detent Position" 0 "Not in the Detent Position" ;
VAL_ 2365446654 Jystick2GripYAxisDetentPosStatus 3 "Not Available" 2 "Error Indicator" 1 "In the Detent Position" 0 "Not in the Detent Position" ;
VAL_ 2365446654 Jystick2ThetaAxisDetentPosStatus 3 "Not Available" 2 "Error Indicator" 1 "In the Detent Position" 0 "Not in the Detent Position" ;
VAL_ 2365446654 Jystck2ThtAxsClckwsPstvPosStatus 3 "Not Available" 2 "Error Indicator" 1 "On positive side of Neutral" 0 "Not on Positive side of Neutral" ;
VAL_ 2365446654 Jystck2ThetaAxisNeutralPosStatus 3 "Not Available" 2 "Error Indicator" 1 "In Neutral Position" 0 "Not in Neutral Position" ;
VAL_ 2365446654 Jystck2GrpYAxsLvrFrwrdPstvPsStts 3 "Not Available" 2 "Error Indicator" 1 "On positive side of Neutral" 0 "Not on Positive side of Neutral" ;
VAL_ 2365446654 Jystck2GrpYAxsLvrBckNgtvPsStatus 3 "Not Available" 2 "Error Indicator" 1 "On negative side of Neutral" 0 "Not on negative side of Neutral" ;
VAL_ 2365446654 Jystck2GripYAxisNeutralPosStatus 3 "Not Available" 2 "Error Indicator" 1 "In Neutral Position" 0 "Not in Neutral Position" ;
VAL_ 2365446654 Jystck2GrpXAxsLvrRghtPstvPsSttus 3 "Not Available" 2 "Error Indicator" 1 "On positive side of Neutral" 0 "Not on Positive side of Neutral" ;
VAL_ 2365446654 Jystck2GrpXAxsLvrLftNgtvPsStatus 3 "Not Available" 2 "Error Indicator" 1 "On negative side of Neutral" 0 "Not on negative side of Neutral" ;
VAL_ 2365446654 Jystck2GripXAxisNeutralPosStatus 3 "Not Available" 2 "Error Indicator" 1 "On negative side of Neutral" 0 "Not on negative side of Neutral" ;
VAL_ 2365446654 Jystck2ThtAxsCntrClckwsNgtvPsStt 3 "Not Available" 2 "Error Indicator" 1 "On negative side of Neutral" 0 "Not on negative side of Neutral" ;
VAL_ 2365446142 Jystick1GripXAxisDetentPosStatus 3 "Not Available" 2 "Error Indicator" 1 "In the Detent Position" 0 "Not in the Detent Position" ;
VAL_ 2365446142 Jystick1GripYAxisDetentPosStatus 3 "Not Available" 2 "Error Indicator" 1 "In the Detent Position" 0 "Not in the Detent Position" ;
VAL_ 2365446142 Jystick1ThetaAxisDetentPosStatus 3 "Not Available" 2 "Error Indicator" 1 "In the Detent Position" 0 "Not in the Detent Position" ;
VAL_ 2365446142 Jystck1ThtAxsClckwsPstvPosStatus 3 "Not Available" 2 "Error Indicator" 1 "On positive side of Neutral" 0 "Not on Positive side of Neutral" ;
VAL_ 2365446142 Jystck1ThetaAxisNeutralPosStatus 3 "Not Available" 2 "Error Indicator" 1 "In Neutral Position" 0 "Not in Neutral Position" ;
VAL_ 2365446142 Jystck1GrpYAxsLvrFrwrdPstvPsStts 3 "Not Available" 2 "Error Indicator" 1 "On positive side of Neutral" 0 "Not on Positive side of Neutral" ;
VAL_ 2365446142 Jystck1GrpYAxsLvrBckNgtvPsStatus 3 "Not Available" 2 "Error Indicator" 1 "On negative side of Neutral" 0 "Not on negative side of Neutral" ;
VAL_ 2365446142 Aftrtrtmnt1DslExhstFldPrprtsPrlm 3 "Not Available" 2 "Error Indicator" 1 "In Neutral Position" 0 "Not in Neutral Position" ;
VAL_ 2365446142 Jystck1GrpXAxsLvrRghtPstvPsSttus 3 "Not Available" 2 "Error Indicator" 1 "On positive side of Neutral" 0 "Not on Positive side of Neutral" ;
VAL_ 2365446142 Jystck1GrpXAxsLvrLftNgtvPsStatus 3 "Not Available" 2 "Error Indicator" 1 "On negative side of Neutral" 0 "Not on negative side of Neutral" ;
VAL_ 2365446142 Jystck1GripXAxisNeutralPosStatus 3 "Not Available" 2 "Error Indicator" 1 "In Neutral Position" 0 "Not in Neutral Position" ;
VAL_ 2365446142 Jystck1ThtAxsCntrClckwsNgtvPsStt 3 "Not Available" 2 "Error Indicator" 1 "On negative side of Neutral" 0 "Not on negative side of Neutral" ;
VAL_ 2566810366 FuelPumpPrimerStatus 3 "Unavailable" 2 "Error" 1 "On" 0 "Off" ;
VAL_ 2566810366 EngVentilationStatus 4 "Reserved for SAE assignment" 7 "Not available or not installe" 6 "Not able to determine if sufficiently vented" 5 "Reserved for SAE assignment" 3 "Currently venting engine cranks w/o gas or ignition to clear intake and exhaust systems with air" 2 "Ventilation delay delay without cranking between ventilation and start engine states" 1 "Ventilation needed combustible gases may be present in intake and exhaust systems" 0 "Sufficiently vented all combustible gases have been evacuated from intake and exhaust systems" ;
VAL_ 2566810366 EngCoolantPreheatedState 3 "Not available or not installed" 2 "Unable to determine engine coolant preheated sufficiently" 1 "Sufficiently preheated" 0 "Not sufficiently preheated" ;
VAL_ 2566810366 EngOilPreHeatedState 3 "Not available or not installed" 2 "Unable to determine if engine oil is preheated sufficiently" 1 "Sufficiently preheated" 0 "Not sufficiently preheated" ;
VAL_ 2566810366 EngOilPrimingState 3 "Not available or not installed" 2 "Unable to determine if sufficiently lubricated" 1 "Sufficiently lubricated" 0 "Not sufficiently lubricated" ;
VAL_ 2566810366 EngOilPrimingPumpSwitch 3 "Not available or not installed" 2 "Error" 1 "On" 0 "Off" ;
VAL_ 2633929726 SafetyWireStatus 3 "Not available" 2 "Error" 1 "Safety wire has been activated" 0 "Safety wire has not been activated" ;
VAL_ 2566772222 EngVriableGeometryTurbo1CtrlMode 3 "not available" 2 "SAE reserved" 1 "closed loop" 0 "open loop" ;
VAL_ 2566772222 EngFuelCtrlCtrlMode 3 "Not available" 2 "SAE reserved" 1 "Closed loop" 0 "Open loop" ;
VAL_ 2566772222 EngVrblGmtryTrbArCtrlShtoffValve 3 "Not available" 2 "Reserved" 1 "VGT Air Control Shutoff Valve is On" 0 "VGT Air Control Shutoff Valve is Off" ;
VAL_ 2633940734 EngIntakeManifoldPressCtrlMode 3 "Not available" 2 "SAE reserved" 1 "Closed loop" 0 "Open loop" ;
VAL_ 2633940734 EngRotationDirection 3 "Not Available" 2 "Reserved" 1 "ClockWise CW" 0 "CounterClockWise CCW" ;
VAL_ 2566840318 Aftertreatment2ExhaustDewPoint 3 "Not available" 2 "Error" 1 "Exceeded the dew point" 0 "Not exceeded the dew point" ;
VAL_ 2566840318 Aftertreatment2IntakeDewPoint 3 "Not available" 2 "Error" 1 "Exceeded the dew point" 0 "Not exceeded the dew point" ;
VAL_ 2566840318 Aftertreatment1ExhaustDewPoint 3 "Not available" 2 "Error" 1 "Exceeded the dew point" 0 "Not exceeded the dew point" ;
VAL_ 2566840318 Aftertreatment1IntakeDewPoint 3 "Not available" 2 "Error" 1 "Exceeded the dew point" 0 "Not exceeded the dew point" ;
VAL_ 2364539902 SCRThermalManagementActive 3 "Dont care" 2 "Reserved" 1 "SCR Thermal Management is active" 0 "SCR Thermal Management is not active" ;
VAL_ 2364539902 DPFThermalManagementActive 3 "Dont care" 2 "Reserved" 1 "DPF Thermal Management is active" 0 "DPF Thermal Management is not active" ;
VAL_ 2364539902 MmntaryEngMaxPowerEnableFeedback 3 "dont care" 2 "reserved" 1 "supported" 0 "disabled" ;
VAL_ 2364539902 VhcleAccelerationRateLimitStatus 3 "Not available" 2 "Reserved" 1 "Limit active" 0 "Limit not active" ;
VAL_ 2364539902 AccelPedal2LowIdleSwitch 3 "Not available" 2 "Error" 1 "Accelerator pedal 2 in low idle condition" 0 "Accelerator pedal 2 not in low idle condition" ;
VAL_ 2364539902 RoadSpeedLimitStatus 3 "Not available" 2 "Error" 1 "Not Active" 0 "Active" ;
VAL_ 2364539902 AccelPedalKickdownSwitch 3 "Not available" 2 "Error" 1 "Kickdown active" 0 "Kickdown passive" ;
VAL_ 2364539902 AccelPedal1LowIdleSwitch 3 "Not available" 2 "Error" 1 "Accelerator pedal 1 in low idle condition" 0 "Accelerator pedal 1 not in low idle condition" ;
VAL_ 2364540158 EngStarterMode 11 "Reserved" 10 "starter inhibited due to active SCR inducement" 9 "starter inhibited due to intake air shutoff valve being active" 13 "error legacy implementation only use 1110" 15 "not available" 14 "error" 12 "starter inhibited  reason unknown" 8 "starter inhibited due to starter overtemp" 7 "starter inhibited due to active immobilizer" 6 "starter inhibited due to driveline engaged or other transmission inhibit" 5 "starter inhibited due to engine not ready for start preheating" 4 "starter inhibited due to engine already running" 3 "start finished starter not active after having been actively engaged after 50ms mode goes to 0000" 2 "starter active gear engaged" 1 "starter active gear not engaged" 0 "start not requested" ;
VAL_ 2364540158 ActlEngPrcntTorqueHighResolution 8 "1111  not available" 7 "0875" 1 "0125" 0 "0000" ;
VAL_ 2566767870 EmergencyBrakingActive 3 "not available" 2 "reserved" 1 "active" 0 "inactive" ;
VAL_ 2566767870 PrkngBrakeActuatorFullyActivated 3 "Not available" 2 "Error" 1 "Parking Brake Actuator fully activated" 0 "Parking Brake Actuator not fully activated" ;
VAL_ 2566767870 XBRActiveCtrlMode 15 "Not available" 4 "1110 Reserved for SAE assignment" 3 "Maximum mode of XBR acceleration control being executed" 2 "Addition mode of XBR acceleration control being executed" 1 "Drivers brake demand being executed no external brake demand" 0 "No brake demand being executed default mode" ;
VAL_ 2566767870 XBRSystemState 3 "not available" 2 "No external brake demand will be accepted eg because of fault in brake system" 1 "Only external brake demand of highest XBR Priority 00 will be accepted eg because the temperature limit of the" 0 "Any external brake demand will be accepted brake system fully operational" ;
VAL_ 2566767870 FoundationBrakeUse 3 "Not available" 2 "Reserved" 1 "Foundation brakes in use" 0 "Foundation brakes not in use" ;
VAL_ 2566767870 HillHolderMode 7 "Not available" 6 "Hill holder not functional" 3 "101 Reserved" 2 "Active but will change to inactive in a short time This mode may be used to warn the driver" 1 "Active" 0 "Inactive" ;
VAL_ 2566767870 HaltBrakeMode 7 "Not available" 6 "Reserved" 3 "101 Not defined" 2 "Active but not functioning properly This mode may be used to warn the driver" 1 "Active" 0 "Inactive" ;
VAL_ 2566767870 BrakeTempWarning 3 "not available" 2 "Reserved" 1 "Active" 0 "Not Active" ;
VAL_ 2565865982 TrctrMntdTrailerABSWarningSignal 3 "Take no action" 2 "Reserved" 1 "On" 0 "Off" ;
VAL_ 2565865982 TrailerABSStatus 3 "Trailer ABS Status Information Not Available or Parameter Not Supported" 2 "Reserved" 1 "Trailer ABS Active" 0 "Trailer ABS Status Information Available But Not Active" ;
VAL_ 2565865982 HaltBrakeSwitch 3 "Not available" 2 "Error" 1 "Halt brake switch active" 0 "Halt brake switch passive" ;
VAL_ 2565865982 ATC_ASRInformationSignal 3 "Take no action" 2 "Reserved" 1 "On" 0 "Off" ;
VAL_ 2565865982 ABS_EBSAmberWarningSignal 3 "Take no action" 2 "Reserved" 1 "On" 0 "Off" ;
VAL_ 2565865982 EBSRedWarningSignal 3 "Take no action" 2 "Reserved" 1 "On" 0 "Off" ;
VAL_ 2565865982 ABSFullyOperational 3 "Not available" 2 "Reserved" 1 "Fully Operational" 0 "Not Fully Operational" ;
VAL_ 2565865982 RemoteAccelEnableSwitch 3 "Not available" 2 "Error" 1 "On" 0 "Off" ;
VAL_ 2565865982 EngAuxShutdownSwitch 3 "Not available" 2 "Error" 1 "On" 0 "Off" ;
VAL_ 2565865982 EngDerateSwitch 3 "Not available" 2 "Error" 1 "On" 0 "Off" ;
VAL_ 2565865982 AccelInterlockSwitch 3 "Not available" 2 "Error" 1 "On" 0 "Off" ;
VAL_ 2565865982 TractionCtrlOverrideSwitch 3 "Not available or not installed" 2 "Error" 1 "On" 0 "Off" ;
VAL_ 2565865982 ASRHillHolderSwitch 3 "Not available" 2 "Error" 1 "ASR hill holder switch active" 0 "ASR hill holder switch passive" ;
VAL_ 2565865982 ASROffroadSwitch 2 "Error" 1 "ASR offroad switch active" 0 "ASR offroad switch passive" 3 "Not available" ;
VAL_ 2565865982 ABSOffroadSwitch 3 "Not available" 2 "Error" 1 "ABS offroad switch active" 0 "ABS offroad switch passive" ;
VAL_ 2565865982 EBSBrakeSwitch 3 "Not available" 2 "Error" 1 "Brake pedal is being pressed" 0 "Brake pedal is not being pressed" ;
VAL_ 2565865982 AntiLockBrakingActive 3 "Not available" 2 "Reserved" 1 "ABS active" 0 "ABS passive but installed" ;
VAL_ 2565865982 ASRBrakeCtrlActive 3 "Not available" 2 "Reserved" 1 "ASR brake control active" 0 "ASR brake control passive but installed" ;
VAL_ 2565865982 ASREngCtrlActive 3 "Not available" 2 "Reserved" 1 "ASR engine control active" 0 "ASR engine control passive but installed" ;
VAL_ 2565867262 RearAxleGroupEngagementStatus 3 "not available" 2 "error" 1 "rear axle group engaged" 0 "rear axle group disengaged" ;
VAL_ 2565867262 FrontAxleGroupEngagementStatus 3 "not available" 2 "error" 1 "front axle group engaged" 0 "front axle group disengaged" ;
VAL_ 2565867262 DiffLockStateCentralRear 3 "Not available" 2 "Error" 1 "Differential lock engaged" 0 "Differential lock disengaged" ;
VAL_ 2565867262 DiffLockStateCentralFront 3 "Not available" 2 "Error" 1 "Differential lock engaged" 0 "Differential lock disengaged" ;
VAL_ 2565867262 DiffLockStateCentral 3 "Not available" 2 "Error" 1 "Differential lock engaged" 0 "Differential lock disengaged" ;
VAL_ 2565867262 DiffLockStateRearAxle2 3 "Not available" 2 "Error" 1 "Differential lock engaged" 0 "Differential lock disengaged" ;
VAL_ 2565867262 DiffLockStateRearAxle1 3 "Not available" 2 "Error" 1 "Differential lock engaged" 0 "Differential lock disengaged" ;
VAL_ 2565867262 DiffLockStateFrontAxle2 3 "Not available" 2 "Error" 1 "Differential lock engaged" 0 "Differential lock disengaged" ;
VAL_ 2565867262 DiffLockStateFrontAxle1 3 "Not available" 2 "Error" 1 "Differential lock engaged" 0 "Differential lock disengaged" ;
VAL_ 2566768382 EngCldStrtFlIgniterRelayFeedback 3 "Not available" 2 "Error" 1 "On" 0 "Off" ;
VAL_ 2566768382 EngColdStartFuelIgniterRelay 3 "Dont care/take no action" 2 "Reserved" 1 "On" 0 "Off" ;
VAL_ 2566768382 EngStartEnableDevice2Config 15 "not available" 5 "1110  reserved" 4 "electric intake air heater installed" 3 "ether injection installed" 2 "fuelled start installed" 1 "glow plugs installed" 0 "no start enable device 2 installed" ;
VAL_ 2566768382 EngStartEnableDevice1Config 15 "not available" 5 "1110  reserved" 4 "electric intake air heater installed" 3 "ether injection installed" 2 "fuelled start installed" 1 "glow plugs installed" 0 "no start enable device 1 installed" ;
VAL_ 2566768382 EngStartEnableDevice2 3 "not available" 2 "reserved" 1 "start enable ON" 0 "start enable OFF" ;
VAL_ 2566768382 EngStartEnableDevice1 3 "not available" 2 "reserved" 1 "start enable ON" 0 "start enable OFF" ;
VAL_ 2566771966 TransOilLevelRq 3 "Dont care / take no action" 2 "Reserved" 1 "Transmission oil level reading desired" 0 "No transmission oil level reading desired" ;
VAL_ 2566771966 FifthWheelReleaseCtrl 3 "Not Available" 2 "Error" 1 "Coupler Unlocked trailer can be unhitched or hitched" 0 "Coupler Locked" ;
VAL_ 2566771966 FfthWhlRleaseCtrlSecurityLockout 3 "Not Available" 2 "Error" 1 "Fifth wheel release Enabled" 0 "Fifth wheel release Disabled" ;
VAL_ 2566771966 TransferCaseSelectorSwitch 7 "Not available" 6 "Error indicator" 5 "Reserved for SAE assignment" 4 "4 wheel low or Off Highway Range" 2 "Neutral" 1 "4 wheel high Normal or On Highway Range" 0 "2 wheel high Normal or On Highway Range" 3 "2 wheel low or Off Highway Range" ;
VAL_ 2564882174 RqCabZoneHeating 3 "Dont care/take no action" 2 "Reserved" 1 "Heat cab zone" 0 "Do not cab engine zone" ;
VAL_ 2564882174 RqEngZoneHeating 3 "Dont care/take no action" 2 "Reserved" 1 "Heat engine zone" 0 "Do not heat engine zone" ;
VAL_ 2564882174 AuxHeaterModeRq 15 "Dont care/take no action" 14 "Reserved" 3 "Normal mode" 2 "Economy mode" 1 "Off due to ADR per European Regulations for Transport of hazardous materials" 0 "Deactivate auxiliary heater" ;
VAL_ 2564882174 EngAutomaticStartEnableSwitch 3 "Not available" 2 "Error" 1 "Switch in the on state" 0 "Switch in the off state" ;
VAL_ 2564882174 AtomaticGearShiftingEnableSwitch 3 "11  Not available" 2 "10  Error" 1 "01  Automated Gear Shifting is enabled" 0 "00  Automated Gear Shifting is disabled" ;
VAL_ 2564882174 DslPrtcltFltrRgnrtionForceSwitch 3 "not available" 2 "error" 1 "active" 0 "not active" ;
VAL_ 2564882174 DslPrtcltFltrRgnrtnInhibitSwitch 3 "not available" 2 "error" 1 "active" 0 "not active" ;
VAL_ 2564882174 VhclLmtngSpdGovernorEnableSwitch 3 "Not available" 2 "Error" 1 "Switched enabled" 0 "Switch disabled" ;
VAL_ 2564882174 VhclLmtngSpdGvrnrIncrementSwitch 3 "Not available" 2 "Error" 1 "Switch in the on state  increase" 0 "Switch in the off state" ;
VAL_ 2564882174 VhclLmtngSpdGvrnrDecrementSwitch 3 "Not available" 2 "Error" 1 "Switch in the on state  decrease" 0 "Switch in the off state" ;
VAL_ 2564882174 ParkBrakeCmd 3 "Dont care/Take no action" 2 "SAE Reserved" 1 "Park Brake apply requested" 0 "Park Brake apply not requested" ;
VAL_ 2564882174 SeatBeltSwitch 3 "Not Available" 2 "Error  Switch state cannot be determined" 1 "OK  Seat Belt is buckled" 0 "NOT Buckled" ;
VAL_ 2564882174 OperatorSeatDirectionSwitch 3 "Not Available" 2 "Error" 1 "Operator seat is facing forward" 0 "Operator seat not facing forward" ;
VAL_ 2564882174 BatteryMainSwitchHoldRq 3 "Dont care/take no action" 2 "undefined" 1 "Hold Battery Main Switch" 0 "Release Battery Main Switch" ;
VAL_ 2564882174 AuxHeaterCoolantPumpRq 3 "Dont care/take no action" 2 "Reserved" 1 "Activate water pump" 0 "Deactivate water pump" ;
VAL_ 2566844926 EngShutdownOverrideSwitch 3 "Not available" 2 "Error" 1 "On" 0 "Off" ;
VAL_ 2566844926 EngTestModeSwitch 3 "Not available" 2 "Error" 1 "On" 0 "Off" ;
VAL_ 2566844926 EngIdleDecrementSwitch 3 "Not available" 2 "Error" 1 "On" 0 "Off" ;
VAL_ 2566844926 EngIdleIncrementSwitch 3 "Not available" 2 "Error" 1 "On" 0 "Off" ;
VAL_ 2566844926 CruiseCtrlStates 7 "Not available" 6 "Accelerator Override" 5 "Set" 4 "Resume" 3 "Decelerate" 2 "Accelerate" 1 "Hold" 0 "Off/Disabled" ;
VAL_ 2566844926 PTOGovernorState 31 "Not available" 19 "PTO set speed memory 2" 18 "PTO set speed memory 1" 17 "Preprogrammed set speed 8" 16 "Preprogrammed set speed 7" 15 "Preprogrammed set speed 6" 14 "Preprogrammed set speed 5" 13 "Preprogrammed set speed 4" 12 "Preprogrammed set speed 3" 11 "Preprogrammed set speed 2" 10 "Preprogrammed set speed 1" 9 "Accelerator Override" 8 "Accelerate" 7 "Resume" 6 "Decelerate/Coast" 5 "Set" 4 "Remote Standby" 3 "Standby" 2 "Remote Hold" 1 "Hold" 0 "Off/Disabled" ;
VAL_ 2566844926 CruiseCtrlAccelerateSwitch 3 "Not available" 2 "Error" 1 "Cruise control activator in position accelerate" 0 "Cruise control activator not in the position accelerate" ;
VAL_ 2566844926 CruiseCtrlResumeSwitch 3 "Not available" 2 "Error" 1 "Cruise control activator in position resume" 0 "Cruise control activator not in the position resume" ;
VAL_ 2566844926 CruiseCtrlCoastSwitch 3 "Not available" 2 "Error" 1 "Cruise control activator in position coast" 0 "Cruise control activator not in the position coast" ;
VAL_ 2566844926 CruiseCtrlSetSwitch 3 "Not available" 2 "Error" 1 "Cruise control activator in position set" 0 "Cruise control activator not in the position set" ;
VAL_ 2566844926 ClutchSwitch 3 "Not available" 2 "Error" 1 "Clutch pedal depressed" 0 "Clutch pedal released" ;
VAL_ 2566844926 BrakeSwitch 3 "Not Available" 2 "Error" 1 "Brake pedal depressed" 0 "Brake pedal released" ;
VAL_ 2566844926 CruiseCtrlEnableSwitch 3 "Not available" 2 "Error" 1 "Cruise control enabled" 0 "Cruise control disabled" ;
VAL_ 2566844926 CruiseCtrlActive 3 "Not available" 2 "Error" 1 "Cruise control switched on" 0 "Cruise control switched off" ;
VAL_ 2566844926 ParkBrakeReleaseInhibitRq 3 "Unavailable" 2 "SAEReserved" 1 "ParkBrakeReleaseInhibitRqed" 0 "ParkBrakeReleaseInhibitNotRqed" ;
VAL_ 2566844926 CruiseCtrlPauseSwitch 3 "Take No Action" 2 "Error Indicator" 1 "On" 0 "Off" ;
VAL_ 2566844926 ParkingBrakeSwitch 3 "Not available" 2 "Error" 1 "Parking brake set" 0 "Parking brake not set" ;
VAL_ 2566844926 TwoSpeedAxleSwitch 3 "Not available" 2 "Error" 1 "High speed range" 0 "Low speed range" ;
VAL_ 2566719486 EngFuelFilterRestrictedLampCmd 3 "Not available" 2 "Flash 1 hz" 1 "Lamp On" 0 "Lamp Off" ;
VAL_ 2566719486 EngAirFilterRestrictionLampCmd 3 "Not available" 2 "Reserved" 1 "Lamp On" 0 "Lamp Off" ;
VAL_ 2566719486 EngIdleManagementActiveLampCmd 3 "Not available" 2 "Reserved" 1 "Lamp On" 0 "Lamp Off" ;
VAL_ 2566719486 EngCoolantLevelLowLampCmd 3 "Not available" 2 "Reserved" 1 "Lamp On" 0 "Lamp Off" ;
VAL_ 2566719486 EngCoolantTempHighLampCmd 3 "Not available" 2 "Reserved" 1 "Lamp On" 0 "Lamp Off" ;
VAL_ 2566719486 EngOilPressLowLampCmd 3 "Not available" 2 "Reserved" 1 "Lamp On" 0 "Lamp Off" ;
VAL_ 2566719486 CmprssnBrkEnblSwtchIndctrLampCmd 3 "Not available" 2 "Reserved" 1 "Lamp ON" 0 "Lamp OFF" ;
VAL_ 2566719486 EngBrakeActiveLampCmd 3 "Not available" 2 "Reserved" 1 "Lamp On" 0 "Lamp Off" ;
VAL_ 2566719486 OBDMalfunctionIndicatorLampCmd 3 "Not available" 2 "Reserved" 1 "Lamp On" 0 "Lamp Off" ;
VAL_ 2566719486 EngRedStopLampCmd 3 "Not available" 2 "Reserved" 1 "Lamp On" 0 "Lamp Off" ;
VAL_ 2566719486 EngAmberWarningLampCmd 3 "Not available" 2 "Reserved" 1 "Lamp On" 0 "Lamp Off" ;
VAL_ 2566719486 EngProtectLampCmd 3 "Not available" 2 "Reserved" 1 "Lamp On" 0 "Lamp Off" ;
VAL_ 2633832702 RolloverSensorType 15 "not available" 14 "Error  Type of sensor cannot be determined unknown sensor" 7 "optical sensor" 6 "lidar sensor" 5 "radar sensor" 4 "fiberoptic sensor" 3 "sonic sensor" 2 "rollrate sensor" 1 "pressure sensor" 0 "acceleration sensor" ;
VAL_ 2633832702 RearCollisionSensor4Type 15 "not available" 14 "Error  Type of sensor cannot be determined unknown sensor" 7 "optical sensor" 6 "lidar sensor" 5 "radar sensor" 4 "fiberoptic sensor" 3 "sonic sensor" 2 "rollrate sensor" 1 "pressure sensor" 0 "acceleration sensor" ;
VAL_ 2633832702 RearCollisionSensor3Type 15 "not available" 14 "Error  Type of sensor cannot be determined unknown sensor" 7 "optical sensor" 6 "lidar sensor" 5 "radar sensor" 4 "fiberoptic sensor" 3 "sonic sensor" 2 "rollrate sensor" 1 "pressure sensor" 0 "acceleration sensor" ;
VAL_ 2633832702 RearCollisionSensor2Type 15 "not available" 14 "Error  Type of sensor cannot be determined unknown sensor" 7 "optical sensor" 6 "lidar sensor" 5 "radar sensor" 4 "fiberoptic sensor" 3 "sonic sensor" 2 "rollrate sensor" 1 "pressure sensor" 0 "acceleration sensor" ;
VAL_ 2633832702 RearCollisionSensor1Type 15 "not available" 14 "Error  Type of sensor cannot be determined unknown sensor" 7 "optical sensor" 6 "lidar sensor" 5 "radar sensor" 4 "fiberoptic sensor" 3 "sonic sensor" 2 "rollrate sensor" 1 "pressure sensor" 0 "acceleration sensor" ;
VAL_ 2633832702 SideCollisionSensorRearRightType 15 "not available" 14 "Error  Type of sensor cannot be determined unknown sensor" 7 "optical sensor" 6 "lidar sensor" 5 "radar sensor" 4 "fiberoptic sensor" 3 "sonic sensor" 2 "rollrate sensor" 1 "pressure sensor" 0 "acceleration sensor" ;
VAL_ 2633832702 SdCllisionSensorMidRearRightType 15 "not available" 14 "Error  Type of sensor cannot be determined unknown sensor" 7 "optical sensor" 6 "lidar sensor" 5 "radar sensor" 4 "fiberoptic sensor" 3 "sonic sensor" 2 "rollrate sensor" 1 "pressure sensor" 0 "acceleration sensor" ;
VAL_ 2633832702 SdCllsionSensorMidFrontRightType 15 "not available" 14 "Error  Type of sensor cannot be determined unknown sensor" 7 "optical sensor" 6 "lidar sensor" 5 "radar sensor" 4 "fiberoptic sensor" 3 "sonic sensor" 2 "rollrate sensor" 1 "pressure sensor" 0 "acceleration sensor" ;
VAL_ 2633832702 SdeCollisionSensorFrontRightType 15 "not available" 14 "Error  Type of sensor cannot be determined unknown sensor" 7 "optical sensor" 6 "lidar sensor" 5 "radar sensor" 4 "fiberoptic sensor" 3 "sonic sensor" 2 "rollrate sensor" 1 "pressure sensor" 0 "acceleration sensor" ;
VAL_ 2633832702 SideCollisionSensorRearLeftType 15 "not available" 14 "Error  Type of sensor cannot be determined unknown sensor" 7 "optical sensor" 6 "lidar sensor" 5 "radar sensor" 4 "fiberoptic sensor" 3 "sonic sensor" 2 "rollrate sensor" 1 "pressure sensor" 0 "acceleration sensor" ;
VAL_ 2633832702 SdCollisionSensorMidRearLeftType 15 "not available" 14 "Error  Type of sensor cannot be determined unknown sensor" 7 "optical sensor" 6 "lidar sensor" 5 "radar sensor" 4 "fiberoptic sensor" 3 "sonic sensor" 2 "rollrate sensor" 1 "pressure sensor" 0 "acceleration sensor" ;
VAL_ 2633832702 SdCllisionSensorMidFrontLeftType 15 "not available" 14 "Error  Type of sensor cannot be determined unknown sensor" 7 "optical sensor" 6 "lidar sensor" 5 "radar sensor" 4 "fiberoptic sensor" 3 "sonic sensor" 2 "rollrate sensor" 1 "pressure sensor" 0 "acceleration sensor" ;
VAL_ 2633832702 SideCollisionSensorFrontLeftType 15 "not available" 14 "Error  Type of sensor cannot be determined unknown sensor" 7 "optical sensor" 6 "lidar sensor" 5 "radar sensor" 4 "fiberoptic sensor" 3 "sonic sensor" 2 "rollrate sensor" 1 "pressure sensor" 0 "acceleration sensor" ;
VAL_ 2633832702 FrontalCollisionSensor4Type 15 "not available" 14 "Error  Type of sensor cannot be determined unknown sensor" 7 "optical sensor" 6 "lidar sensor" 5 "radar sensor" 4 "fiberoptic sensor" 3 "sonic sensor" 2 "rollrate sensor" 1 "pressure sensor" 0 "acceleration sensor" ;
VAL_ 2633832702 FrontalCollisionSensor3Type 15 "not available" 14 "Error  Type of sensor cannot be determined unknown sensor" 7 "optical sensor" 6 "lidar sensor" 5 "radar sensor" 4 "fiberoptic sensor" 3 "sonic sensor" 2 "rollrate sensor" 1 "pressure sensor" 0 "acceleration sensor" ;
VAL_ 2633832702 FrontalCollisionSensor2Type 15 "not available" 14 "Error  Type of sensor cannot be determined unknown sensor" 7 "optical sensor" 6 "lidar sensor" 5 "radar sensor" 4 "fiberoptic sensor" 3 "sonic sensor" 2 "rollrate sensor" 1 "pressure sensor" 0 "acceleration sensor" ;
VAL_ 2633832702 FrontalCollisionSensor1Type 15 "not available" 14 "Error  Type of sensor cannot be determined unknown sensor" 7 "optical sensor" 6 "lidar sensor" 5 "radar sensor" 4 "fiberoptic sensor" 3 "sonic sensor" 2 "rollrate sensor" 1 "pressure sensor" 0 "acceleration sensor" ;
VAL_ 2163223550 CrashType 4 "side crash left" 16 "rollover" 8 "side crash right" 2 "rear crash" 1 "frontal crash" ;
